VERSION "0.1"

NS_ :

BS_:

BU_: HVSC Delphi_U2C NLG5 BCM VCL

BO_ 1556 NLG5_ERR: 5 NLG5
 SG_ NLG5_W_PL_MV : 39|1@0+ (1,0) [0|1] ""  HVSC
 SG_ NLG5_W_PL_IT : 37|1@0+ (1,0) [0|1] ""  HVSC
 SG_ NLG5_W_PL_BV : 38|1@0+ (1,0) [0|1] ""  HVSC
 SG_ NLG5_W_C_VOR : 36|1@0+ (1,0) [0|1] ""  HVSC
 SG_ NLG5_E_WDT : 19|1@0+ (1,0) [0|1] ""  HVSC
 SG_ NLG5_E_T_TR : 11|1@0+ (1,0) [0|1] ""  HVSC
 SG_ NLG5_E_T_POW : 13|1@0+ (1,0) [0|1] ""  HVSC
 SG_ NLG5_E_T_EXT3 : 8|1@0+ (1,0) [0|1] ""  HVSC
 SG_ NLG5_E_T_EXT2 : 9|1@0+ (1,0) [0|1] ""  HVSC
 SG_ NLG5_E_T_EXT1 : 10|1@0+ (1,0) [0|1] ""  HVSC
 SG_ NLG5_E_T_DIO : 12|1@0+ (1,0) [0|1] ""  HVSC
 SG_ NLG5_E_T_C : 14|1@0+ (1,0) [0|1] ""  HVSC
 SG_ NLG5_E_SDT_CT : 26|1@0+ (1,0) [0|1] ""  HVSC
 SG_ NLG5_E_SDT_BV : 28|1@0+ (1,0) [0|1] ""  HVSC
 SG_ NLG5_E_SDT_BT : 29|1@0+ (1,0) [0|1] ""  HVSC
 SG_ NLG5_E_SDT_AH : 27|1@0+ (1,0) [0|1] ""  HVSC
 SG_ NLG5_E_SC : 4|1@0+ (1,0) [0|1] ""  HVSC
 SG_ NLG5_E_P_OM : 3|1@0+ (1,0) [0|1] ""  HVSC
 SG_ NLG5_E_P_MV : 2|1@0+ (1,0) [0|1] ""  HVSC
 SG_ NLG5_E_OOV : 7|1@0+ (1,0) [0|1] ""  HVSC
 SG_ NLG5_E_OF : 1|1@0+ (1,0) [0|1] ""  HVSC
 SG_ NLG5_E_NV_CRC : 22|1@0+ (1,0) [0|1] ""  HVSC
 SG_ NLG5_E_MOV_II : 5|1@0+ (1,0) [0|1] ""  HVSC
 SG_ NLG5_E_MOV_I : 6|1@0+ (1,0) [0|1] ""  HVSC
 SG_ NLG5_E_MF : 0|1@0+ (1,0) [0|1] ""  HVSC
 SG_ NLG5_E_INIT : 18|1@0+ (1,0) [0|1] ""  HVSC
 SG_ NLG5_E_F_CRC : 23|1@0+ (1,0) [0|1] ""  HVSC
 SG_ NLG5_E_ES_CRC : 21|1@0+ (1,0) [0|1] ""  HVSC
 SG_ NLG5_E_EP_CRC : 20|1@0+ (1,0) [0|1] ""  HVSC
 SG_ NLG5_E_C_TX : 31|1@0+ (1,0) [0|1] ""  HVSC
 SG_ NLG5_E_C_TO : 17|1@0+ (1,0) [0|1] ""  HVSC
 SG_ NLG5_E_C_RX : 30|1@0+ (1,0) [0|1] ""  HVSC
 SG_ NLG5_E_C_OFF : 16|1@0+ (1,0) [0|1] ""  HVSC
 SG_ NLG5_E_B_P : 15|1@0+ (1,0) [0|1] ""  HVSC

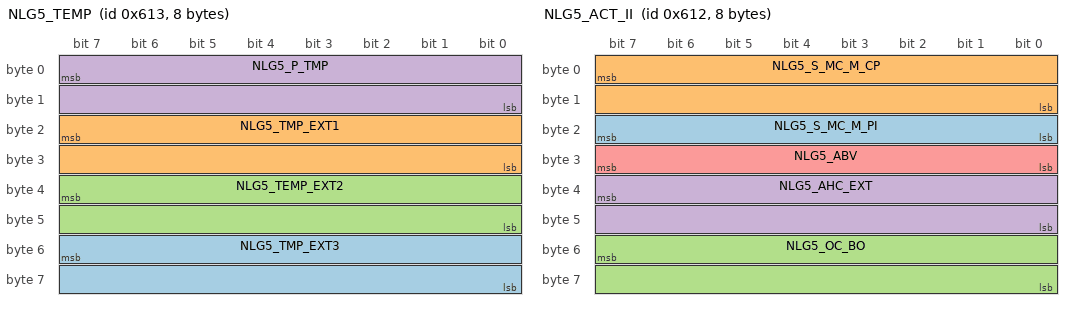
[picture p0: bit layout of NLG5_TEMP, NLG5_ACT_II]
BO_ 1555 NLG5_TEMP: 8 NLG5
 SG_ NLG5_TMP_EXT3 : 55|16@0- (0.1,0) [-40|300] "°C"  HVSC
 SG_ NLG5_TMP_EXT1 : 23|16@0- (0.1,0) [-40|300] "°C"  HVSC
 SG_ NLG5_TEMP_EXT2 : 39|16@0- (0.1,0) [-40|300] "°C"  HVSC
 SG_ NLG5_P_TMP : 7|16@0- (0.1,0) [-40|300] "°C"  HVSC

BO_ 1554 NLG5_ACT_II: 8 NLG5
 SG_ NLG5_S_MC_M_PI : 23|8@0+ (0.1,0) [0|20] "A"  HVSC
 SG_ NLG5_S_MC_M_CP : 7|16@0+ (0.1,0) [0|100] "A"  HVSC
 SG_ NLG5_OC_BO : 55|16@0+ (0.01,0) [0|50] "A"  HVSC
 SG_ NLG5_AHC_EXT : 39|16@0- (0.01,0) [-327.68|327.67] "Ah"  HVSC
 SG_ NLG5_ABV : 31|8@0+ (0.1,0) [0|25] "V"  HVSC

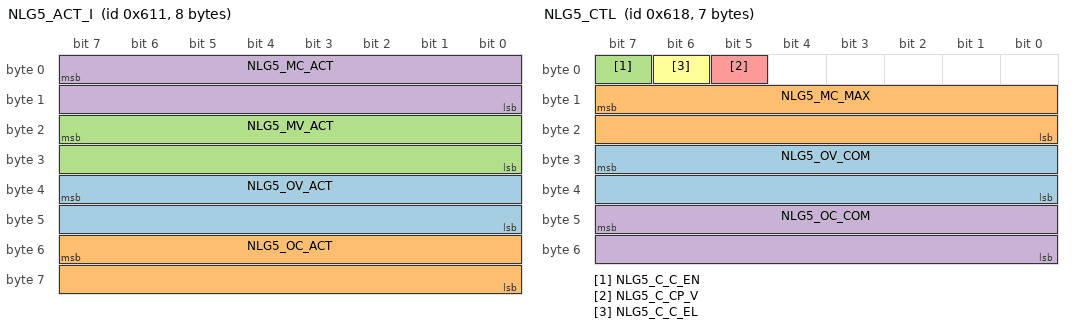
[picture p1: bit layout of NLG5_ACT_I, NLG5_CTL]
BO_ 1553 NLG5_ACT_I: 8 NLG5
 SG_ NLG5_OV_ACT : 39|16@0+ (0.1,0) [0|1000] "V"  HVSC
 SG_ NLG5_OC_ACT : 55|16@0- (0.01,0) [0|150] "A"  HVSC
 SG_ NLG5_MV_ACT : 23|16@0+ (0.1,0) [0|500] "V"  HVSC
 SG_ NLG5_MC_ACT : 7|16@0+ (0.01,0) [0|50] "A"  HVSC

BO_ 1552 NLG5_ST: 4 NLG5
 SG_ NLG5_S_WAR : 5|1@0+ (1,0) [0|1] ""  HVSC
 SG_ NLG5_S_UM_II : 1|1@0+ (1,0) [0|1] ""  HVSC
 SG_ NLG5_S_UM_I : 2|1@0+ (1,0) [0|1] ""  HVSC
 SG_ NLG5_S_HE : 7|1@0+ (1,0) [0|1] ""  HVSC
 SG_ NLG5_S_L_T_TR : 17|1@0+ (1,0) [0|1] ""  HVSC
 SG_ NLG5_S_L_T_POW : 19|1@0+ (1,0) [0|1] ""  HVSC
 SG_ NLG5_S_L_T_DIO : 18|1@0+ (1,0) [0|1] ""  HVSC
 SG_ NLG5_S_L_T_CPRIM : 20|1@0+ (1,0) [0|1] ""  HVSC
 SG_ NLG5_S_L_T_BATT : 16|1@0+ (1,0) [0|1] ""  HVSC
 SG_ NLG5_S_L_PMAX : 8|1@0+ (1,0) [0|1] ""  HVSC
 SG_ NLG5_S_L_PI : 10|1@0+ (1,0) [0|1] ""  HVSC
 SG_ NLG5_S_L_OV : 13|1@0+ (1,0) [0|1] ""  HVSC
 SG_ NLG5_S_L_OC_MAX : 22|1@0+ (1,0) [0|1] ""  HVSC
 SG_ NLG5_S_L_OC : 12|1@0+ (1,0) [0|1] ""  HVSC
 SG_ NLG5_S_L_MO_MAX : 21|1@0+ (1,0) [0|1] ""  HVSC
 SG_ NLG5_S_L_MC_MAX : 23|1@0+ (1,0) [0|1] ""  HVSC
 SG_ NLG5_S_L_MC : 11|1@0+ (1,0) [0|1] ""  HVSC
 SG_ NLG5_S_L_CP : 9|1@0+ (1,0) [0|1] ""  HVSC
 SG_ NLG5_S_FAN : 4|1@0+ (1,0) [0|1] ""  HVSC
 SG_ NLG5_S_EUM : 3|1@0+ (1,0) [0|1] ""  HVSC
 SG_ NLG5_S_ERR : 6|1@0+ (1,0) [0|1] ""  HVSC
 SG_ NLG5_S_CP_DT : 0|1@0+ (1,0) [0|1] ""  HVSC
 SG_ NLG5_S_BPD_II : 14|1@0+ (1,0) [0|1] ""  HVSC
 SG_ NLG5_S_BPD_I : 15|1@0+ (1,0) [0|1] ""  HVSC

BO_ 1560 NLG5_CTL: 7 HVSC
 SG_ NLG5_OV_COM : 31|16@0+ (0.1,0) [0|1000] "V"  NLG5
 SG_ NLG5_MC_MAX : 15|16@0+ (0.1,0) [0|50] "A"  NLG5
 SG_ NLG5_C_C_EN : 7|1@0+ (1,0) [0|1] ""  NLG5
 SG_ NLG5_OC_COM : 47|16@0+ (0.1,0) [0|150] "A"  NLG5
 SG_ NLG5_C_CP_V : 5|1@0+ (1,0) [0|1] ""  NLG5
 SG_ NLG5_C_C_EL : 6|1@0+ (1,0) [0|1] ""  NLG5

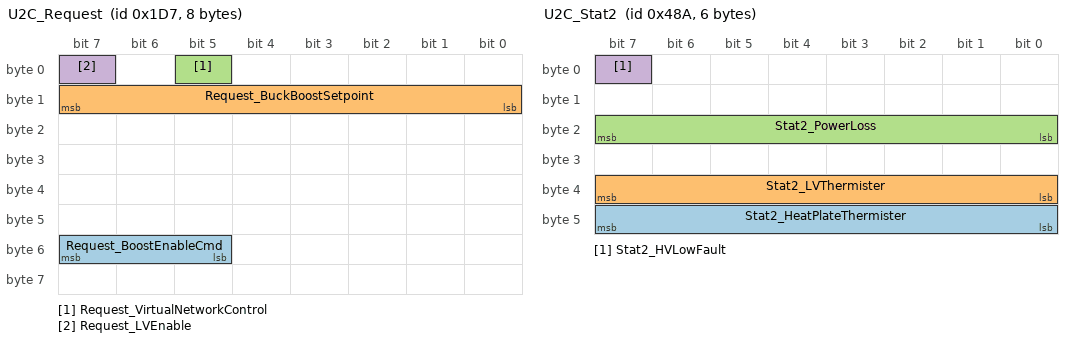
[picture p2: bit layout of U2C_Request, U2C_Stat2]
BO_ 471 U2C_Request: 8 HVSC
 SG_ Request_BoostEnableCmd : 53|3@1- (1,0) [0|0] ""  Delphi_U2C
 SG_ Request_BuckBoostSetpoint : 8|8@1+ (1,0) [0|255] ""  Delphi_U2C
 SG_ Request_VirtualNetworkControl : 5|1@1- (1,0) [0|0] ""  Delphi_U2C
 SG_ Request_LVEnable : 7|1@1- (1,0) [0|0] ""  Delphi_U2C

BO_ 1162 U2C_Stat2: 6 Delphi_U2C
 SG_ Stat2_HeatPlateThermister : 40|8@1- (1,-40) [0|0] ""  HVSC
 SG_ Stat2_LVThermister : 32|8@1- (1,-40) [0|0] ""  HVSC
 SG_ Stat2_PowerLoss : 16|8@1- (2,0) [0|0] "Watts"  HVSC
 SG_ Stat2_HVLowFault : 7|1@1- (1,0) [0|0] ""  HVSC

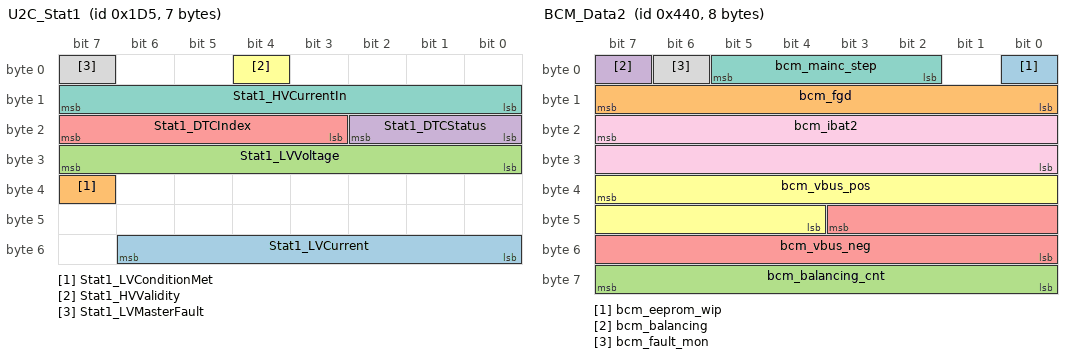
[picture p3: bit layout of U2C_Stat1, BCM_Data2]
BO_ 469 U2C_Stat1: 7 Delphi_U2C
 SG_ Stat1_LVCurrent : 48|7@1+ (2,0) [0|254] "Amps"  HVSC
 SG_ Stat1_LVConditionMet : 39|1@1+ (1,0) [0|1] ""  HVSC
 SG_ Stat1_LVVoltage : 24|8@1+ (0.078431,0) [0|0] "Volts"  HVSC
 SG_ Stat1_DTCStatus : 16|3@1+ (1,0) [0|7] ""  HVSC
 SG_ Stat1_DTCIndex : 19|5@1+ (1,0) [0|31] ""  HVSC
 SG_ Stat1_HVValidity : 4|1@1+ (1,0) [0|1] ""  HVSC
 SG_ Stat1_HVCurrentIn : 8|8@1+ (0.1,0) [0|0] "Amps"  HVSC
 SG_ Stat1_LVMasterFault : 7|1@1+ (1,0) [0|1] ""  HVSC

BO_ 1088 BCM_Data2: 8 BCM
 SG_ bcm_eeprom_wip : 0|1@0+ (1,0) [0|1] "flag"  VCL
 SG_ bcm_fgd : 15|8@0+ (0.5,0) [0|100] "% Duty Cycle"  VCL
 SG_ bcm_balancing_cnt : 63|8@0+ (1,0) [0|250] "cells"  VCL
 SG_ bcm_balancing : 7|1@0+ (1,0) [0|1] "flag"  VCL
 SG_ bcm_vbus_neg : 43|12@0+ (0.25,-500) [-500|500] "volts"  VCL
 SG_ bcm_vbus_pos : 39|12@0+ (0.25,0) [0|1000] "volts"  VCL
 SG_ bcm_mainc_step : 5|4@0+ (1,0) [0|15] "enum"  VCL
 SG_ bcm_fault_mon : 6|1@0+ (1,0) [0|1] "flag"  VCL
 SG_ bcm_ibat2 : 23|16@0+ (0.025,-1000) [-1000|500] "amps"  VCL

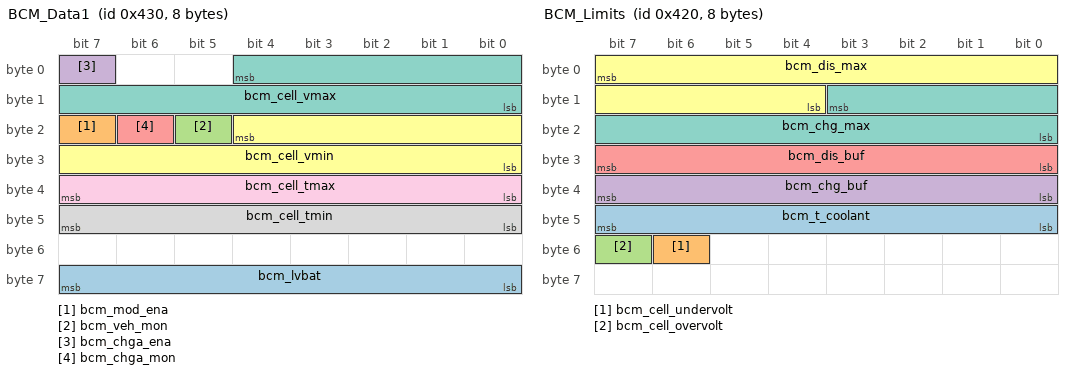
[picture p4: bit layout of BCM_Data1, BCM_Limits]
BO_ 1072 BCM_Data1: 8 BCM
 SG_ bcm_lvbat : 63|8@0+ (0.1,0) [0|25] "Volts" Vector__XXX
 SG_ bcm_mod_ena : 23|1@0+ (1,0) [0|1] "flag" Vector__XXX
 SG_ bcm_veh_mon : 21|1@0+ (1,0) [0|1] "flag" Vector__XXX
 SG_ bcm_chga_ena : 7|1@0+ (1,0) [0|1] "flag" Vector__XXX
 SG_ bcm_chga_mon : 22|1@0+ (1,0) [0|1] "flag" Vector__XXX
 SG_ bcm_cell_vmin : 20|13@0+ (0.001,0) [0|5] "volts"  VCL
 SG_ bcm_cell_vmax : 4|13@0+ (0.001,0) [0|5] "volts"  VCL
 SG_ bcm_cell_tmin : 47|8@0+ (0.5,-40) [-40|85] "DegC"  VCL
 SG_ bcm_cell_tmax : 39|8@0+ (0.5,-40) [-40|85] "DegC"  VCL

BO_ 1056 BCM_Limits: 8 BCM
 SG_ bcm_t_coolant : 47|8@0+ (0.5,-40) [-40|85] "DegC"  VCL
 SG_ bcm_cell_undervolt : 54|1@0+ (1,0) [0|1] "flag" Vector__XXX
 SG_ bcm_cell_overvolt : 55|1@0+ (1,0) [0|1] "flag" Vector__XXX
 SG_ bcm_chg_buf : 39|8@0+ (0.5,0) [0|100] "%" Vector__XXX
 SG_ bcm_dis_buf : 31|8@0+ (0.5,0) [0|100] "%" Vector__XXX
 SG_ bcm_dis_max : 7|12@0+ (0.25,0) [0|1000] "amps"  VCL,HVSC
 SG_ bcm_chg_max : 11|12@0+ (0.25,0) [0|1000] "amps"  VCL,HVSC

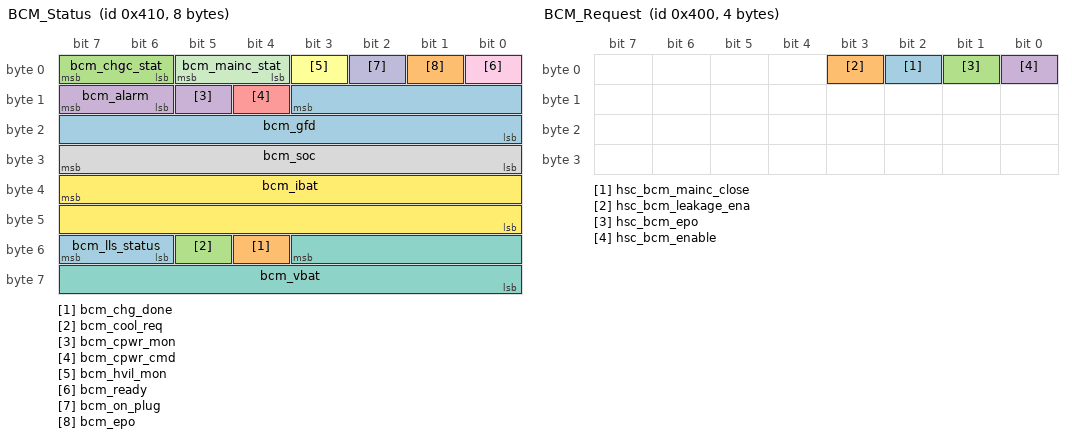
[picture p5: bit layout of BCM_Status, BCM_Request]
BO_ 1040 BCM_Status: 8 BCM
 SG_ bcm_lls_status : 55|2@0+ (1,0) [0|3] "state" Vector__XXX
 SG_ bcm_chg_done : 52|1@0+ (1,0) [0|1] "flag" Vector__XXX
 SG_ bcm_cool_req : 53|1@0+ (1,0) [0|1] "flag" Vector__XXX
 SG_ bcm_cpwr_mon : 13|1@0+ (1,0) [0|1] "flag" Vector__XXX
 SG_ bcm_cpwr_cmd : 12|1@0+ (1,0) [0|1] "flag" Vector__XXX
 SG_ bcm_hvil_mon : 3|1@0+ (1,0) [0|1] "flag" Vector__XXX
 SG_ bcm_vbat : 51|12@0+ (0.25,0) [0|1000] "volts"  VCL,HVSC
 SG_ bcm_soc : 31|8@0+ (0.5,0) [0|100] "%"  VCL,HVSC
 SG_ bcm_ready : 0|1@0+ (1,0) [0|1] "flag"  VCL,HVSC
 SG_ bcm_on_plug : 2|1@0+ (1,0) [0|1] "flag"  VCL,HVSC
 SG_ bcm_mainc_stat : 5|2@0+ (1,0) [0|2] "enum"  VCL,HVSC
 SG_ bcm_ibat : 39|16@0+ (0.025,-1000) [-1000|500] "amps"  VCL,HVSC
 SG_ bcm_gfd : 11|12@0+ (0.25,0) [0|1000] "kOhm"  VCL,HVSC
 SG_ bcm_epo : 1|1@0+ (1,0) [0|1] "flag"  VCL,HVSC
 SG_ bcm_chgc_stat : 7|2@0+ (1,0) [0|2] "enum"  VCL,HVSC
 SG_ bcm_alarm : 15|2@0+ (1,0) [0|3] "enum"  VCL,HVSC

BO_ 1024 BCM_Request: 4 HVSC
 SG_ hsc_bcm_mainc_close : 2|1@0+ (1,0) [0|1] "flag"  VCL,BCM
 SG_ hsc_bcm_leakage_ena : 3|1@0+ (1,0) [0|1] "flag"  VCL,BCM
 SG_ hsc_bcm_epo : 1|1@0+ (1,0) [0|1] "flag"  VCL,BCM
 SG_ hsc_bcm_enable : 0|1@0+ (1,0) [0|1] "flag"  VCL,BCM

BO_ 1120 BCM_Faults: 8 BCM
 SG_ bcm_dtc_type3 m0 : 47|8@0+ (1,0) [0|255] "DTCs"  HVSC
 SG_ bcm_dtc_type2 m0 : 39|8@0+ (1,0) [0|255] "DTCs"  HVSC
 SG_ bcm_dtc_type1 m0 : 31|8@0+ (1,0) [0|255] "DTCs"  HVSC
 SG_ bcm_dtc_testFailedThisOpCycle m0 : 55|8@0+ (1,0) [0|255] "DTCs"  HVSC
 SG_ bcm_dtc_pages m0 : 23|8@0+ (1,0) [0|255] "page count"  HVSC
 SG_ bcm_dtc_fault_detected m0 : 63|8@0+ (1,0) [0|255] "DTCs"  HVSC
 SG_ bcm_dtc_001 m1 : 23|24@0+ (1,0) [0|16777215] "DTC ID"  HVSC
 SG_ bcm_dtc_002 m1 : 47|24@0+ (1,0) [0|16777215] "DTC ID"  HVSC
 SG_ bcm_dtc_003 m2 : 23|24@0+ (1,0) [0|16777215] "DTC ID"  HVSC
 SG_ bcm_dtc_004 m2 : 47|24@0+ (1,0) [0|16777215] "DTC ID"  HVSC
 SG_ bcm_dtc_005 m3 : 23|24@0+ (1,0) [0|16777215] "DTC ID"  HVSC
 SG_ bcm_dtc_006 m3 : 47|24@0+ (1,0) [0|16777215] "DTC ID"  HVSC
 SG_ bcm_dtc_007 m4 : 23|24@0+ (1,0) [0|16777215] "DTC ID"  HVSC
 SG_ bcm_dtc_008 m4 : 47|24@0+ (1,0) [0|16777215] "DTC ID"  HVSC
 SG_ bcm_dtc_009 m5 : 23|24@0+ (1,0) [0|16777215] "DTC ID"  HVSC
 SG_ bcm_dtc_010 m5 : 47|24@0+ (1,0) [0|16777215] "DTC ID"  HVSC
 SG_ bcm_dtc_011 m6 : 23|24@0+ (1,0) [0|16777215] "DTC ID"  HVSC
 SG_ bcm_dtc_012 m6 : 47|24@0+ (1,0) [0|16777215] "DTC ID"  HVSC
 SG_ bcm_dtc_013 m7 : 23|24@0+ (1,0) [0|16777215] "DTC ID"  HVSC
 SG_ bcm_dtc_014 m7 : 47|24@0+ (1,0) [0|16777215] "DTC ID"  HVSC
 SG_ bcm_dtc_015 m8 : 23|24@0+ (1,0) [0|16777215] "DTC ID"  HVSC
 SG_ bcm_dtc_016 m8 : 47|24@0+ (1,0) [0|16777215] "DTC ID"  HVSC
 SG_ bcm_dtc_017 m9 : 23|24@0+ (1,0) [0|16777215] "DTC ID"  HVSC
 SG_ bcm_dtc_018 m9 : 47|24@0+ (1,0) [0|16777215] "DTC ID"  HVSC
 SG_ bcm_dtc_page M : 7|8@0+ (1,0) [0|255] "page number"  HVSC

CM_ SG_ 1556 NLG5_W_PL_MV "Output power limited by low mains voltage";
CM_ SG_ 1556 NLG5_W_PL_IT "Output power limited by charger internal overtemperature";
CM_ SG_ 1556 NLG5_W_PL_BV "Output power limited by low battery voltage";
CM_ SG_ 1556 NLG5_W_C_VOR "Commanded value is out of specified range; max or min applicable value is assumed instead";
CM_ SG_ 1556 NLG5_E_WDT "Internal Watchdog Timeout";
CM_ SG_ 1556 NLG5_E_T_TR "Temperature sensor for transformer defective";
CM_ SG_ 1556 NLG5_E_T_POW "Temperature sensor for prim power stage defective";
CM_ SG_ 1556 NLG5_E_T_EXT3 "Ext. temperature sensor 3 defective (if enabled)";
CM_ SG_ 1556 NLG5_E_T_EXT2 "Ext. temperature sensor 2 defective (if enabled)";
CM_ SG_ 1556 NLG5_E_T_EXT1 "Ext. temperature sensor 1 defective (if enabled)";
CM_ SG_ 1556 NLG5_E_T_DIO "Temperature sensor for diodes defective";
CM_ SG_ 1556 NLG5_E_T_C "Temperature sensor for prim capacitor defective";
CM_ SG_ 1556 NLG5_E_SDT_CT "Emergency Shutdown Threshold 'Charging Time' is exceeded; see ChargeStar help section 'protective features';  error can only be cleared by cycling power ON-OFF-ON";
CM_ SG_ 1556 NLG5_E_SDT_BV "Emergency Shutdown Threshold 'Battery Voltage' is exceeded; see ChargeStar help section 'protective features';  error can only be cleared by cycling power ON-OFF-ON";
CM_ SG_ 1556 NLG5_E_SDT_BT "Emergency Shutdown Threshold 'Battery Temperature' is exceeded; see ChargeStar help section 'protective features';  error can only be cleared by cycling power ON-OFF-ON";
CM_ SG_ 1556 NLG5_E_SDT_AH "Emergency Shutdown Threshold 'Amp Hours' is exceeded; see ChargeStar help section 'protective features';  error can only be cleared by cycling power ON-OFF-ON";
CM_ SG_ 1556 NLG5_E_SC "power stage short circuit condition detected; error can only be cleared by cycling power ON-OFF-ON";
CM_ SG_ 1556 NLG5_E_P_OM "plausibility battery output voltage measurement wrong";
CM_ SG_ 1556 NLG5_E_P_MV "plausibility mains voltage measurement wrong";
CM_ SG_ 1556 NLG5_E_OOV "battery output overvoltage; error can only be cleared by cycling power ON-OFF-ON ";
CM_ SG_ 1556 NLG5_E_OF "output fuse defective";
CM_ SG_ 1556 NLG5_E_NV_CRC "NVSRAM check sum failure; contains most of the scaling & calibration values, CAN ID's and  charging profile etc.";
CM_ SG_ 1556 NLG5_E_MOV_II "Mains overvoltage 2 detected";
CM_ SG_ 1556 NLG5_E_MOV_I "Mains overvoltage 1 detected";
CM_ SG_ 1556 NLG5_E_MF "Mains fuse defective";
CM_ SG_ 1556 NLG5_E_INIT "Initialization error";
CM_ SG_ 1556 NLG5_E_F_CRC "Flash memory checksum failure";
CM_ SG_ 1556 NLG5_E_ES_CRC "Sys EEPROM checksum failure";
CM_ SG_ 1556 NLG5_E_EP_CRC "Pow EEPROM checksum failure";
CM_ SG_ 1556 NLG5_E_C_TX "CAN transmit buffer >127";
CM_ SG_ 1556 NLG5_E_C_TO "CAN timeout, no control message received for >300ms";
CM_ SG_ 1556 NLG5_E_C_RX "CAN receiver buffer >127";
CM_ SG_ 1556 NLG5_E_C_OFF "CAN off, transmit buffer >255";
CM_ SG_ 1556 NLG5_E_B_P "wrong battery polarity;  error can only be cleared by cycling power ON-OFF-ON";
CM_ SG_ 1555 NLG5_TMP_EXT3 "Value of external battery temperature sensor #3 (if connected and enabled)";
CM_ SG_ 1555 NLG5_TMP_EXT1 "Value of external battery temperature sensor #1 (if connected and enabled)";
CM_ SG_ 1555 NLG5_TEMP_EXT2 "Value of external battery temperature sensor #2 (if connected and enabled)";
CM_ SG_ 1555 NLG5_P_TMP "Power stage temperature";
CM_ SG_ 1554 NLG5_S_MC_M_PI "Value of mains current limit, commanded by the 'power indicator' (PI) analog input signal";
CM_ SG_ 1554 NLG5_S_MC_M_CP "Value of mains current limit, commanded by the control pilot (SAE J1772) signal";
CM_ SG_ 1554 NLG5_OC_BO "output current of the booster (if one is present and active)";
CM_ SG_ 1554 NLG5_AHC_EXT "Charge balance obtained via  Ext. Ah counter connected to DI1 / DI2";
CM_ SG_ 1554 NLG5_ABV "Aux battery voltage";
CM_ SG_ 1553 NLG5_OV_ACT "Actual battery output voltage";
CM_ SG_ 1553 NLG5_OC_ACT "output current to the battery";
CM_ SG_ 1553 NLG5_MV_ACT "Actual mains voltage";
CM_ SG_ 1553 NLG5_MC_ACT "Actual mains current";
CM_ SG_ 1552 NLG5_S_WAR "Warning condition on, i.e. charging power limited due to any limiting condition; red LED is blinking";
CM_ SG_ 1552 NLG5_S_UM_II "US mains level 2 (240VAC / 60Hz) detected";
CM_ SG_ 1552 NLG5_S_UM_I "US mains level 1 (120VAC / 60Hz) detected";
CM_ SG_ 1552 NLG5_S_HE "Indicates if hardware enabled, i.e. a hi or lo signal is fed to the 'Power On' pin (pin3 of control connector)";
CM_ SG_ 1552 NLG5_S_L_T_TR "Output power limited by temperature of transformer";
CM_ SG_ 1552 NLG5_S_L_T_POW "Output power limited by temperature of power stage";
CM_ SG_ 1552 NLG5_S_L_T_DIO "Output power limited by temperature of diodes";
CM_ SG_ 1552 NLG5_S_L_T_CPRIM "Output power limited by temperature of primary capacitors";
CM_ SG_ 1552 NLG5_S_L_T_BATT "Output power limited by battery temperature";
CM_ SG_ 1552 NLG5_S_L_PMAX "Output power limited by maximum power capability of NLG5";
CM_ SG_ 1552 NLG5_S_L_PI "Output power limited by analog input 'power indicator' (PI) limit";
CM_ SG_ 1552 NLG5_S_L_OV "Output power limited by battery output voltage limit";
CM_ SG_ 1552 NLG5_S_L_OC_MAX "Output power limited by maximum output current capability of NLG5";
CM_ SG_ 1552 NLG5_S_L_OC "Output power limited by battery output current limit";
CM_ SG_ 1552 NLG5_S_L_MO_MAX "Output power limited by maximum output voltage capability of NLG5";
CM_ SG_ 1552 NLG5_S_L_MC_MAX "Output power limited by maximum mains current capability of NLG5";
CM_ SG_ 1552 NLG5_S_L_MC "Output power limited by mains current limit";
CM_ SG_ 1552 NLG5_S_L_CP "Output power limited by control pilot signal (SAE J1772)";
CM_ SG_ 1552 NLG5_S_FAN "Charger cooling fan is active";
CM_ SG_ 1552 NLG5_S_EUM "European mains input detected (230V, 50Hz)";
CM_ SG_ 1552 NLG5_S_ERR "An error has been detected, red LED is ON, no power is output";
CM_ SG_ 1552 NLG5_S_CP_DT "Control pilot signal (SAE J1772) detected ";
CM_ SG_ 1552 NLG5_S_BPD_II "Bypass detection bit 2; 00: no bypass, 01: DC bypass detected, 10:AC bypass in phase, 11: AC bypass not in phase";
CM_ SG_ 1552 NLG5_S_BPD_I "Bypass detection bit 1; 00: no bypass, 01: DC bypass detected, 10:AC bypass in phase, 11: AC bypass not in phase";
CM_ SG_ 1560 NLG5_OV_COM "Desired voltage to be output to the battery. Must always contain a valid value in order to keep on charging.";
CM_ SG_ 1560 NLG5_MC_MAX "Maximum current to be drawn from the mains outlet, usually 16A. Must always contain a valid value in order to keep on charging.";
CM_ SG_ 1560 NLG5_C_C_EN "Must be ON to enable power stage of the charger";
CM_ SG_ 1560 NLG5_OC_COM "Desired battery current. Must always contain a valid value in order to keep on charging.";
CM_ SG_ 1560 NLG5_C_CP_V "special signal to tell a charging station equipped with the Control Pilot interface (SAE J1772) to switch on the facility's ventilation (in order to get rid of battery gases like hydrogen, e.g.)";
CM_ SG_ 1560 NLG5_C_C_EL "cycle this value 0-1-0 to clear all latched charger errors ";
CM_ SG_ 471 Request_BoostEnableCmd "Selects Boost conversion on/off";
CM_ SG_ 471 Request_BuckBoostSetpoint "CAN byte (dec) = (Buck Target Voltage * 45.3329) - 473.161";
CM_ SG_ 1088 bcm_eeprom_wip "BCM fault status: EEPROM write in progress.";
CM_ SG_ 1088 bcm_fgd "Flammable gas detector duty cycle (most severe).";
CM_ SG_ 1088 bcm_balancing_cnt "Number of cells currently balancing.";
CM_ SG_ 1088 bcm_balancing "Charge balance circuits are active.";
CM_ SG_ 1088 bcm_vbus_neg "HV bus negative voltage measurement.";
CM_ SG_ 1088 bcm_vbus_pos "HV bus positive voltage measurement.";
CM_ SG_ 1088 bcm_mainc_step "Main contactor control state enumeration.";
CM_ SG_ 1088 bcm_fault_mon "Module Fault monitor, indicates if of the modules triggered a hardware based fault (0=low, 1=high).";
CM_ SG_ 1088 bcm_ibat2 "[Development Sensor] HV Battery Current where negative is battery discharge and positive is battery charge.";
CM_ SG_ 1072 bcm_lvbat "SLI Battery Voltage.";
CM_ SG_ 1072 bcm_mod_ena "Module 12V enable command (0=off, 1=on).";
CM_ SG_ 1072 bcm_veh_mon "Vehicle wakeup monitor (0=low, 1=high).";
CM_ SG_ 1072 bcm_chga_ena "Charger enable command (0=off, 1=on).";
CM_ SG_ 1072 bcm_chga_mon "Charger AC wakeup monitor (0=low, 1=high).";
CM_ SG_ 1072 bcm_cell_vmin "Min cell voltage.";
CM_ SG_ 1072 bcm_cell_vmax "Max cell voltage.";
CM_ SG_ 1072 bcm_cell_tmin "Min cell case temperature.";
CM_ SG_ 1072 bcm_cell_tmax "Max cell case temperature.";
CM_ SG_ 1056 bcm_t_coolant "Battery coolant temperature sensor value.";
CM_ SG_ 1056 bcm_cell_undervolt "One or more cells are below normal voltage range.";
CM_ SG_ 1056 bcm_cell_overvolt "One or more cells are above normal voltage range.";
CM_ SG_ 1056 bcm_chg_buf "Transient acceptance indicator, how soon before the BCM will start to limit it's max charge current.
100% - large buffer to accept charge up to bcm_chg_max.
0% - bcm_chg_max is being reduced to steady-state level.";
CM_ SG_ 1056 bcm_dis_buf "Transient acceptance indicator, how soon before the BCM will start to limit it's max discharge current.
100% - large buffer to accept discharge up to bcm_dis_max.
0% - bcm_dis_max is being reduced to steady-state level.";
CM_ SG_ 1056 bcm_dis_max "Max allowed discharge current.";
CM_ SG_ 1056 bcm_chg_max "Max allowed charge current.";
CM_ SG_ 1040 bcm_lls_status "Liquid level sensor located mid-pack.  FAULT indicates that Liquid was detected within the pack.";
CM_ SG_ 1040 bcm_chg_done "Charging is complete.";
CM_ SG_ 1040 bcm_cool_req "Battey cell temperaure indicates cooling required, the vehicle should activate the cooling pump and target bcm_t_coolant <= 20C.";
CM_ SG_ 1040 bcm_cpwr_mon "Contactor Power Relay monitor (0=low, 1=high).";
CM_ SG_ 1040 bcm_cpwr_cmd "Contactor Power Relay command state (0=off, 1=on).";
CM_ SG_ 1040 bcm_hvil_mon "HVIL monitor (0=low, 1=high).";
CM_ SG_ 1040 bcm_vbat "HV Battery voltage measurement.";
CM_ SG_ 1040 bcm_soc "Battery State of Charge.";
CM_ SG_ 1040 bcm_ready "BCM completed Power On Self Test and is ready.";
CM_ SG_ 1040 bcm_on_plug "Charger is plugged into AC socket, use an an input to start/drive-away logic.";
CM_ SG_ 1040 bcm_mainc_stat "Main contactor status.";
CM_ SG_ 1040 bcm_ibat "HV Battery Current where negative is battery discharge and positive is battery charge.";
CM_ SG_ 1040 bcm_gfd "Ground fault detection result.";
CM_ SG_ 1040 bcm_epo "BCM Emergency Power Off status.";
CM_ SG_ 1040 bcm_chgc_stat "Charge contactor status.";
CM_ SG_ 1040 bcm_alarm "Alarm condition from the BCM indicating overall condition.";
CM_ SG_ 1024 hsc_bcm_mainc_close "Vehicle main contactor command.";
CM_ SG_ 1024 hsc_bcm_leakage_ena "Vehicle leakage detection enabled (bcm_gfd calculation).";
CM_ SG_ 1024 hsc_bcm_epo "Vehicle Emergency Power Off command, fast shutdown.";
CM_ SG_ 1024 hsc_bcm_enable "Flag from vehicle controller allowing BCM to accept commands.";
BA_DEF_  "Bus Speed" STRING ;
BA_DEF_ SG_  "GenSigStartValue" INT 0 0;
BA_DEF_ SG_  "GenSigSendType" ENUM  "Cyclic","OnWrite","OnWriteWithRepetition","OnChange","OnChangeWithRepetition","IfActive","IfActiveWithRepetition","NoSigSendType";
BA_DEF_ BO_  "GenMsgCycleTime" INT 0 0;
BA_DEF_ BO_  "GenMsgSendType" ENUM  "Cyclic","not_used","not_used","not_used","not_used","Cyclic","not_used","IfActive","NoMsgSendType";
BA_DEF_  "DBName" STRING ;
BA_DEF_  "BusType" STRING ;
BA_DEF_DEF_  "Bus Speed" "500k";
BA_DEF_DEF_  "GenSigStartValue" 0;
BA_DEF_DEF_  "GenSigSendType" "Cyclic";
BA_DEF_DEF_  "GenMsgCycleTime" 10;
BA_DEF_DEF_  "GenMsgSendType" "NoMsgSendType";
BA_DEF_DEF_  "DBName" "HybridExpansion";
BA_DEF_DEF_  "BusType" "CAN";
BA_ "GenSigStartValue" SG_ 1072 bcm_cell_tmin 130;
BA_ "GenSigStartValue" SG_ 1072 bcm_cell_tmax 130;
VAL_ 471 Request_BoostEnableCmd 5 "Aborted" 4 "Complete" 3 "Active" 2 "Ready" 1 "Required" 0 "Inactive" ;
VAL_ 469 Stat1_DTCStatus 4 "Diagnostic Failed" 3 "Diagnostic Passed" 2 "No Status to Report" 1 "Critically Disabled" 0 "Not Supported" ;
VAL_ 469 Stat1_DTCIndex 31 "Reserved" 30 "Reserved" 29 "Reserved" 28 "Reserved" 27 "Reserved" 26 "Reserved" 25 "Reserved" 24 "Reserved" 23 "Reserved" 22 "Reserved" 21 "Reserved" 20 "Reserved" 19 "Reserved" 18 "ILIM Occured Indication" 17 "14V ILIM Diagnostic" 16 "Current Balance Diagnostic" 15 "14V Current Diagnostic" 14 "Heat Plate Temperature Fault" 13 "Loss of COM (3 Second Timeout)" 12 "Boost On Hi Voltage Fault - Low" 11 "Unused" 10 "Unused" 9 "Unused" 8 "Buck On Voltage Fault - Low" 7 "Low Voltage Fault - Low" 6 "Low Voltage Fault - High" 5 "Unused" 4 "Unused" 3 "High Voltage Fault - Low" 2 "High Voltage Fault - High" 1 "Unused" 0 "Low Voltage System Fault" ;
VAL_ 1088 bcm_fgd 255 "ERROR" 254 "NO_VALUE" ;
VAL_ 1088 bcm_balancing_cnt 255 "ERROR" 254 "NO_VALUE" ;
VAL_ 1088 bcm_vbus_neg 4095 "ERROR" 4094 "NO_VALUE" ;
VAL_ 1088 bcm_vbus_pos 4095 "ERROR" 4094 "NO_VALUE" ;
VAL_ 1088 bcm_mainc_step 14 "ALL_OPEN_SHUTDOWN" 13 "SHUTDOWN_REQUEST" 12 "MAIN_P_CLOSED_CHARGE" 11 "MAIN_PN_CLOSED_DRIVE" 10 "FAILED_MAINP_OPEN" 9 "OPEN_MAINR" 8 "CLOSE_MAINP" 7 "WAIT_PRECHARGE" 6 "FAILED_MAINN_OPEN" 5 "CLOSE_MAINN" 4 "FAILED_MAINN_WELD" 3 "FAILED_MAINR_OPEN" 2 "CLOSE_MAINR" 1 "FAILED_MAINP_OR_R_WELD" 0 "ALL_OPEN" ;
VAL_ 1088 bcm_ibat2 65534 "NO_VALUE" 65535 "ERROR" ;
VAL_ 1072 bcm_lvbat 255 "ERROR" 254 "NO_VALUE" ;
VAL_ 1072 bcm_cell_vmin 8191 "ERROR" 8190 "NO_VALUE" ;
VAL_ 1072 bcm_cell_vmax 8191 "ERROR" 8190 "NO_VALUE" ;
VAL_ 1072 bcm_cell_tmin 255 "ERROR" 254 "NO_VALUE" ;
VAL_ 1072 bcm_cell_tmax 255 "ERROR" 254 "NO_VALUE" ;
VAL_ 1056 bcm_t_coolant 255 "ERROR" 254 "NO_VALUE" ;
VAL_ 1056 bcm_chg_buf 255 "ERROR" 254 "NO_VALUE" ;
VAL_ 1056 bcm_dis_buf 255 "ERROR" 254 "NO_VALUE" ;
VAL_ 1056 bcm_dis_max 4095 "ERROR" 4094 "NO_VALUE" ;
VAL_ 1056 bcm_chg_max 4095 "ERROR" 4094 "NO_VALUE" ;
VAL_ 1040 bcm_lls_status 3 "OOR_HIGH" 2 "OOR_LOW" 1 "FAULT" 0 "OK" ;
VAL_ 1040 bcm_vbat 4095 "ERROR" 4094 "NO_VALUE" ;
VAL_ 1040 bcm_soc 255 "ERROR" 254 "NO_VALUE" ;
VAL_ 1040 bcm_mainc_stat 2 "FAILURE" 1 "CLOSED" 0 "OPEN" ;
VAL_ 1040 bcm_ibat 65534 "NO_VALUE" 65535 "ERROR" ;
VAL_ 1040 bcm_gfd 4095 "ERROR" 4094 "NO_VALUE" ;
VAL_ 1040 bcm_chgc_stat 2 "FAILURE" 1 "CLOSED" 0 "OPEN" ;
VAL_ 1040 bcm_alarm 3 "TYPE3" 2 "TYPE2" 1 "TYPE1" 0 "NONE" ;
VAL_ 1120 bcm_dtc_001 0 " - " 11276288 "DTC_VEPO" 11276289 "DTC_HSC_MISSING" 11460608 "DTC_NVM_SOC" 11460609 "DTC_NVM_KOT" 11460610 "DTC_NVM_DTC" 11460611 "DTC_NVM_SOC_CORRECTION" 11460612 "DTC_NVM_APP_SCRATCHPAD" 11517962 "DTC_LOOPTIME_TASK_A" 11517963 "DTC_LOOPTIME_TASK_B" 11517964 "DTC_LOOPTIME_TASK_C" 11517965 "DTC_LOOPTIME_TASK_D" 11517966 "DTC_LOOPTIME_TASK_E" 11517967 "DTC_LOOPTIME_TASK_F" 11323904 "DTC_INTERLOCK_A_FAILED_LOW" 11323905 "DTC_INTERLOCK_A_FAILED_HIGH" 11324160 "DTC_INTERLOCK_B_FAILED_LOW" 11324161 "DTC_INTERLOCK_B_FAILED_HIGH" 15728640 "DTC_EPO" 16498688 "DTC_BRUSA_MISSING" 16498689 "DTC_BRUSA_IDC" 16498690 "DTC_BRUSA_REQ_VS_CMD" 16433152 "DTC_AKERWADE_MISSING" 16433153 "DTC_AKERWADE_IDC" 16433154 "DTC_AKERWADE_REQ_VS_CMD" 16564224 "DTC_CHGLEAR_MISSING" 16564225 "DTC_CHGLEAR_IDC" 16564226 "DTC_CHGLEAR_REQ_VS_CMD" 16522240 "DTC_CSM_MISSING" 16522752 "DTC_CSM_VBAT" 16522753 "DTC_CSM_VPOS" 16522754 "DTC_CSM_VNEG" 16522755 "DTC_CSM_CPOS" 16522756 "DTC_CSM_CNEG" 16522757 "DTC_CSM_APOS" 16522758 "DTC_CSM_ANEG" 16522759 "DTC_CSM_FUSE_HI" 16522760 "DTC_CSM_FUSE_LO" 16521728 "DTC_CSM_ASIC" 16521729 "DTC_CSM_AILO" 16521730 "DTC_CSM_AIHI" 16520957 "DTC_LEAKAGE_DETECT_FAULT" 16522444 "DTC_REALTIMECLOCK_FAULT" 16520945 "DTC_CSM_LEAK_FAIL_CALC" 16520946 "DTC_CSM_LEAK_FAIL_HW" 16520947 "DTC_CSM_LEAK_EXT_SHORT" 16520948 "DTC_CSM_LEAK_MID_PACK_SHORT" 16520949 "DTC_CSM_LEAK_ERROR" 16520950 "DTC_CSM_LEAK_UNKNOWN" 16523008 "DTC_CSM_VER_MISMATCH" 16523009 "DTC_CSM_DTC_SET" 16523010 "DTC_CSM_CAL_FAULT" 16560128 "DTC_IBAT_MISMATCH" 16576512 "DTC_DIS_MAX_I2T" 16576513 "DTC_CHG_MAX_I2T" 16576768 "DTC_DIS_WARNING_I2T" 16576769 "DTC_CHG_WARNING_I2T" 11296784 "DTC_SAEJ1772_PROX_DECT_OOR_HI" 11296785 "DTC_SAEJ1772_PROX_DECT_OOR_LO" 11296800 "DTC_SAEJ1772_PILOT_PWM_OOR_HI" 11296801 "DTC_SAEJ1772_PILOT_PWM_OOR_LO" 11296802 "DTC_SAEJ1772_PILOT_PWM_DIG_COMM" 11296803 "DTC_SAEJ1772_PILOT_PWM_IR_ERR" 16175360 "DTC_FGD1_NO_SENSOR" 16175361 "DTC_FGD1_OOR_HI" 16175362 "DTC_FGD1_OOR_LO" 16175363 "DTC_FGD1_FAULT" 16175616 "DTC_FGD2_NO_SENSOR" 16175617 "DTC_FGD2_OOR_HI" 16175618 "DTC_FGD2_OOR_LO" 16175619 "DTC_FGD2_FAULT" 16171008 "DTC_CONT_OPEN" 16171009 "DTC_CONT_CLOSE" 16171010 "DTC_CONT_OPEN_CURRENT" 16171264 "DTC_CONT_CLOSE_ON_RESET" 16171265 "DTC_CONT_CLOSE_SIG_FAILED" 16171520 "DTC_PRECHARGE_TIMEOUT" 16171777 "DTC_CONT_MPOS_WELD_AT_SU" 16171778 "DTC_CONT_MNEG_WELD_AT_SU" 16171780 "DTC_CONT_CPOS_WELD_AT_SU" 16171781 "DTC_CONT_CNEG_WELD_AT_SU" 16171782 "DTC_CONT_ANEG_WELD_AT_SU" 16171783 "DTC_CONT_APOS_WELD_AT_SU" 16172033 "DTC_CONT_MPOS_WELD_AT_SD" 16172034 "DTC_CONT_MNEG_WELD_AT_SD" 16172036 "DTC_CONT_CPOS_WELD_AT_SD" 16172037 "DTC_CONT_CNEG_WELD_AT_SD" 16172038 "DTC_CONT_ANEG_WELD_AT_SD" 16172039 "DTC_CONT_APOS_WELD_AT_SD" 16172289 "DTC_CONT_MPOS_OPEN" 16172290 "DTC_CONT_MNEG_OPEN" 16172291 "DTC_CONT_MPRE_OPEN" 16172292 "DTC_CONT_CPOS_OPEN" 16172293 "DTC_CONT_CNEG_OPEN" 16172294 "DTC_CONT_APOS_OPEN" 16172295 "DTC_CONT_ANEG_OPEN" 16172545 "DTC_CONT_MPOS_VDIF" 16172546 "DTC_CONT_MNEG_VDIF" 16172548 "DTC_CONT_CPOS_VDIF" 16172549 "DTC_CONT_CNEG_VDIF" 16172550 "DTC_CONT_APOS_VDIF" 16172551 "DTC_CONT_ANEG_VDIF" 16174848 "DTC_HVIL" 16174849 "DTC_LVBAT_LO" 16174850 "DTC_LVBAT_HI" 16174851 "DTC_LVBAT_ERR" 16523520 "DTC_LEMLO_OOR_HI" 16523521 "DTC_LEMLO_OOR_LO" 16523522 "DTC_LEMLO_FAULT" 16523776 "DTC_LEMHI_OOR_HI" 16523777 "DTC_LEMHI_OOR_LO" 16523778 "DTC_LEMHI_FAULT" 16496320 "DTC_MBB_TOO_FEW" 16496321 "DTC_MBB_TOO_MANY" 16496352 "DTC_CELL_VMAX_ERR" 16496353 "DTC_CELL_VMIN_ERR" 16496354 "DTC_CELL_VMAX" 16496362 "DTC_CELL_VMAX_SEVERE" 16496355 "DTC_CELL_VMIN" 16496363 "DTC_CELL_VMIN_SEVERE" 16496356 "DTC_MOD_VOLTAGE_COMPARE" 16496336 "DTC_CELL_T_ERR" 16496337 "DTC_CELL_TMAX1" 16496338 "DTC_CELL_TMAX2" 16496339 "DTC_CELL_TMIN" 16497665 "DTC_MBB_01_MISSING" 16497666 "DTC_MBB_02_MISSING" 16497667 "DTC_MBB_03_MISSING" 16497668 "DTC_MBB_04_MISSING" 16497669 "DTC_MBB_05_MISSING" 16497670 "DTC_MBB_06_MISSING" 16497671 "DTC_MBB_07_MISSING" 16497672 "DTC_MBB_08_MISSING" 16497673 "DTC_MBB_09_MISSING" 16497680 "DTC_MBB_10_MISSING" 16497681 "DTC_MBB_11_MISSING" 16497682 "DTC_MBB_12_MISSING" 16497683 "DTC_MBB_13_MISSING" 16497684 "DTC_MBB_14_MISSING" 16497685 "DTC_MBB_15_MISSING" 16497686 "DTC_MBB_16_MISSING" 16497687 "DTC_MBB_17_MISSING" 16497688 "DTC_MBB_18_MISSING" 16497689 "DTC_MBB_19_MISSING" 16497696 "DTC_MBB_20_MISSING" 16497697 "DTC_MBB_21_MISSING" 16497698 "DTC_MBB_22_MISSING" 16497699 "DTC_MBB_23_MISSING" 16497700 "DTC_MBB_24_MISSING" 16498177 "DTC_MBB_01_VFAULT" 16498178 "DTC_MBB_02_VFAULT" 16498179 "DTC_MBB_03_VFAULT" 16498180 "DTC_MBB_04_VFAULT" 16498181 "DTC_MBB_05_VFAULT" 16498182 "DTC_MBB_06_VFAULT" 16498183 "DTC_MBB_07_VFAULT" 16498184 "DTC_MBB_08_VFAULT" 16498185 "DTC_MBB_09_VFAULT" 16498192 "DTC_MBB_10_VFAULT" 16498193 "DTC_MBB_11_VFAULT" 16498194 "DTC_MBB_12_VFAULT" 16498195 "DTC_MBB_13_VFAULT" 16498196 "DTC_MBB_14_VFAULT" 16498197 "DTC_MBB_15_VFAULT" 16498198 "DTC_MBB_16_VFAULT" 16498199 "DTC_MBB_17_VFAULT" 16498200 "DTC_MBB_18_VFAULT" 16498201 "DTC_MBB_19_VFAULT" 16498208 "DTC_MBB_20_VFAULT" 16498209 "DTC_MBB_21_VFAULT" 16498210 "DTC_MBB_22_VFAULT" 16498211 "DTC_MBB_23_VFAULT" 16498212 "DTC_MBB_24_VFAULT" 16497921 "DTC_MBB_01_TFAULT" 16497922 "DTC_MBB_02_TFAULT" 16497923 "DTC_MBB_03_TFAULT" 16497924 "DTC_MBB_04_TFAULT" 16497925 "DTC_MBB_05_TFAULT" 16497926 "DTC_MBB_06_TFAULT" 16497927 "DTC_MBB_07_TFAULT" 16497928 "DTC_MBB_08_TFAULT" 16497929 "DTC_MBB_09_TFAULT" 16497936 "DTC_MBB_10_TFAULT" 16497937 "DTC_MBB_11_TFAULT" 16497938 "DTC_MBB_12_TFAULT" 16497939 "DTC_MBB_13_TFAULT" 16497940 "DTC_MBB_14_TFAULT" 16497941 "DTC_MBB_15_TFAULT" 16497942 "DTC_MBB_16_TFAULT" 16497943 "DTC_MBB_17_TFAULT" 16497944 "DTC_MBB_18_TFAULT" 16497945 "DTC_MBB_19_TFAULT" 16497952 "DTC_MBB_20_TFAULT" 16497953 "DTC_MBB_21_TFAULT" 16497954 "DTC_MBB_22_TFAULT" 16497955 "DTC_MBB_23_TFAULT" 16497956 "DTC_MBB_24_TFAULT" 15785984 "DTC_PRECHARGE_ENERGY" 15785985 "DTC_PRT_FAILED" 15785986 "DTC_PRT_OVERTEMP" 15785987 "DTC_PRT_PROHIBIT" 16556032 "DTC_COOLANT_TEMP_OOR_HI" 16556033 "DTC_COOLANT_TEMP_OOR_LO" 16252928 "DTC_KEY_OFF_TIME_ERROR" 16506880 "DTC_VBAT_MISMATCH" 16506881 "DTC_VBAT_VMAX" 16506882 "DTC_VBAT_VMIN" 16506883 "DTC_PACK_FUSE" 15798544 "DTC_LLS1_OOR_HI" 15798545 "DTC_LLS1_OOR_LO" 15798546 "DTC_LLS1_FAULT" 15798816 "DTC_LLS2_OOR_HI" 15798817 "DTC_LLS2_OOR_LO" 15798818 "DTC_LLS2_FAULT" 14479360 "DTC_CFL_HEARTBEAT" 14479361 "DTC_CFL_FAULT" 14479362 "DTC_CFL_FAULT_LATCH" 13635584 "DTC_CONT_A_FAILED_HI" 13635585 "DTC_CONT_A_FAILED_LO" 13635586 "DTC_CONT_B_FAILED_HI" 13635587 "DTC_CONT_B_FAILED_LO" 13635588 "DTC_CONT_C_FAILED_HI" 13635589 "DTC_CONT_C_FAILED_LO" 13635590 "DTC_CONT_D_FAILED_HI" 13635591 "DTC_CONT_D_FAILED_LO" 13635592 "DTC_CONT_E_FAILED_HI" 13635593 "DTC_CONT_E_FAILED_LO" 13635594 "DTC_CONT_F_FAILED_HI" 13635595 "DTC_CONT_F_FAILED_LO" 13635596 "DTC_CONT_G_FAILED_HI" 13635597 "DTC_CONT_G_FAILED_LO" 13635598 "DTC_LSD_A_FAILED_HI" 13635599 "DTC_LSD_A_FAILED_LO" 13635600 "DTC_LSD_B_FAILED_HI" 13635601 "DTC_LSD_B_FAILED_LO" 13635602 "DTC_LSD_C_FAILED_HI" 13635603 "DTC_LSD_C_FAILED_LO" 13635606 "DTC_CONT_PWR_FAILED_HI" 13635607 "DTC_CONT_PWR_FAILED_LO" 13635608 "DTC_LSD_PUMP_FAILED_HI" 13635609 "DTC_LSD_PUMP_FAILED_LO" 13635610 "DTC_CHG_A_ENABLE_FAILED_HI" 13635611 "DTC_CHG_A_ENABLE_FAILED_LO" 13635612 "DTC_CHG_B_ENABLE_FAILED_HI" 13635613 "DTC_CHG_B_ENABLE_FAILED_LO" 13635614 "DTC_SW14V_PWR_FAILED_HI" 13635615 "DTC_SW14V_PWR_FAILED_LO" 13635620 "DTC_HSD_A_FAILED_HI" 13635621 "DTC_HSD_A_FAILED_LO" 13635622 "DTC_HSD_B_FAILED_HI" 13635623 "DTC_HSD_B_FAILED_LO" 13692968 "DTC_CONT_HPWR_FAILED_HI" 13692969 "DTC_CONT_HPWR_FAILED_LO" 13692970 "DTC_CONT_HPWR_OOR_HI" 13692971 "DTC_CONT_HPWR_OOR_LO" 13635616 "DTC_5V_PWR_OOR_HI" 13635617 "DTC_5V_PWR_OOR_LO" 14606336 "DTC_NVM_WRITE_TO" 14606337 "DTC_NVM_READ_TO" 14614528 "DTC_SPI_DIG_POT_FAULT" ;
VAL_ 1120 bcm_dtc_002 0 " - " 11276288 "DTC_VEPO" 11276289 "DTC_HSC_MISSING" 11460608 "DTC_NVM_SOC" 11460609 "DTC_NVM_KOT" 11460610 "DTC_NVM_DTC" 11460611 "DTC_NVM_SOC_CORRECTION" 11460612 "DTC_NVM_APP_SCRATCHPAD" 11517962 "DTC_LOOPTIME_TASK_A" 11517963 "DTC_LOOPTIME_TASK_B" 11517964 "DTC_LOOPTIME_TASK_C" 11517965 "DTC_LOOPTIME_TASK_D" 11517966 "DTC_LOOPTIME_TASK_E" 11517967 "DTC_LOOPTIME_TASK_F" 11323904 "DTC_INTERLOCK_A_FAILED_LOW" 11323905 "DTC_INTERLOCK_A_FAILED_HIGH" 11324160 "DTC_INTERLOCK_B_FAILED_LOW" 11324161 "DTC_INTERLOCK_B_FAILED_HIGH" 15728640 "DTC_EPO" 16498688 "DTC_BRUSA_MISSING" 16498689 "DTC_BRUSA_IDC" 16498690 "DTC_BRUSA_REQ_VS_CMD" 16433152 "DTC_AKERWADE_MISSING" 16433153 "DTC_AKERWADE_IDC" 16433154 "DTC_AKERWADE_REQ_VS_CMD" 16564224 "DTC_CHGLEAR_MISSING" 16564225 "DTC_CHGLEAR_IDC" 16564226 "DTC_CHGLEAR_REQ_VS_CMD" 16522240 "DTC_CSM_MISSING" 16522752 "DTC_CSM_VBAT" 16522753 "DTC_CSM_VPOS" 16522754 "DTC_CSM_VNEG" 16522755 "DTC_CSM_CPOS" 16522756 "DTC_CSM_CNEG" 16522757 "DTC_CSM_APOS" 16522758 "DTC_CSM_ANEG" 16522759 "DTC_CSM_FUSE_HI" 16522760 "DTC_CSM_FUSE_LO" 16521728 "DTC_CSM_ASIC" 16521729 "DTC_CSM_AILO" 16521730 "DTC_CSM_AIHI" 16520957 "DTC_LEAKAGE_DETECT_FAULT" 16522444 "DTC_REALTIMECLOCK_FAULT" 16520945 "DTC_CSM_LEAK_FAIL_CALC" 16520946 "DTC_CSM_LEAK_FAIL_HW" 16520947 "DTC_CSM_LEAK_EXT_SHORT" 16520948 "DTC_CSM_LEAK_MID_PACK_SHORT" 16520949 "DTC_CSM_LEAK_ERROR" 16520950 "DTC_CSM_LEAK_UNKNOWN" 16523008 "DTC_CSM_VER_MISMATCH" 16523009 "DTC_CSM_DTC_SET" 16523010 "DTC_CSM_CAL_FAULT" 16560128 "DTC_IBAT_MISMATCH" 16576512 "DTC_DIS_MAX_I2T" 16576513 "DTC_CHG_MAX_I2T" 16576768 "DTC_DIS_WARNING_I2T" 16576769 "DTC_CHG_WARNING_I2T" 11296784 "DTC_SAEJ1772_PROX_DECT_OOR_HI" 11296785 "DTC_SAEJ1772_PROX_DECT_OOR_LO" 11296800 "DTC_SAEJ1772_PILOT_PWM_OOR_HI" 11296801 "DTC_SAEJ1772_PILOT_PWM_OOR_LO" 11296802 "DTC_SAEJ1772_PILOT_PWM_DIG_COMM" 11296803 "DTC_SAEJ1772_PILOT_PWM_IR_ERR" 16175360 "DTC_FGD1_NO_SENSOR" 16175361 "DTC_FGD1_OOR_HI" 16175362 "DTC_FGD1_OOR_LO" 16175363 "DTC_FGD1_FAULT" 16175616 "DTC_FGD2_NO_SENSOR" 16175617 "DTC_FGD2_OOR_HI" 16175618 "DTC_FGD2_OOR_LO" 16175619 "DTC_FGD2_FAULT" 16171008 "DTC_CONT_OPEN" 16171009 "DTC_CONT_CLOSE" 16171010 "DTC_CONT_OPEN_CURRENT" 16171264 "DTC_CONT_CLOSE_ON_RESET" 16171265 "DTC_CONT_CLOSE_SIG_FAILED" 16171520 "DTC_PRECHARGE_TIMEOUT" 16171777 "DTC_CONT_MPOS_WELD_AT_SU" 16171778 "DTC_CONT_MNEG_WELD_AT_SU" 16171780 "DTC_CONT_CPOS_WELD_AT_SU" 16171781 "DTC_CONT_CNEG_WELD_AT_SU" 16171782 "DTC_CONT_ANEG_WELD_AT_SU" 16171783 "DTC_CONT_APOS_WELD_AT_SU" 16172033 "DTC_CONT_MPOS_WELD_AT_SD" 16172034 "DTC_CONT_MNEG_WELD_AT_SD" 16172036 "DTC_CONT_CPOS_WELD_AT_SD" 16172037 "DTC_CONT_CNEG_WELD_AT_SD" 16172038 "DTC_CONT_ANEG_WELD_AT_SD" 16172039 "DTC_CONT_APOS_WELD_AT_SD" 16172289 "DTC_CONT_MPOS_OPEN" 16172290 "DTC_CONT_MNEG_OPEN" 16172291 "DTC_CONT_MPRE_OPEN" 16172292 "DTC_CONT_CPOS_OPEN" 16172293 "DTC_CONT_CNEG_OPEN" 16172294 "DTC_CONT_APOS_OPEN" 16172295 "DTC_CONT_ANEG_OPEN" 16172545 "DTC_CONT_MPOS_VDIF" 16172546 "DTC_CONT_MNEG_VDIF" 16172548 "DTC_CONT_CPOS_VDIF" 16172549 "DTC_CONT_CNEG_VDIF" 16172550 "DTC_CONT_APOS_VDIF" 16172551 "DTC_CONT_ANEG_VDIF" 16174848 "DTC_HVIL" 16174849 "DTC_LVBAT_LO" 16174850 "DTC_LVBAT_HI" 16174851 "DTC_LVBAT_ERR" 16523520 "DTC_LEMLO_OOR_HI" 16523521 "DTC_LEMLO_OOR_LO" 16523522 "DTC_LEMLO_FAULT" 16523776 "DTC_LEMHI_OOR_HI" 16523777 "DTC_LEMHI_OOR_LO" 16523778 "DTC_LEMHI_FAULT" 16496320 "DTC_MBB_TOO_FEW" 16496321 "DTC_MBB_TOO_MANY" 16496352 "DTC_CELL_VMAX_ERR" 16496353 "DTC_CELL_VMIN_ERR" 16496354 "DTC_CELL_VMAX" 16496362 "DTC_CELL_VMAX_SEVERE" 16496355 "DTC_CELL_VMIN" 16496363 "DTC_CELL_VMIN_SEVERE" 16496356 "DTC_MOD_VOLTAGE_COMPARE" 16496336 "DTC_CELL_T_ERR" 16496337 "DTC_CELL_TMAX1" 16496338 "DTC_CELL_TMAX2" 16496339 "DTC_CELL_TMIN" 16497665 "DTC_MBB_01_MISSING" 16497666 "DTC_MBB_02_MISSING" 16497667 "DTC_MBB_03_MISSING" 16497668 "DTC_MBB_04_MISSING" 16497669 "DTC_MBB_05_MISSING" 16497670 "DTC_MBB_06_MISSING" 16497671 "DTC_MBB_07_MISSING" 16497672 "DTC_MBB_08_MISSING" 16497673 "DTC_MBB_09_MISSING" 16497680 "DTC_MBB_10_MISSING" 16497681 "DTC_MBB_11_MISSING" 16497682 "DTC_MBB_12_MISSING" 16497683 "DTC_MBB_13_MISSING" 16497684 "DTC_MBB_14_MISSING" 16497685 "DTC_MBB_15_MISSING" 16497686 "DTC_MBB_16_MISSING" 16497687 "DTC_MBB_17_MISSING" 16497688 "DTC_MBB_18_MISSING" 16497689 "DTC_MBB_19_MISSING" 16497696 "DTC_MBB_20_MISSING" 16497697 "DTC_MBB_21_MISSING" 16497698 "DTC_MBB_22_MISSING" 16497699 "DTC_MBB_23_MISSING" 16497700 "DTC_MBB_24_MISSING" 16498177 "DTC_MBB_01_VFAULT" 16498178 "DTC_MBB_02_VFAULT" 16498179 "DTC_MBB_03_VFAULT" 16498180 "DTC_MBB_04_VFAULT" 16498181 "DTC_MBB_05_VFAULT" 16498182 "DTC_MBB_06_VFAULT" 16498183 "DTC_MBB_07_VFAULT" 16498184 "DTC_MBB_08_VFAULT" 16498185 "DTC_MBB_09_VFAULT" 16498192 "DTC_MBB_10_VFAULT" 16498193 "DTC_MBB_11_VFAULT" 16498194 "DTC_MBB_12_VFAULT" 16498195 "DTC_MBB_13_VFAULT" 16498196 "DTC_MBB_14_VFAULT" 16498197 "DTC_MBB_15_VFAULT" 16498198 "DTC_MBB_16_VFAULT" 16498199 "DTC_MBB_17_VFAULT" 16498200 "DTC_MBB_18_VFAULT" 16498201 "DTC_MBB_19_VFAULT" 16498208 "DTC_MBB_20_VFAULT" 16498209 "DTC_MBB_21_VFAULT" 16498210 "DTC_MBB_22_VFAULT" 16498211 "DTC_MBB_23_VFAULT" 16498212 "DTC_MBB_24_VFAULT" 16497921 "DTC_MBB_01_TFAULT" 16497922 "DTC_MBB_02_TFAULT" 16497923 "DTC_MBB_03_TFAULT" 16497924 "DTC_MBB_04_TFAULT" 16497925 "DTC_MBB_05_TFAULT" 16497926 "DTC_MBB_06_TFAULT" 16497927 "DTC_MBB_07_TFAULT" 16497928 "DTC_MBB_08_TFAULT" 16497929 "DTC_MBB_09_TFAULT" 16497936 "DTC_MBB_10_TFAULT" 16497937 "DTC_MBB_11_TFAULT" 16497938 "DTC_MBB_12_TFAULT" 16497939 "DTC_MBB_13_TFAULT" 16497940 "DTC_MBB_14_TFAULT" 16497941 "DTC_MBB_15_TFAULT" 16497942 "DTC_MBB_16_TFAULT" 16497943 "DTC_MBB_17_TFAULT" 16497944 "DTC_MBB_18_TFAULT" 16497945 "DTC_MBB_19_TFAULT" 16497952 "DTC_MBB_20_TFAULT" 16497953 "DTC_MBB_21_TFAULT" 16497954 "DTC_MBB_22_TFAULT" 16497955 "DTC_MBB_23_TFAULT" 16497956 "DTC_MBB_24_TFAULT" 15785984 "DTC_PRECHARGE_ENERGY" 15785985 "DTC_PRT_FAILED" 15785986 "DTC_PRT_OVERTEMP" 15785987 "DTC_PRT_PROHIBIT" 16556032 "DTC_COOLANT_TEMP_OOR_HI" 16556033 "DTC_COOLANT_TEMP_OOR_LO" 16252928 "DTC_KEY_OFF_TIME_ERROR" 16506880 "DTC_VBAT_MISMATCH" 16506881 "DTC_VBAT_VMAX" 16506882 "DTC_VBAT_VMIN" 16506883 "DTC_PACK_FUSE" 15798544 "DTC_LLS1_OOR_HI" 15798545 "DTC_LLS1_OOR_LO" 15798546 "DTC_LLS1_FAULT" 15798816 "DTC_LLS2_OOR_HI" 15798817 "DTC_LLS2_OOR_LO" 15798818 "DTC_LLS2_FAULT" 14479360 "DTC_CFL_HEARTBEAT" 14479361 "DTC_CFL_FAULT" 14479362 "DTC_CFL_FAULT_LATCH" 13635584 "DTC_CONT_A_FAILED_HI" 13635585 "DTC_CONT_A_FAILED_LO" 13635586 "DTC_CONT_B_FAILED_HI" 13635587 "DTC_CONT_B_FAILED_LO" 13635588 "DTC_CONT_C_FAILED_HI" 13635589 "DTC_CONT_C_FAILED_LO" 13635590 "DTC_CONT_D_FAILED_HI" 13635591 "DTC_CONT_D_FAILED_LO" 13635592 "DTC_CONT_E_FAILED_HI" 13635593 "DTC_CONT_E_FAILED_LO" 13635594 "DTC_CONT_F_FAILED_HI" 13635595 "DTC_CONT_F_FAILED_LO" 13635596 "DTC_CONT_G_FAILED_HI" 13635597 "DTC_CONT_G_FAILED_LO" 13635598 "DTC_LSD_A_FAILED_HI" 13635599 "DTC_LSD_A_FAILED_LO" 13635600 "DTC_LSD_B_FAILED_HI" 13635601 "DTC_LSD_B_FAILED_LO" 13635602 "DTC_LSD_C_FAILED_HI" 13635603 "DTC_LSD_C_FAILED_LO" 13635606 "DTC_CONT_PWR_FAILED_HI" 13635607 "DTC_CONT_PWR_FAILED_LO" 13635608 "DTC_LSD_PUMP_FAILED_HI" 13635609 "DTC_LSD_PUMP_FAILED_LO" 13635610 "DTC_CHG_A_ENABLE_FAILED_HI" 13635611 "DTC_CHG_A_ENABLE_FAILED_LO" 13635612 "DTC_CHG_B_ENABLE_FAILED_HI" 13635613 "DTC_CHG_B_ENABLE_FAILED_LO" 13635614 "DTC_SW14V_PWR_FAILED_HI" 13635615 "DTC_SW14V_PWR_FAILED_LO" 13635620 "DTC_HSD_A_FAILED_HI" 13635621 "DTC_HSD_A_FAILED_LO" 13635622 "DTC_HSD_B_FAILED_HI" 13635623 "DTC_HSD_B_FAILED_LO" 13692968 "DTC_CONT_HPWR_FAILED_HI" 13692969 "DTC_CONT_HPWR_FAILED_LO" 13692970 "DTC_CONT_HPWR_OOR_HI" 13692971 "DTC_CONT_HPWR_OOR_LO" 13635616 "DTC_5V_PWR_OOR_HI" 13635617 "DTC_5V_PWR_OOR_LO" 14606336 "DTC_NVM_WRITE_TO" 14606337 "DTC_NVM_READ_TO" 14614528 "DTC_SPI_DIG_POT_FAULT" ;
VAL_ 1120 bcm_dtc_003 0 " - " 11276288 "DTC_VEPO" 11276289 "DTC_HSC_MISSING" 11460608 "DTC_NVM_SOC" 11460609 "DTC_NVM_KOT" 11460610 "DTC_NVM_DTC" 11460611 "DTC_NVM_SOC_CORRECTION" 11460612 "DTC_NVM_APP_SCRATCHPAD" 11517962 "DTC_LOOPTIME_TASK_A" 11517963 "DTC_LOOPTIME_TASK_B" 11517964 "DTC_LOOPTIME_TASK_C" 11517965 "DTC_LOOPTIME_TASK_D" 11517966 "DTC_LOOPTIME_TASK_E" 11517967 "DTC_LOOPTIME_TASK_F" 11323904 "DTC_INTERLOCK_A_FAILED_LOW" 11323905 "DTC_INTERLOCK_A_FAILED_HIGH" 11324160 "DTC_INTERLOCK_B_FAILED_LOW" 11324161 "DTC_INTERLOCK_B_FAILED_HIGH" 15728640 "DTC_EPO" 16498688 "DTC_BRUSA_MISSING" 16498689 "DTC_BRUSA_IDC" 16498690 "DTC_BRUSA_REQ_VS_CMD" 16433152 "DTC_AKERWADE_MISSING" 16433153 "DTC_AKERWADE_IDC" 16433154 "DTC_AKERWADE_REQ_VS_CMD" 16564224 "DTC_CHGLEAR_MISSING" 16564225 "DTC_CHGLEAR_IDC" 16564226 "DTC_CHGLEAR_REQ_VS_CMD" 16522240 "DTC_CSM_MISSING" 16522752 "DTC_CSM_VBAT" 16522753 "DTC_CSM_VPOS" 16522754 "DTC_CSM_VNEG" 16522755 "DTC_CSM_CPOS" 16522756 "DTC_CSM_CNEG" 16522757 "DTC_CSM_APOS" 16522758 "DTC_CSM_ANEG" 16522759 "DTC_CSM_FUSE_HI" 16522760 "DTC_CSM_FUSE_LO" 16521728 "DTC_CSM_ASIC" 16521729 "DTC_CSM_AILO" 16521730 "DTC_CSM_AIHI" 16520957 "DTC_LEAKAGE_DETECT_FAULT" 16522444 "DTC_REALTIMECLOCK_FAULT" 16520945 "DTC_CSM_LEAK_FAIL_CALC" 16520946 "DTC_CSM_LEAK_FAIL_HW" 16520947 "DTC_CSM_LEAK_EXT_SHORT" 16520948 "DTC_CSM_LEAK_MID_PACK_SHORT" 16520949 "DTC_CSM_LEAK_ERROR" 16520950 "DTC_CSM_LEAK_UNKNOWN" 16523008 "DTC_CSM_VER_MISMATCH" 16523009 "DTC_CSM_DTC_SET" 16523010 "DTC_CSM_CAL_FAULT" 16560128 "DTC_IBAT_MISMATCH" 16576512 "DTC_DIS_MAX_I2T" 16576513 "DTC_CHG_MAX_I2T" 16576768 "DTC_DIS_WARNING_I2T" 16576769 "DTC_CHG_WARNING_I2T" 11296784 "DTC_SAEJ1772_PROX_DECT_OOR_HI" 11296785 "DTC_SAEJ1772_PROX_DECT_OOR_LO" 11296800 "DTC_SAEJ1772_PILOT_PWM_OOR_HI" 11296801 "DTC_SAEJ1772_PILOT_PWM_OOR_LO" 11296802 "DTC_SAEJ1772_PILOT_PWM_DIG_COMM" 11296803 "DTC_SAEJ1772_PILOT_PWM_IR_ERR" 16175360 "DTC_FGD1_NO_SENSOR" 16175361 "DTC_FGD1_OOR_HI" 16175362 "DTC_FGD1_OOR_LO" 16175363 "DTC_FGD1_FAULT" 16175616 "DTC_FGD2_NO_SENSOR" 16175617 "DTC_FGD2_OOR_HI" 16175618 "DTC_FGD2_OOR_LO" 16175619 "DTC_FGD2_FAULT" 16171008 "DTC_CONT_OPEN" 16171009 "DTC_CONT_CLOSE" 16171010 "DTC_CONT_OPEN_CURRENT" 16171264 "DTC_CONT_CLOSE_ON_RESET" 16171265 "DTC_CONT_CLOSE_SIG_FAILED" 16171520 "DTC_PRECHARGE_TIMEOUT" 16171777 "DTC_CONT_MPOS_WELD_AT_SU" 16171778 "DTC_CONT_MNEG_WELD_AT_SU" 16171780 "DTC_CONT_CPOS_WELD_AT_SU" 16171781 "DTC_CONT_CNEG_WELD_AT_SU" 16171782 "DTC_CONT_ANEG_WELD_AT_SU" 16171783 "DTC_CONT_APOS_WELD_AT_SU" 16172033 "DTC_CONT_MPOS_WELD_AT_SD" 16172034 "DTC_CONT_MNEG_WELD_AT_SD" 16172036 "DTC_CONT_CPOS_WELD_AT_SD" 16172037 "DTC_CONT_CNEG_WELD_AT_SD" 16172038 "DTC_CONT_ANEG_WELD_AT_SD" 16172039 "DTC_CONT_APOS_WELD_AT_SD" 16172289 "DTC_CONT_MPOS_OPEN" 16172290 "DTC_CONT_MNEG_OPEN" 16172291 "DTC_CONT_MPRE_OPEN" 16172292 "DTC_CONT_CPOS_OPEN" 16172293 "DTC_CONT_CNEG_OPEN" 16172294 "DTC_CONT_APOS_OPEN" 16172295 "DTC_CONT_ANEG_OPEN" 16172545 "DTC_CONT_MPOS_VDIF" 16172546 "DTC_CONT_MNEG_VDIF" 16172548 "DTC_CONT_CPOS_VDIF" 16172549 "DTC_CONT_CNEG_VDIF" 16172550 "DTC_CONT_APOS_VDIF" 16172551 "DTC_CONT_ANEG_VDIF" 16174848 "DTC_HVIL" 16174849 "DTC_LVBAT_LO" 16174850 "DTC_LVBAT_HI" 16174851 "DTC_LVBAT_ERR" 16523520 "DTC_LEMLO_OOR_HI" 16523521 "DTC_LEMLO_OOR_LO" 16523522 "DTC_LEMLO_FAULT" 16523776 "DTC_LEMHI_OOR_HI" 16523777 "DTC_LEMHI_OOR_LO" 16523778 "DTC_LEMHI_FAULT" 16496320 "DTC_MBB_TOO_FEW" 16496321 "DTC_MBB_TOO_MANY" 16496352 "DTC_CELL_VMAX_ERR" 16496353 "DTC_CELL_VMIN_ERR" 16496354 "DTC_CELL_VMAX" 16496362 "DTC_CELL_VMAX_SEVERE" 16496355 "DTC_CELL_VMIN" 16496363 "DTC_CELL_VMIN_SEVERE" 16496356 "DTC_MOD_VOLTAGE_COMPARE" 16496336 "DTC_CELL_T_ERR" 16496337 "DTC_CELL_TMAX1" 16496338 "DTC_CELL_TMAX2" 16496339 "DTC_CELL_TMIN" 16497665 "DTC_MBB_01_MISSING" 16497666 "DTC_MBB_02_MISSING" 16497667 "DTC_MBB_03_MISSING" 16497668 "DTC_MBB_04_MISSING" 16497669 "DTC_MBB_05_MISSING" 16497670 "DTC_MBB_06_MISSING" 16497671 "DTC_MBB_07_MISSING" 16497672 "DTC_MBB_08_MISSING" 16497673 "DTC_MBB_09_MISSING" 16497680 "DTC_MBB_10_MISSING" 16497681 "DTC_MBB_11_MISSING" 16497682 "DTC_MBB_12_MISSING" 16497683 "DTC_MBB_13_MISSING" 16497684 "DTC_MBB_14_MISSING" 16497685 "DTC_MBB_15_MISSING" 16497686 "DTC_MBB_16_MISSING" 16497687 "DTC_MBB_17_MISSING" 16497688 "DTC_MBB_18_MISSING" 16497689 "DTC_MBB_19_MISSING" 16497696 "DTC_MBB_20_MISSING" 16497697 "DTC_MBB_21_MISSING" 16497698 "DTC_MBB_22_MISSING" 16497699 "DTC_MBB_23_MISSING" 16497700 "DTC_MBB_24_MISSING" 16498177 "DTC_MBB_01_VFAULT" 16498178 "DTC_MBB_02_VFAULT" 16498179 "DTC_MBB_03_VFAULT" 16498180 "DTC_MBB_04_VFAULT" 16498181 "DTC_MBB_05_VFAULT" 16498182 "DTC_MBB_06_VFAULT" 16498183 "DTC_MBB_07_VFAULT" 16498184 "DTC_MBB_08_VFAULT" 16498185 "DTC_MBB_09_VFAULT" 16498192 "DTC_MBB_10_VFAULT" 16498193 "DTC_MBB_11_VFAULT" 16498194 "DTC_MBB_12_VFAULT" 16498195 "DTC_MBB_13_VFAULT" 16498196 "DTC_MBB_14_VFAULT" 16498197 "DTC_MBB_15_VFAULT" 16498198 "DTC_MBB_16_VFAULT" 16498199 "DTC_MBB_17_VFAULT" 16498200 "DTC_MBB_18_VFAULT" 16498201 "DTC_MBB_19_VFAULT" 16498208 "DTC_MBB_20_VFAULT" 16498209 "DTC_MBB_21_VFAULT" 16498210 "DTC_MBB_22_VFAULT" 16498211 "DTC_MBB_23_VFAULT" 16498212 "DTC_MBB_24_VFAULT" 16497921 "DTC_MBB_01_TFAULT" 16497922 "DTC_MBB_02_TFAULT" 16497923 "DTC_MBB_03_TFAULT" 16497924 "DTC_MBB_04_TFAULT" 16497925 "DTC_MBB_05_TFAULT" 16497926 "DTC_MBB_06_TFAULT" 16497927 "DTC_MBB_07_TFAULT" 16497928 "DTC_MBB_08_TFAULT" 16497929 "DTC_MBB_09_TFAULT" 16497936 "DTC_MBB_10_TFAULT" 16497937 "DTC_MBB_11_TFAULT" 16497938 "DTC_MBB_12_TFAULT" 16497939 "DTC_MBB_13_TFAULT" 16497940 "DTC_MBB_14_TFAULT" 16497941 "DTC_MBB_15_TFAULT" 16497942 "DTC_MBB_16_TFAULT" 16497943 "DTC_MBB_17_TFAULT" 16497944 "DTC_MBB_18_TFAULT" 16497945 "DTC_MBB_19_TFAULT" 16497952 "DTC_MBB_20_TFAULT" 16497953 "DTC_MBB_21_TFAULT" 16497954 "DTC_MBB_22_TFAULT" 16497955 "DTC_MBB_23_TFAULT" 16497956 "DTC_MBB_24_TFAULT" 15785984 "DTC_PRECHARGE_ENERGY" 15785985 "DTC_PRT_FAILED" 15785986 "DTC_PRT_OVERTEMP" 15785987 "DTC_PRT_PROHIBIT" 16556032 "DTC_COOLANT_TEMP_OOR_HI" 16556033 "DTC_COOLANT_TEMP_OOR_LO" 16252928 "DTC_KEY_OFF_TIME_ERROR" 16506880 "DTC_VBAT_MISMATCH" 16506881 "DTC_VBAT_VMAX" 16506882 "DTC_VBAT_VMIN" 16506883 "DTC_PACK_FUSE" 15798544 "DTC_LLS1_OOR_HI" 15798545 "DTC_LLS1_OOR_LO" 15798546 "DTC_LLS1_FAULT" 15798816 "DTC_LLS2_OOR_HI" 15798817 "DTC_LLS2_OOR_LO" 15798818 "DTC_LLS2_FAULT" 14479360 "DTC_CFL_HEARTBEAT" 14479361 "DTC_CFL_FAULT" 14479362 "DTC_CFL_FAULT_LATCH" 13635584 "DTC_CONT_A_FAILED_HI" 13635585 "DTC_CONT_A_FAILED_LO" 13635586 "DTC_CONT_B_FAILED_HI" 13635587 "DTC_CONT_B_FAILED_LO" 13635588 "DTC_CONT_C_FAILED_HI" 13635589 "DTC_CONT_C_FAILED_LO" 13635590 "DTC_CONT_D_FAILED_HI" 13635591 "DTC_CONT_D_FAILED_LO" 13635592 "DTC_CONT_E_FAILED_HI" 13635593 "DTC_CONT_E_FAILED_LO" 13635594 "DTC_CONT_F_FAILED_HI" 13635595 "DTC_CONT_F_FAILED_LO" 13635596 "DTC_CONT_G_FAILED_HI" 13635597 "DTC_CONT_G_FAILED_LO" 13635598 "DTC_LSD_A_FAILED_HI" 13635599 "DTC_LSD_A_FAILED_LO" 13635600 "DTC_LSD_B_FAILED_HI" 13635601 "DTC_LSD_B_FAILED_LO" 13635602 "DTC_LSD_C_FAILED_HI" 13635603 "DTC_LSD_C_FAILED_LO" 13635606 "DTC_CONT_PWR_FAILED_HI" 13635607 "DTC_CONT_PWR_FAILED_LO" 13635608 "DTC_LSD_PUMP_FAILED_HI" 13635609 "DTC_LSD_PUMP_FAILED_LO" 13635610 "DTC_CHG_A_ENABLE_FAILED_HI" 13635611 "DTC_CHG_A_ENABLE_FAILED_LO" 13635612 "DTC_CHG_B_ENABLE_FAILED_HI" 13635613 "DTC_CHG_B_ENABLE_FAILED_LO" 13635614 "DTC_SW14V_PWR_FAILED_HI" 13635615 "DTC_SW14V_PWR_FAILED_LO" 13635620 "DTC_HSD_A_FAILED_HI" 13635621 "DTC_HSD_A_FAILED_LO" 13635622 "DTC_HSD_B_FAILED_HI" 13635623 "DTC_HSD_B_FAILED_LO" 13692968 "DTC_CONT_HPWR_FAILED_HI" 13692969 "DTC_CONT_HPWR_FAILED_LO" 13692970 "DTC_CONT_HPWR_OOR_HI" 13692971 "DTC_CONT_HPWR_OOR_LO" 13635616 "DTC_5V_PWR_OOR_HI" 13635617 "DTC_5V_PWR_OOR_LO" 14606336 "DTC_NVM_WRITE_TO" 14606337 "DTC_NVM_READ_TO" 14614528 "DTC_SPI_DIG_POT_FAULT" ;
VAL_ 1120 bcm_dtc_004 0 " - " 11276288 "DTC_VEPO" 11276289 "DTC_HSC_MISSING" 11460608 "DTC_NVM_SOC" 11460609 "DTC_NVM_KOT" 11460610 "DTC_NVM_DTC" 11460611 "DTC_NVM_SOC_CORRECTION" 11460612 "DTC_NVM_APP_SCRATCHPAD" 11517962 "DTC_LOOPTIME_TASK_A" 11517963 "DTC_LOOPTIME_TASK_B" 11517964 "DTC_LOOPTIME_TASK_C" 11517965 "DTC_LOOPTIME_TASK_D" 11517966 "DTC_LOOPTIME_TASK_E" 11517967 "DTC_LOOPTIME_TASK_F" 11323904 "DTC_INTERLOCK_A_FAILED_LOW" 11323905 "DTC_INTERLOCK_A_FAILED_HIGH" 11324160 "DTC_INTERLOCK_B_FAILED_LOW" 11324161 "DTC_INTERLOCK_B_FAILED_HIGH" 15728640 "DTC_EPO" 16498688 "DTC_BRUSA_MISSING" 16498689 "DTC_BRUSA_IDC" 16498690 "DTC_BRUSA_REQ_VS_CMD" 16433152 "DTC_AKERWADE_MISSING" 16433153 "DTC_AKERWADE_IDC" 16433154 "DTC_AKERWADE_REQ_VS_CMD" 16564224 "DTC_CHGLEAR_MISSING" 16564225 "DTC_CHGLEAR_IDC" 16564226 "DTC_CHGLEAR_REQ_VS_CMD" 16522240 "DTC_CSM_MISSING" 16522752 "DTC_CSM_VBAT" 16522753 "DTC_CSM_VPOS" 16522754 "DTC_CSM_VNEG" 16522755 "DTC_CSM_CPOS" 16522756 "DTC_CSM_CNEG" 16522757 "DTC_CSM_APOS" 16522758 "DTC_CSM_ANEG" 16522759 "DTC_CSM_FUSE_HI" 16522760 "DTC_CSM_FUSE_LO" 16521728 "DTC_CSM_ASIC" 16521729 "DTC_CSM_AILO" 16521730 "DTC_CSM_AIHI" 16520957 "DTC_LEAKAGE_DETECT_FAULT" 16522444 "DTC_REALTIMECLOCK_FAULT" 16520945 "DTC_CSM_LEAK_FAIL_CALC" 16520946 "DTC_CSM_LEAK_FAIL_HW" 16520947 "DTC_CSM_LEAK_EXT_SHORT" 16520948 "DTC_CSM_LEAK_MID_PACK_SHORT" 16520949 "DTC_CSM_LEAK_ERROR" 16520950 "DTC_CSM_LEAK_UNKNOWN" 16523008 "DTC_CSM_VER_MISMATCH" 16523009 "DTC_CSM_DTC_SET" 16523010 "DTC_CSM_CAL_FAULT" 16560128 "DTC_IBAT_MISMATCH" 16576512 "DTC_DIS_MAX_I2T" 16576513 "DTC_CHG_MAX_I2T" 16576768 "DTC_DIS_WARNING_I2T" 16576769 "DTC_CHG_WARNING_I2T" 11296784 "DTC_SAEJ1772_PROX_DECT_OOR_HI" 11296785 "DTC_SAEJ1772_PROX_DECT_OOR_LO" 11296800 "DTC_SAEJ1772_PILOT_PWM_OOR_HI" 11296801 "DTC_SAEJ1772_PILOT_PWM_OOR_LO" 11296802 "DTC_SAEJ1772_PILOT_PWM_DIG_COMM" 11296803 "DTC_SAEJ1772_PILOT_PWM_IR_ERR" 16175360 "DTC_FGD1_NO_SENSOR" 16175361 "DTC_FGD1_OOR_HI" 16175362 "DTC_FGD1_OOR_LO" 16175363 "DTC_FGD1_FAULT" 16175616 "DTC_FGD2_NO_SENSOR" 16175617 "DTC_FGD2_OOR_HI" 16175618 "DTC_FGD2_OOR_LO" 16175619 "DTC_FGD2_FAULT" 16171008 "DTC_CONT_OPEN" 16171009 "DTC_CONT_CLOSE" 16171010 "DTC_CONT_OPEN_CURRENT" 16171264 "DTC_CONT_CLOSE_ON_RESET" 16171265 "DTC_CONT_CLOSE_SIG_FAILED" 16171520 "DTC_PRECHARGE_TIMEOUT" 16171777 "DTC_CONT_MPOS_WELD_AT_SU" 16171778 "DTC_CONT_MNEG_WELD_AT_SU" 16171780 "DTC_CONT_CPOS_WELD_AT_SU" 16171781 "DTC_CONT_CNEG_WELD_AT_SU" 16171782 "DTC_CONT_ANEG_WELD_AT_SU" 16171783 "DTC_CONT_APOS_WELD_AT_SU" 16172033 "DTC_CONT_MPOS_WELD_AT_SD" 16172034 "DTC_CONT_MNEG_WELD_AT_SD" 16172036 "DTC_CONT_CPOS_WELD_AT_SD" 16172037 "DTC_CONT_CNEG_WELD_AT_SD" 16172038 "DTC_CONT_ANEG_WELD_AT_SD" 16172039 "DTC_CONT_APOS_WELD_AT_SD" 16172289 "DTC_CONT_MPOS_OPEN" 16172290 "DTC_CONT_MNEG_OPEN" 16172291 "DTC_CONT_MPRE_OPEN" 16172292 "DTC_CONT_CPOS_OPEN" 16172293 "DTC_CONT_CNEG_OPEN" 16172294 "DTC_CONT_APOS_OPEN" 16172295 "DTC_CONT_ANEG_OPEN" 16172545 "DTC_CONT_MPOS_VDIF" 16172546 "DTC_CONT_MNEG_VDIF" 16172548 "DTC_CONT_CPOS_VDIF" 16172549 "DTC_CONT_CNEG_VDIF" 16172550 "DTC_CONT_APOS_VDIF" 16172551 "DTC_CONT_ANEG_VDIF" 16174848 "DTC_HVIL" 16174849 "DTC_LVBAT_LO" 16174850 "DTC_LVBAT_HI" 16174851 "DTC_LVBAT_ERR" 16523520 "DTC_LEMLO_OOR_HI" 16523521 "DTC_LEMLO_OOR_LO" 16523522 "DTC_LEMLO_FAULT" 16523776 "DTC_LEMHI_OOR_HI" 16523777 "DTC_LEMHI_OOR_LO" 16523778 "DTC_LEMHI_FAULT" 16496320 "DTC_MBB_TOO_FEW" 16496321 "DTC_MBB_TOO_MANY" 16496352 "DTC_CELL_VMAX_ERR" 16496353 "DTC_CELL_VMIN_ERR" 16496354 "DTC_CELL_VMAX" 16496362 "DTC_CELL_VMAX_SEVERE" 16496355 "DTC_CELL_VMIN" 16496363 "DTC_CELL_VMIN_SEVERE" 16496356 "DTC_MOD_VOLTAGE_COMPARE" 16496336 "DTC_CELL_T_ERR" 16496337 "DTC_CELL_TMAX1" 16496338 "DTC_CELL_TMAX2" 16496339 "DTC_CELL_TMIN" 16497665 "DTC_MBB_01_MISSING" 16497666 "DTC_MBB_02_MISSING" 16497667 "DTC_MBB_03_MISSING" 16497668 "DTC_MBB_04_MISSING" 16497669 "DTC_MBB_05_MISSING" 16497670 "DTC_MBB_06_MISSING" 16497671 "DTC_MBB_07_MISSING" 16497672 "DTC_MBB_08_MISSING" 16497673 "DTC_MBB_09_MISSING" 16497680 "DTC_MBB_10_MISSING" 16497681 "DTC_MBB_11_MISSING" 16497682 "DTC_MBB_12_MISSING" 16497683 "DTC_MBB_13_MISSING" 16497684 "DTC_MBB_14_MISSING" 16497685 "DTC_MBB_15_MISSING" 16497686 "DTC_MBB_16_MISSING" 16497687 "DTC_MBB_17_MISSING" 16497688 "DTC_MBB_18_MISSING" 16497689 "DTC_MBB_19_MISSING" 16497696 "DTC_MBB_20_MISSING" 16497697 "DTC_MBB_21_MISSING" 16497698 "DTC_MBB_22_MISSING" 16497699 "DTC_MBB_23_MISSING" 16497700 "DTC_MBB_24_MISSING" 16498177 "DTC_MBB_01_VFAULT" 16498178 "DTC_MBB_02_VFAULT" 16498179 "DTC_MBB_03_VFAULT" 16498180 "DTC_MBB_04_VFAULT" 16498181 "DTC_MBB_05_VFAULT" 16498182 "DTC_MBB_06_VFAULT" 16498183 "DTC_MBB_07_VFAULT" 16498184 "DTC_MBB_08_VFAULT" 16498185 "DTC_MBB_09_VFAULT" 16498192 "DTC_MBB_10_VFAULT" 16498193 "DTC_MBB_11_VFAULT" 16498194 "DTC_MBB_12_VFAULT" 16498195 "DTC_MBB_13_VFAULT" 16498196 "DTC_MBB_14_VFAULT" 16498197 "DTC_MBB_15_VFAULT" 16498198 "DTC_MBB_16_VFAULT" 16498199 "DTC_MBB_17_VFAULT" 16498200 "DTC_MBB_18_VFAULT" 16498201 "DTC_MBB_19_VFAULT" 16498208 "DTC_MBB_20_VFAULT" 16498209 "DTC_MBB_21_VFAULT" 16498210 "DTC_MBB_22_VFAULT" 16498211 "DTC_MBB_23_VFAULT" 16498212 "DTC_MBB_24_VFAULT" 16497921 "DTC_MBB_01_TFAULT" 16497922 "DTC_MBB_02_TFAULT" 16497923 "DTC_MBB_03_TFAULT" 16497924 "DTC_MBB_04_TFAULT" 16497925 "DTC_MBB_05_TFAULT" 16497926 "DTC_MBB_06_TFAULT" 16497927 "DTC_MBB_07_TFAULT" 16497928 "DTC_MBB_08_TFAULT" 16497929 "DTC_MBB_09_TFAULT" 16497936 "DTC_MBB_10_TFAULT" 16497937 "DTC_MBB_11_TFAULT" 16497938 "DTC_MBB_12_TFAULT" 16497939 "DTC_MBB_13_TFAULT" 16497940 "DTC_MBB_14_TFAULT" 16497941 "DTC_MBB_15_TFAULT" 16497942 "DTC_MBB_16_TFAULT" 16497943 "DTC_MBB_17_TFAULT" 16497944 "DTC_MBB_18_TFAULT" 16497945 "DTC_MBB_19_TFAULT" 16497952 "DTC_MBB_20_TFAULT" 16497953 "DTC_MBB_21_TFAULT" 16497954 "DTC_MBB_22_TFAULT" 16497955 "DTC_MBB_23_TFAULT" 16497956 "DTC_MBB_24_TFAULT" 15785984 "DTC_PRECHARGE_ENERGY" 15785985 "DTC_PRT_FAILED" 15785986 "DTC_PRT_OVERTEMP" 15785987 "DTC_PRT_PROHIBIT" 16556032 "DTC_COOLANT_TEMP_OOR_HI" 16556033 "DTC_COOLANT_TEMP_OOR_LO" 16252928 "DTC_KEY_OFF_TIME_ERROR" 16506880 "DTC_VBAT_MISMATCH" 16506881 "DTC_VBAT_VMAX" 16506882 "DTC_VBAT_VMIN" 16506883 "DTC_PACK_FUSE" 15798544 "DTC_LLS1_OOR_HI" 15798545 "DTC_LLS1_OOR_LO" 15798546 "DTC_LLS1_FAULT" 15798816 "DTC_LLS2_OOR_HI" 15798817 "DTC_LLS2_OOR_LO" 15798818 "DTC_LLS2_FAULT" 14479360 "DTC_CFL_HEARTBEAT" 14479361 "DTC_CFL_FAULT" 14479362 "DTC_CFL_FAULT_LATCH" 13635584 "DTC_CONT_A_FAILED_HI" 13635585 "DTC_CONT_A_FAILED_LO" 13635586 "DTC_CONT_B_FAILED_HI" 13635587 "DTC_CONT_B_FAILED_LO" 13635588 "DTC_CONT_C_FAILED_HI" 13635589 "DTC_CONT_C_FAILED_LO" 13635590 "DTC_CONT_D_FAILED_HI" 13635591 "DTC_CONT_D_FAILED_LO" 13635592 "DTC_CONT_E_FAILED_HI" 13635593 "DTC_CONT_E_FAILED_LO" 13635594 "DTC_CONT_F_FAILED_HI" 13635595 "DTC_CONT_F_FAILED_LO" 13635596 "DTC_CONT_G_FAILED_HI" 13635597 "DTC_CONT_G_FAILED_LO" 13635598 "DTC_LSD_A_FAILED_HI" 13635599 "DTC_LSD_A_FAILED_LO" 13635600 "DTC_LSD_B_FAILED_HI" 13635601 "DTC_LSD_B_FAILED_LO" 13635602 "DTC_LSD_C_FAILED_HI" 13635603 "DTC_LSD_C_FAILED_LO" 13635606 "DTC_CONT_PWR_FAILED_HI" 13635607 "DTC_CONT_PWR_FAILED_LO" 13635608 "DTC_LSD_PUMP_FAILED_HI" 13635609 "DTC_LSD_PUMP_FAILED_LO" 13635610 "DTC_CHG_A_ENABLE_FAILED_HI" 13635611 "DTC_CHG_A_ENABLE_FAILED_LO" 13635612 "DTC_CHG_B_ENABLE_FAILED_HI" 13635613 "DTC_CHG_B_ENABLE_FAILED_LO" 13635614 "DTC_SW14V_PWR_FAILED_HI" 13635615 "DTC_SW14V_PWR_FAILED_LO" 13635620 "DTC_HSD_A_FAILED_HI" 13635621 "DTC_HSD_A_FAILED_LO" 13635622 "DTC_HSD_B_FAILED_HI" 13635623 "DTC_HSD_B_FAILED_LO" 13692968 "DTC_CONT_HPWR_FAILED_HI" 13692969 "DTC_CONT_HPWR_FAILED_LO" 13692970 "DTC_CONT_HPWR_OOR_HI" 13692971 "DTC_CONT_HPWR_OOR_LO" 13635616 "DTC_5V_PWR_OOR_HI" 13635617 "DTC_5V_PWR_OOR_LO" 14606336 "DTC_NVM_WRITE_TO" 14606337 "DTC_NVM_READ_TO" 14614528 "DTC_SPI_DIG_POT_FAULT" ;
VAL_ 1120 bcm_dtc_005 0 " - " 11276288 "DTC_VEPO" 11276289 "DTC_HSC_MISSING" 11460608 "DTC_NVM_SOC" 11460609 "DTC_NVM_KOT" 11460610 "DTC_NVM_DTC" 11460611 "DTC_NVM_SOC_CORRECTION" 11460612 "DTC_NVM_APP_SCRATCHPAD" 11517962 "DTC_LOOPTIME_TASK_A" 11517963 "DTC_LOOPTIME_TASK_B" 11517964 "DTC_LOOPTIME_TASK_C" 11517965 "DTC_LOOPTIME_TASK_D" 11517966 "DTC_LOOPTIME_TASK_E" 11517967 "DTC_LOOPTIME_TASK_F" 11323904 "DTC_INTERLOCK_A_FAILED_LOW" 11323905 "DTC_INTERLOCK_A_FAILED_HIGH" 11324160 "DTC_INTERLOCK_B_FAILED_LOW" 11324161 "DTC_INTERLOCK_B_FAILED_HIGH" 15728640 "DTC_EPO" 16498688 "DTC_BRUSA_MISSING" 16498689 "DTC_BRUSA_IDC" 16498690 "DTC_BRUSA_REQ_VS_CMD" 16433152 "DTC_AKERWADE_MISSING" 16433153 "DTC_AKERWADE_IDC" 16433154 "DTC_AKERWADE_REQ_VS_CMD" 16564224 "DTC_CHGLEAR_MISSING" 16564225 "DTC_CHGLEAR_IDC" 16564226 "DTC_CHGLEAR_REQ_VS_CMD" 16522240 "DTC_CSM_MISSING" 16522752 "DTC_CSM_VBAT" 16522753 "DTC_CSM_VPOS" 16522754 "DTC_CSM_VNEG" 16522755 "DTC_CSM_CPOS" 16522756 "DTC_CSM_CNEG" 16522757 "DTC_CSM_APOS" 16522758 "DTC_CSM_ANEG" 16522759 "DTC_CSM_FUSE_HI" 16522760 "DTC_CSM_FUSE_LO" 16521728 "DTC_CSM_ASIC" 16521729 "DTC_CSM_AILO" 16521730 "DTC_CSM_AIHI" 16520957 "DTC_LEAKAGE_DETECT_FAULT" 16522444 "DTC_REALTIMECLOCK_FAULT" 16520945 "DTC_CSM_LEAK_FAIL_CALC" 16520946 "DTC_CSM_LEAK_FAIL_HW" 16520947 "DTC_CSM_LEAK_EXT_SHORT" 16520948 "DTC_CSM_LEAK_MID_PACK_SHORT" 16520949 "DTC_CSM_LEAK_ERROR" 16520950 "DTC_CSM_LEAK_UNKNOWN" 16523008 "DTC_CSM_VER_MISMATCH" 16523009 "DTC_CSM_DTC_SET" 16523010 "DTC_CSM_CAL_FAULT" 16560128 "DTC_IBAT_MISMATCH" 16576512 "DTC_DIS_MAX_I2T" 16576513 "DTC_CHG_MAX_I2T" 16576768 "DTC_DIS_WARNING_I2T" 16576769 "DTC_CHG_WARNING_I2T" 11296784 "DTC_SAEJ1772_PROX_DECT_OOR_HI" 11296785 "DTC_SAEJ1772_PROX_DECT_OOR_LO" 11296800 "DTC_SAEJ1772_PILOT_PWM_OOR_HI" 11296801 "DTC_SAEJ1772_PILOT_PWM_OOR_LO" 11296802 "DTC_SAEJ1772_PILOT_PWM_DIG_COMM" 11296803 "DTC_SAEJ1772_PILOT_PWM_IR_ERR" 16175360 "DTC_FGD1_NO_SENSOR" 16175361 "DTC_FGD1_OOR_HI" 16175362 "DTC_FGD1_OOR_LO" 16175363 "DTC_FGD1_FAULT" 16175616 "DTC_FGD2_NO_SENSOR" 16175617 "DTC_FGD2_OOR_HI" 16175618 "DTC_FGD2_OOR_LO" 16175619 "DTC_FGD2_FAULT" 16171008 "DTC_CONT_OPEN" 16171009 "DTC_CONT_CLOSE" 16171010 "DTC_CONT_OPEN_CURRENT" 16171264 "DTC_CONT_CLOSE_ON_RESET" 16171265 "DTC_CONT_CLOSE_SIG_FAILED" 16171520 "DTC_PRECHARGE_TIMEOUT" 16171777 "DTC_CONT_MPOS_WELD_AT_SU" 16171778 "DTC_CONT_MNEG_WELD_AT_SU" 16171780 "DTC_CONT_CPOS_WELD_AT_SU" 16171781 "DTC_CONT_CNEG_WELD_AT_SU" 16171782 "DTC_CONT_ANEG_WELD_AT_SU" 16171783 "DTC_CONT_APOS_WELD_AT_SU" 16172033 "DTC_CONT_MPOS_WELD_AT_SD" 16172034 "DTC_CONT_MNEG_WELD_AT_SD" 16172036 "DTC_CONT_CPOS_WELD_AT_SD" 16172037 "DTC_CONT_CNEG_WELD_AT_SD" 16172038 "DTC_CONT_ANEG_WELD_AT_SD" 16172039 "DTC_CONT_APOS_WELD_AT_SD" 16172289 "DTC_CONT_MPOS_OPEN" 16172290 "DTC_CONT_MNEG_OPEN" 16172291 "DTC_CONT_MPRE_OPEN" 16172292 "DTC_CONT_CPOS_OPEN" 16172293 "DTC_CONT_CNEG_OPEN" 16172294 "DTC_CONT_APOS_OPEN" 16172295 "DTC_CONT_ANEG_OPEN" 16172545 "DTC_CONT_MPOS_VDIF" 16172546 "DTC_CONT_MNEG_VDIF" 16172548 "DTC_CONT_CPOS_VDIF" 16172549 "DTC_CONT_CNEG_VDIF" 16172550 "DTC_CONT_APOS_VDIF" 16172551 "DTC_CONT_ANEG_VDIF" 16174848 "DTC_HVIL" 16174849 "DTC_LVBAT_LO" 16174850 "DTC_LVBAT_HI" 16174851 "DTC_LVBAT_ERR" 16523520 "DTC_LEMLO_OOR_HI" 16523521 "DTC_LEMLO_OOR_LO" 16523522 "DTC_LEMLO_FAULT" 16523776 "DTC_LEMHI_OOR_HI" 16523777 "DTC_LEMHI_OOR_LO" 16523778 "DTC_LEMHI_FAULT" 16496320 "DTC_MBB_TOO_FEW" 16496321 "DTC_MBB_TOO_MANY" 16496352 "DTC_CELL_VMAX_ERR" 16496353 "DTC_CELL_VMIN_ERR" 16496354 "DTC_CELL_VMAX" 16496362 "DTC_CELL_VMAX_SEVERE" 16496355 "DTC_CELL_VMIN" 16496363 "DTC_CELL_VMIN_SEVERE" 16496356 "DTC_MOD_VOLTAGE_COMPARE" 16496336 "DTC_CELL_T_ERR" 16496337 "DTC_CELL_TMAX1" 16496338 "DTC_CELL_TMAX2" 16496339 "DTC_CELL_TMIN" 16497665 "DTC_MBB_01_MISSING" 16497666 "DTC_MBB_02_MISSING" 16497667 "DTC_MBB_03_MISSING" 16497668 "DTC_MBB_04_MISSING" 16497669 "DTC_MBB_05_MISSING" 16497670 "DTC_MBB_06_MISSING" 16497671 "DTC_MBB_07_MISSING" 16497672 "DTC_MBB_08_MISSING" 16497673 "DTC_MBB_09_MISSING" 16497680 "DTC_MBB_10_MISSING" 16497681 "DTC_MBB_11_MISSING" 16497682 "DTC_MBB_12_MISSING" 16497683 "DTC_MBB_13_MISSING" 16497684 "DTC_MBB_14_MISSING" 16497685 "DTC_MBB_15_MISSING" 16497686 "DTC_MBB_16_MISSING" 16497687 "DTC_MBB_17_MISSING" 16497688 "DTC_MBB_18_MISSING" 16497689 "DTC_MBB_19_MISSING" 16497696 "DTC_MBB_20_MISSING" 16497697 "DTC_MBB_21_MISSING" 16497698 "DTC_MBB_22_MISSING" 16497699 "DTC_MBB_23_MISSING" 16497700 "DTC_MBB_24_MISSING" 16498177 "DTC_MBB_01_VFAULT" 16498178 "DTC_MBB_02_VFAULT" 16498179 "DTC_MBB_03_VFAULT" 16498180 "DTC_MBB_04_VFAULT" 16498181 "DTC_MBB_05_VFAULT" 16498182 "DTC_MBB_06_VFAULT" 16498183 "DTC_MBB_07_VFAULT" 16498184 "DTC_MBB_08_VFAULT" 16498185 "DTC_MBB_09_VFAULT" 16498192 "DTC_MBB_10_VFAULT" 16498193 "DTC_MBB_11_VFAULT" 16498194 "DTC_MBB_12_VFAULT" 16498195 "DTC_MBB_13_VFAULT" 16498196 "DTC_MBB_14_VFAULT" 16498197 "DTC_MBB_15_VFAULT" 16498198 "DTC_MBB_16_VFAULT" 16498199 "DTC_MBB_17_VFAULT" 16498200 "DTC_MBB_18_VFAULT" 16498201 "DTC_MBB_19_VFAULT" 16498208 "DTC_MBB_20_VFAULT" 16498209 "DTC_MBB_21_VFAULT" 16498210 "DTC_MBB_22_VFAULT" 16498211 "DTC_MBB_23_VFAULT" 16498212 "DTC_MBB_24_VFAULT" 16497921 "DTC_MBB_01_TFAULT" 16497922 "DTC_MBB_02_TFAULT" 16497923 "DTC_MBB_03_TFAULT" 16497924 "DTC_MBB_04_TFAULT" 16497925 "DTC_MBB_05_TFAULT" 16497926 "DTC_MBB_06_TFAULT" 16497927 "DTC_MBB_07_TFAULT" 16497928 "DTC_MBB_08_TFAULT" 16497929 "DTC_MBB_09_TFAULT" 16497936 "DTC_MBB_10_TFAULT" 16497937 "DTC_MBB_11_TFAULT" 16497938 "DTC_MBB_12_TFAULT" 16497939 "DTC_MBB_13_TFAULT" 16497940 "DTC_MBB_14_TFAULT" 16497941 "DTC_MBB_15_TFAULT" 16497942 "DTC_MBB_16_TFAULT" 16497943 "DTC_MBB_17_TFAULT" 16497944 "DTC_MBB_18_TFAULT" 16497945 "DTC_MBB_19_TFAULT" 16497952 "DTC_MBB_20_TFAULT" 16497953 "DTC_MBB_21_TFAULT" 16497954 "DTC_MBB_22_TFAULT" 16497955 "DTC_MBB_23_TFAULT" 16497956 "DTC_MBB_24_TFAULT" 15785984 "DTC_PRECHARGE_ENERGY" 15785985 "DTC_PRT_FAILED" 15785986 "DTC_PRT_OVERTEMP" 15785987 "DTC_PRT_PROHIBIT" 16556032 "DTC_COOLANT_TEMP_OOR_HI" 16556033 "DTC_COOLANT_TEMP_OOR_LO" 16252928 "DTC_KEY_OFF_TIME_ERROR" 16506880 "DTC_VBAT_MISMATCH" 16506881 "DTC_VBAT_VMAX" 16506882 "DTC_VBAT_VMIN" 16506883 "DTC_PACK_FUSE" 15798544 "DTC_LLS1_OOR_HI" 15798545 "DTC_LLS1_OOR_LO" 15798546 "DTC_LLS1_FAULT" 15798816 "DTC_LLS2_OOR_HI" 15798817 "DTC_LLS2_OOR_LO" 15798818 "DTC_LLS2_FAULT" 14479360 "DTC_CFL_HEARTBEAT" 14479361 "DTC_CFL_FAULT" 14479362 "DTC_CFL_FAULT_LATCH" 13635584 "DTC_CONT_A_FAILED_HI" 13635585 "DTC_CONT_A_FAILED_LO" 13635586 "DTC_CONT_B_FAILED_HI" 13635587 "DTC_CONT_B_FAILED_LO" 13635588 "DTC_CONT_C_FAILED_HI" 13635589 "DTC_CONT_C_FAILED_LO" 13635590 "DTC_CONT_D_FAILED_HI" 13635591 "DTC_CONT_D_FAILED_LO" 13635592 "DTC_CONT_E_FAILED_HI" 13635593 "DTC_CONT_E_FAILED_LO" 13635594 "DTC_CONT_F_FAILED_HI" 13635595 "DTC_CONT_F_FAILED_LO" 13635596 "DTC_CONT_G_FAILED_HI" 13635597 "DTC_CONT_G_FAILED_LO" 13635598 "DTC_LSD_A_FAILED_HI" 13635599 "DTC_LSD_A_FAILED_LO" 13635600 "DTC_LSD_B_FAILED_HI" 13635601 "DTC_LSD_B_FAILED_LO" 13635602 "DTC_LSD_C_FAILED_HI" 13635603 "DTC_LSD_C_FAILED_LO" 13635606 "DTC_CONT_PWR_FAILED_HI" 13635607 "DTC_CONT_PWR_FAILED_LO" 13635608 "DTC_LSD_PUMP_FAILED_HI" 13635609 "DTC_LSD_PUMP_FAILED_LO" 13635610 "DTC_CHG_A_ENABLE_FAILED_HI" 13635611 "DTC_CHG_A_ENABLE_FAILED_LO" 13635612 "DTC_CHG_B_ENABLE_FAILED_HI" 13635613 "DTC_CHG_B_ENABLE_FAILED_LO" 13635614 "DTC_SW14V_PWR_FAILED_HI" 13635615 "DTC_SW14V_PWR_FAILED_LO" 13635620 "DTC_HSD_A_FAILED_HI" 13635621 "DTC_HSD_A_FAILED_LO" 13635622 "DTC_HSD_B_FAILED_HI" 13635623 "DTC_HSD_B_FAILED_LO" 13692968 "DTC_CONT_HPWR_FAILED_HI" 13692969 "DTC_CONT_HPWR_FAILED_LO" 13692970 "DTC_CONT_HPWR_OOR_HI" 13692971 "DTC_CONT_HPWR_OOR_LO" 13635616 "DTC_5V_PWR_OOR_HI" 13635617 "DTC_5V_PWR_OOR_LO" 14606336 "DTC_NVM_WRITE_TO" 14606337 "DTC_NVM_READ_TO" 14614528 "DTC_SPI_DIG_POT_FAULT" ;
VAL_ 1120 bcm_dtc_006 0 " - " 11276288 "DTC_VEPO" 11276289 "DTC_HSC_MISSING" 11460608 "DTC_NVM_SOC" 11460609 "DTC_NVM_KOT" 11460610 "DTC_NVM_DTC" 11460611 "DTC_NVM_SOC_CORRECTION" 11460612 "DTC_NVM_APP_SCRATCHPAD" 11517962 "DTC_LOOPTIME_TASK_A" 11517963 "DTC_LOOPTIME_TASK_B" 11517964 "DTC_LOOPTIME_TASK_C" 11517965 "DTC_LOOPTIME_TASK_D" 11517966 "DTC_LOOPTIME_TASK_E" 11517967 "DTC_LOOPTIME_TASK_F" 11323904 "DTC_INTERLOCK_A_FAILED_LOW" 11323905 "DTC_INTERLOCK_A_FAILED_HIGH" 11324160 "DTC_INTERLOCK_B_FAILED_LOW" 11324161 "DTC_INTERLOCK_B_FAILED_HIGH" 15728640 "DTC_EPO" 16498688 "DTC_BRUSA_MISSING" 16498689 "DTC_BRUSA_IDC" 16498690 "DTC_BRUSA_REQ_VS_CMD" 16433152 "DTC_AKERWADE_MISSING" 16433153 "DTC_AKERWADE_IDC" 16433154 "DTC_AKERWADE_REQ_VS_CMD" 16564224 "DTC_CHGLEAR_MISSING" 16564225 "DTC_CHGLEAR_IDC" 16564226 "DTC_CHGLEAR_REQ_VS_CMD" 16522240 "DTC_CSM_MISSING" 16522752 "DTC_CSM_VBAT" 16522753 "DTC_CSM_VPOS" 16522754 "DTC_CSM_VNEG" 16522755 "DTC_CSM_CPOS" 16522756 "DTC_CSM_CNEG" 16522757 "DTC_CSM_APOS" 16522758 "DTC_CSM_ANEG" 16522759 "DTC_CSM_FUSE_HI" 16522760 "DTC_CSM_FUSE_LO" 16521728 "DTC_CSM_ASIC" 16521729 "DTC_CSM_AILO" 16521730 "DTC_CSM_AIHI" 16520957 "DTC_LEAKAGE_DETECT_FAULT" 16522444 "DTC_REALTIMECLOCK_FAULT" 16520945 "DTC_CSM_LEAK_FAIL_CALC" 16520946 "DTC_CSM_LEAK_FAIL_HW" 16520947 "DTC_CSM_LEAK_EXT_SHORT" 16520948 "DTC_CSM_LEAK_MID_PACK_SHORT" 16520949 "DTC_CSM_LEAK_ERROR" 16520950 "DTC_CSM_LEAK_UNKNOWN" 16523008 "DTC_CSM_VER_MISMATCH" 16523009 "DTC_CSM_DTC_SET" 16523010 "DTC_CSM_CAL_FAULT" 16560128 "DTC_IBAT_MISMATCH" 16576512 "DTC_DIS_MAX_I2T" 16576513 "DTC_CHG_MAX_I2T" 16576768 "DTC_DIS_WARNING_I2T" 16576769 "DTC_CHG_WARNING_I2T" 11296784 "DTC_SAEJ1772_PROX_DECT_OOR_HI" 11296785 "DTC_SAEJ1772_PROX_DECT_OOR_LO" 11296800 "DTC_SAEJ1772_PILOT_PWM_OOR_HI" 11296801 "DTC_SAEJ1772_PILOT_PWM_OOR_LO" 11296802 "DTC_SAEJ1772_PILOT_PWM_DIG_COMM" 11296803 "DTC_SAEJ1772_PILOT_PWM_IR_ERR" 16175360 "DTC_FGD1_NO_SENSOR" 16175361 "DTC_FGD1_OOR_HI" 16175362 "DTC_FGD1_OOR_LO" 16175363 "DTC_FGD1_FAULT" 16175616 "DTC_FGD2_NO_SENSOR" 16175617 "DTC_FGD2_OOR_HI" 16175618 "DTC_FGD2_OOR_LO" 16175619 "DTC_FGD2_FAULT" 16171008 "DTC_CONT_OPEN" 16171009 "DTC_CONT_CLOSE" 16171010 "DTC_CONT_OPEN_CURRENT" 16171264 "DTC_CONT_CLOSE_ON_RESET" 16171265 "DTC_CONT_CLOSE_SIG_FAILED" 16171520 "DTC_PRECHARGE_TIMEOUT" 16171777 "DTC_CONT_MPOS_WELD_AT_SU" 16171778 "DTC_CONT_MNEG_WELD_AT_SU" 16171780 "DTC_CONT_CPOS_WELD_AT_SU" 16171781 "DTC_CONT_CNEG_WELD_AT_SU" 16171782 "DTC_CONT_ANEG_WELD_AT_SU" 16171783 "DTC_CONT_APOS_WELD_AT_SU" 16172033 "DTC_CONT_MPOS_WELD_AT_SD" 16172034 "DTC_CONT_MNEG_WELD_AT_SD" 16172036 "DTC_CONT_CPOS_WELD_AT_SD" 16172037 "DTC_CONT_CNEG_WELD_AT_SD" 16172038 "DTC_CONT_ANEG_WELD_AT_SD" 16172039 "DTC_CONT_APOS_WELD_AT_SD" 16172289 "DTC_CONT_MPOS_OPEN" 16172290 "DTC_CONT_MNEG_OPEN" 16172291 "DTC_CONT_MPRE_OPEN" 16172292 "DTC_CONT_CPOS_OPEN" 16172293 "DTC_CONT_CNEG_OPEN" 16172294 "DTC_CONT_APOS_OPEN" 16172295 "DTC_CONT_ANEG_OPEN" 16172545 "DTC_CONT_MPOS_VDIF" 16172546 "DTC_CONT_MNEG_VDIF" 16172548 "DTC_CONT_CPOS_VDIF" 16172549 "DTC_CONT_CNEG_VDIF" 16172550 "DTC_CONT_APOS_VDIF" 16172551 "DTC_CONT_ANEG_VDIF" 16174848 "DTC_HVIL" 16174849 "DTC_LVBAT_LO" 16174850 "DTC_LVBAT_HI" 16174851 "DTC_LVBAT_ERR" 16523520 "DTC_LEMLO_OOR_HI" 16523521 "DTC_LEMLO_OOR_LO" 16523522 "DTC_LEMLO_FAULT" 16523776 "DTC_LEMHI_OOR_HI" 16523777 "DTC_LEMHI_OOR_LO" 16523778 "DTC_LEMHI_FAULT" 16496320 "DTC_MBB_TOO_FEW" 16496321 "DTC_MBB_TOO_MANY" 16496352 "DTC_CELL_VMAX_ERR" 16496353 "DTC_CELL_VMIN_ERR" 16496354 "DTC_CELL_VMAX" 16496362 "DTC_CELL_VMAX_SEVERE" 16496355 "DTC_CELL_VMIN" 16496363 "DTC_CELL_VMIN_SEVERE" 16496356 "DTC_MOD_VOLTAGE_COMPARE" 16496336 "DTC_CELL_T_ERR" 16496337 "DTC_CELL_TMAX1" 16496338 "DTC_CELL_TMAX2" 16496339 "DTC_CELL_TMIN" 16497665 "DTC_MBB_01_MISSING" 16497666 "DTC_MBB_02_MISSING" 16497667 "DTC_MBB_03_MISSING" 16497668 "DTC_MBB_04_MISSING" 16497669 "DTC_MBB_05_MISSING" 16497670 "DTC_MBB_06_MISSING" 16497671 "DTC_MBB_07_MISSING" 16497672 "DTC_MBB_08_MISSING" 16497673 "DTC_MBB_09_MISSING" 16497680 "DTC_MBB_10_MISSING" 16497681 "DTC_MBB_11_MISSING" 16497682 "DTC_MBB_12_MISSING" 16497683 "DTC_MBB_13_MISSING" 16497684 "DTC_MBB_14_MISSING" 16497685 "DTC_MBB_15_MISSING" 16497686 "DTC_MBB_16_MISSING" 16497687 "DTC_MBB_17_MISSING" 16497688 "DTC_MBB_18_MISSING" 16497689 "DTC_MBB_19_MISSING" 16497696 "DTC_MBB_20_MISSING" 16497697 "DTC_MBB_21_MISSING" 16497698 "DTC_MBB_22_MISSING" 16497699 "DTC_MBB_23_MISSING" 16497700 "DTC_MBB_24_MISSING" 16498177 "DTC_MBB_01_VFAULT" 16498178 "DTC_MBB_02_VFAULT" 16498179 "DTC_MBB_03_VFAULT" 16498180 "DTC_MBB_04_VFAULT" 16498181 "DTC_MBB_05_VFAULT" 16498182 "DTC_MBB_06_VFAULT" 16498183 "DTC_MBB_07_VFAULT" 16498184 "DTC_MBB_08_VFAULT" 16498185 "DTC_MBB_09_VFAULT" 16498192 "DTC_MBB_10_VFAULT" 16498193 "DTC_MBB_11_VFAULT" 16498194 "DTC_MBB_12_VFAULT" 16498195 "DTC_MBB_13_VFAULT" 16498196 "DTC_MBB_14_VFAULT" 16498197 "DTC_MBB_15_VFAULT" 16498198 "DTC_MBB_16_VFAULT" 16498199 "DTC_MBB_17_VFAULT" 16498200 "DTC_MBB_18_VFAULT" 16498201 "DTC_MBB_19_VFAULT" 16498208 "DTC_MBB_20_VFAULT" 16498209 "DTC_MBB_21_VFAULT" 16498210 "DTC_MBB_22_VFAULT" 16498211 "DTC_MBB_23_VFAULT" 16498212 "DTC_MBB_24_VFAULT" 16497921 "DTC_MBB_01_TFAULT" 16497922 "DTC_MBB_02_TFAULT" 16497923 "DTC_MBB_03_TFAULT" 16497924 "DTC_MBB_04_TFAULT" 16497925 "DTC_MBB_05_TFAULT" 16497926 "DTC_MBB_06_TFAULT" 16497927 "DTC_MBB_07_TFAULT" 16497928 "DTC_MBB_08_TFAULT" 16497929 "DTC_MBB_09_TFAULT" 16497936 "DTC_MBB_10_TFAULT" 16497937 "DTC_MBB_11_TFAULT" 16497938 "DTC_MBB_12_TFAULT" 16497939 "DTC_MBB_13_TFAULT" 16497940 "DTC_MBB_14_TFAULT" 16497941 "DTC_MBB_15_TFAULT" 16497942 "DTC_MBB_16_TFAULT" 16497943 "DTC_MBB_17_TFAULT" 16497944 "DTC_MBB_18_TFAULT" 16497945 "DTC_MBB_19_TFAULT" 16497952 "DTC_MBB_20_TFAULT" 16497953 "DTC_MBB_21_TFAULT" 16497954 "DTC_MBB_22_TFAULT" 16497955 "DTC_MBB_23_TFAULT" 16497956 "DTC_MBB_24_TFAULT" 15785984 "DTC_PRECHARGE_ENERGY" 15785985 "DTC_PRT_FAILED" 15785986 "DTC_PRT_OVERTEMP" 15785987 "DTC_PRT_PROHIBIT" 16556032 "DTC_COOLANT_TEMP_OOR_HI" 16556033 "DTC_COOLANT_TEMP_OOR_LO" 16252928 "DTC_KEY_OFF_TIME_ERROR" 16506880 "DTC_VBAT_MISMATCH" 16506881 "DTC_VBAT_VMAX" 16506882 "DTC_VBAT_VMIN" 16506883 "DTC_PACK_FUSE" 15798544 "DTC_LLS1_OOR_HI" 15798545 "DTC_LLS1_OOR_LO" 15798546 "DTC_LLS1_FAULT" 15798816 "DTC_LLS2_OOR_HI" 15798817 "DTC_LLS2_OOR_LO" 15798818 "DTC_LLS2_FAULT" 14479360 "DTC_CFL_HEARTBEAT" 14479361 "DTC_CFL_FAULT" 14479362 "DTC_CFL_FAULT_LATCH" 13635584 "DTC_CONT_A_FAILED_HI" 13635585 "DTC_CONT_A_FAILED_LO" 13635586 "DTC_CONT_B_FAILED_HI" 13635587 "DTC_CONT_B_FAILED_LO" 13635588 "DTC_CONT_C_FAILED_HI" 13635589 "DTC_CONT_C_FAILED_LO" 13635590 "DTC_CONT_D_FAILED_HI" 13635591 "DTC_CONT_D_FAILED_LO" 13635592 "DTC_CONT_E_FAILED_HI" 13635593 "DTC_CONT_E_FAILED_LO" 13635594 "DTC_CONT_F_FAILED_HI" 13635595 "DTC_CONT_F_FAILED_LO" 13635596 "DTC_CONT_G_FAILED_HI" 13635597 "DTC_CONT_G_FAILED_LO" 13635598 "DTC_LSD_A_FAILED_HI" 13635599 "DTC_LSD_A_FAILED_LO" 13635600 "DTC_LSD_B_FAILED_HI" 13635601 "DTC_LSD_B_FAILED_LO" 13635602 "DTC_LSD_C_FAILED_HI" 13635603 "DTC_LSD_C_FAILED_LO" 13635606 "DTC_CONT_PWR_FAILED_HI" 13635607 "DTC_CONT_PWR_FAILED_LO" 13635608 "DTC_LSD_PUMP_FAILED_HI" 13635609 "DTC_LSD_PUMP_FAILED_LO" 13635610 "DTC_CHG_A_ENABLE_FAILED_HI" 13635611 "DTC_CHG_A_ENABLE_FAILED_LO" 13635612 "DTC_CHG_B_ENABLE_FAILED_HI" 13635613 "DTC_CHG_B_ENABLE_FAILED_LO" 13635614 "DTC_SW14V_PWR_FAILED_HI" 13635615 "DTC_SW14V_PWR_FAILED_LO" 13635620 "DTC_HSD_A_FAILED_HI" 13635621 "DTC_HSD_A_FAILED_LO" 13635622 "DTC_HSD_B_FAILED_HI" 13635623 "DTC_HSD_B_FAILED_LO" 13692968 "DTC_CONT_HPWR_FAILED_HI" 13692969 "DTC_CONT_HPWR_FAILED_LO" 13692970 "DTC_CONT_HPWR_OOR_HI" 13692971 "DTC_CONT_HPWR_OOR_LO" 13635616 "DTC_5V_PWR_OOR_HI" 13635617 "DTC_5V_PWR_OOR_LO" 14606336 "DTC_NVM_WRITE_TO" 14606337 "DTC_NVM_READ_TO" 14614528 "DTC_SPI_DIG_POT_FAULT" ;
VAL_ 1120 bcm_dtc_007 0 " - " 11276288 "DTC_VEPO" 11276289 "DTC_HSC_MISSING" 11460608 "DTC_NVM_SOC" 11460609 "DTC_NVM_KOT" 11460610 "DTC_NVM_DTC" 11460611 "DTC_NVM_SOC_CORRECTION" 11460612 "DTC_NVM_APP_SCRATCHPAD" 11517962 "DTC_LOOPTIME_TASK_A" 11517963 "DTC_LOOPTIME_TASK_B" 11517964 "DTC_LOOPTIME_TASK_C" 11517965 "DTC_LOOPTIME_TASK_D" 11517966 "DTC_LOOPTIME_TASK_E" 11517967 "DTC_LOOPTIME_TASK_F" 11323904 "DTC_INTERLOCK_A_FAILED_LOW" 11323905 "DTC_INTERLOCK_A_FAILED_HIGH" 11324160 "DTC_INTERLOCK_B_FAILED_LOW" 11324161 "DTC_INTERLOCK_B_FAILED_HIGH" 15728640 "DTC_EPO" 16498688 "DTC_BRUSA_MISSING" 16498689 "DTC_BRUSA_IDC" 16498690 "DTC_BRUSA_REQ_VS_CMD" 16433152 "DTC_AKERWADE_MISSING" 16433153 "DTC_AKERWADE_IDC" 16433154 "DTC_AKERWADE_REQ_VS_CMD" 16564224 "DTC_CHGLEAR_MISSING" 16564225 "DTC_CHGLEAR_IDC" 16564226 "DTC_CHGLEAR_REQ_VS_CMD" 16522240 "DTC_CSM_MISSING" 16522752 "DTC_CSM_VBAT" 16522753 "DTC_CSM_VPOS" 16522754 "DTC_CSM_VNEG" 16522755 "DTC_CSM_CPOS" 16522756 "DTC_CSM_CNEG" 16522757 "DTC_CSM_APOS" 16522758 "DTC_CSM_ANEG" 16522759 "DTC_CSM_FUSE_HI" 16522760 "DTC_CSM_FUSE_LO" 16521728 "DTC_CSM_ASIC" 16521729 "DTC_CSM_AILO" 16521730 "DTC_CSM_AIHI" 16520957 "DTC_LEAKAGE_DETECT_FAULT" 16522444 "DTC_REALTIMECLOCK_FAULT" 16520945 "DTC_CSM_LEAK_FAIL_CALC" 16520946 "DTC_CSM_LEAK_FAIL_HW" 16520947 "DTC_CSM_LEAK_EXT_SHORT" 16520948 "DTC_CSM_LEAK_MID_PACK_SHORT" 16520949 "DTC_CSM_LEAK_ERROR" 16520950 "DTC_CSM_LEAK_UNKNOWN" 16523008 "DTC_CSM_VER_MISMATCH" 16523009 "DTC_CSM_DTC_SET" 16523010 "DTC_CSM_CAL_FAULT" 16560128 "DTC_IBAT_MISMATCH" 16576512 "DTC_DIS_MAX_I2T" 16576513 "DTC_CHG_MAX_I2T" 16576768 "DTC_DIS_WARNING_I2T" 16576769 "DTC_CHG_WARNING_I2T" 11296784 "DTC_SAEJ1772_PROX_DECT_OOR_HI" 11296785 "DTC_SAEJ1772_PROX_DECT_OOR_LO" 11296800 "DTC_SAEJ1772_PILOT_PWM_OOR_HI" 11296801 "DTC_SAEJ1772_PILOT_PWM_OOR_LO" 11296802 "DTC_SAEJ1772_PILOT_PWM_DIG_COMM" 11296803 "DTC_SAEJ1772_PILOT_PWM_IR_ERR" 16175360 "DTC_FGD1_NO_SENSOR" 16175361 "DTC_FGD1_OOR_HI" 16175362 "DTC_FGD1_OOR_LO" 16175363 "DTC_FGD1_FAULT" 16175616 "DTC_FGD2_NO_SENSOR" 16175617 "DTC_FGD2_OOR_HI" 16175618 "DTC_FGD2_OOR_LO" 16175619 "DTC_FGD2_FAULT" 16171008 "DTC_CONT_OPEN" 16171009 "DTC_CONT_CLOSE" 16171010 "DTC_CONT_OPEN_CURRENT" 16171264 "DTC_CONT_CLOSE_ON_RESET" 16171265 "DTC_CONT_CLOSE_SIG_FAILED" 16171520 "DTC_PRECHARGE_TIMEOUT" 16171777 "DTC_CONT_MPOS_WELD_AT_SU" 16171778 "DTC_CONT_MNEG_WELD_AT_SU" 16171780 "DTC_CONT_CPOS_WELD_AT_SU" 16171781 "DTC_CONT_CNEG_WELD_AT_SU" 16171782 "DTC_CONT_ANEG_WELD_AT_SU" 16171783 "DTC_CONT_APOS_WELD_AT_SU" 16172033 "DTC_CONT_MPOS_WELD_AT_SD" 16172034 "DTC_CONT_MNEG_WELD_AT_SD" 16172036 "DTC_CONT_CPOS_WELD_AT_SD" 16172037 "DTC_CONT_CNEG_WELD_AT_SD" 16172038 "DTC_CONT_ANEG_WELD_AT_SD" 16172039 "DTC_CONT_APOS_WELD_AT_SD" 16172289 "DTC_CONT_MPOS_OPEN" 16172290 "DTC_CONT_MNEG_OPEN" 16172291 "DTC_CONT_MPRE_OPEN" 16172292 "DTC_CONT_CPOS_OPEN" 16172293 "DTC_CONT_CNEG_OPEN" 16172294 "DTC_CONT_APOS_OPEN" 16172295 "DTC_CONT_ANEG_OPEN" 16172545 "DTC_CONT_MPOS_VDIF" 16172546 "DTC_CONT_MNEG_VDIF" 16172548 "DTC_CONT_CPOS_VDIF" 16172549 "DTC_CONT_CNEG_VDIF" 16172550 "DTC_CONT_APOS_VDIF" 16172551 "DTC_CONT_ANEG_VDIF" 16174848 "DTC_HVIL" 16174849 "DTC_LVBAT_LO" 16174850 "DTC_LVBAT_HI" 16174851 "DTC_LVBAT_ERR" 16523520 "DTC_LEMLO_OOR_HI" 16523521 "DTC_LEMLO_OOR_LO" 16523522 "DTC_LEMLO_FAULT" 16523776 "DTC_LEMHI_OOR_HI" 16523777 "DTC_LEMHI_OOR_LO" 16523778 "DTC_LEMHI_FAULT" 16496320 "DTC_MBB_TOO_FEW" 16496321 "DTC_MBB_TOO_MANY" 16496352 "DTC_CELL_VMAX_ERR" 16496353 "DTC_CELL_VMIN_ERR" 16496354 "DTC_CELL_VMAX" 16496362 "DTC_CELL_VMAX_SEVERE" 16496355 "DTC_CELL_VMIN" 16496363 "DTC_CELL_VMIN_SEVERE" 16496356 "DTC_MOD_VOLTAGE_COMPARE" 16496336 "DTC_CELL_T_ERR" 16496337 "DTC_CELL_TMAX1" 16496338 "DTC_CELL_TMAX2" 16496339 "DTC_CELL_TMIN" 16497665 "DTC_MBB_01_MISSING" 16497666 "DTC_MBB_02_MISSING" 16497667 "DTC_MBB_03_MISSING" 16497668 "DTC_MBB_04_MISSING" 16497669 "DTC_MBB_05_MISSING" 16497670 "DTC_MBB_06_MISSING" 16497671 "DTC_MBB_07_MISSING" 16497672 "DTC_MBB_08_MISSING" 16497673 "DTC_MBB_09_MISSING" 16497680 "DTC_MBB_10_MISSING" 16497681 "DTC_MBB_11_MISSING" 16497682 "DTC_MBB_12_MISSING" 16497683 "DTC_MBB_13_MISSING" 16497684 "DTC_MBB_14_MISSING" 16497685 "DTC_MBB_15_MISSING" 16497686 "DTC_MBB_16_MISSING" 16497687 "DTC_MBB_17_MISSING" 16497688 "DTC_MBB_18_MISSING" 16497689 "DTC_MBB_19_MISSING" 16497696 "DTC_MBB_20_MISSING" 16497697 "DTC_MBB_21_MISSING" 16497698 "DTC_MBB_22_MISSING" 16497699 "DTC_MBB_23_MISSING" 16497700 "DTC_MBB_24_MISSING" 16498177 "DTC_MBB_01_VFAULT" 16498178 "DTC_MBB_02_VFAULT" 16498179 "DTC_MBB_03_VFAULT" 16498180 "DTC_MBB_04_VFAULT" 16498181 "DTC_MBB_05_VFAULT" 16498182 "DTC_MBB_06_VFAULT" 16498183 "DTC_MBB_07_VFAULT" 16498184 "DTC_MBB_08_VFAULT" 16498185 "DTC_MBB_09_VFAULT" 16498192 "DTC_MBB_10_VFAULT" 16498193 "DTC_MBB_11_VFAULT" 16498194 "DTC_MBB_12_VFAULT" 16498195 "DTC_MBB_13_VFAULT" 16498196 "DTC_MBB_14_VFAULT" 16498197 "DTC_MBB_15_VFAULT" 16498198 "DTC_MBB_16_VFAULT" 16498199 "DTC_MBB_17_VFAULT" 16498200 "DTC_MBB_18_VFAULT" 16498201 "DTC_MBB_19_VFAULT" 16498208 "DTC_MBB_20_VFAULT" 16498209 "DTC_MBB_21_VFAULT" 16498210 "DTC_MBB_22_VFAULT" 16498211 "DTC_MBB_23_VFAULT" 16498212 "DTC_MBB_24_VFAULT" 16497921 "DTC_MBB_01_TFAULT" 16497922 "DTC_MBB_02_TFAULT" 16497923 "DTC_MBB_03_TFAULT" 16497924 "DTC_MBB_04_TFAULT" 16497925 "DTC_MBB_05_TFAULT" 16497926 "DTC_MBB_06_TFAULT" 16497927 "DTC_MBB_07_TFAULT" 16497928 "DTC_MBB_08_TFAULT" 16497929 "DTC_MBB_09_TFAULT" 16497936 "DTC_MBB_10_TFAULT" 16497937 "DTC_MBB_11_TFAULT" 16497938 "DTC_MBB_12_TFAULT" 16497939 "DTC_MBB_13_TFAULT" 16497940 "DTC_MBB_14_TFAULT" 16497941 "DTC_MBB_15_TFAULT" 16497942 "DTC_MBB_16_TFAULT" 16497943 "DTC_MBB_17_TFAULT" 16497944 "DTC_MBB_18_TFAULT" 16497945 "DTC_MBB_19_TFAULT" 16497952 "DTC_MBB_20_TFAULT" 16497953 "DTC_MBB_21_TFAULT" 16497954 "DTC_MBB_22_TFAULT" 16497955 "DTC_MBB_23_TFAULT" 16497956 "DTC_MBB_24_TFAULT" 15785984 "DTC_PRECHARGE_ENERGY" 15785985 "DTC_PRT_FAILED" 15785986 "DTC_PRT_OVERTEMP" 15785987 "DTC_PRT_PROHIBIT" 16556032 "DTC_COOLANT_TEMP_OOR_HI" 16556033 "DTC_COOLANT_TEMP_OOR_LO" 16252928 "DTC_KEY_OFF_TIME_ERROR" 16506880 "DTC_VBAT_MISMATCH" 16506881 "DTC_VBAT_VMAX" 16506882 "DTC_VBAT_VMIN" 16506883 "DTC_PACK_FUSE" 15798544 "DTC_LLS1_OOR_HI" 15798545 "DTC_LLS1_OOR_LO" 15798546 "DTC_LLS1_FAULT" 15798816 "DTC_LLS2_OOR_HI" 15798817 "DTC_LLS2_OOR_LO" 15798818 "DTC_LLS2_FAULT" 14479360 "DTC_CFL_HEARTBEAT" 14479361 "DTC_CFL_FAULT" 14479362 "DTC_CFL_FAULT_LATCH" 13635584 "DTC_CONT_A_FAILED_HI" 13635585 "DTC_CONT_A_FAILED_LO" 13635586 "DTC_CONT_B_FAILED_HI" 13635587 "DTC_CONT_B_FAILED_LO" 13635588 "DTC_CONT_C_FAILED_HI" 13635589 "DTC_CONT_C_FAILED_LO" 13635590 "DTC_CONT_D_FAILED_HI" 13635591 "DTC_CONT_D_FAILED_LO" 13635592 "DTC_CONT_E_FAILED_HI" 13635593 "DTC_CONT_E_FAILED_LO" 13635594 "DTC_CONT_F_FAILED_HI" 13635595 "DTC_CONT_F_FAILED_LO" 13635596 "DTC_CONT_G_FAILED_HI" 13635597 "DTC_CONT_G_FAILED_LO" 13635598 "DTC_LSD_A_FAILED_HI" 13635599 "DTC_LSD_A_FAILED_LO" 13635600 "DTC_LSD_B_FAILED_HI" 13635601 "DTC_LSD_B_FAILED_LO" 13635602 "DTC_LSD_C_FAILED_HI" 13635603 "DTC_LSD_C_FAILED_LO" 13635606 "DTC_CONT_PWR_FAILED_HI" 13635607 "DTC_CONT_PWR_FAILED_LO" 13635608 "DTC_LSD_PUMP_FAILED_HI" 13635609 "DTC_LSD_PUMP_FAILED_LO" 13635610 "DTC_CHG_A_ENABLE_FAILED_HI" 13635611 "DTC_CHG_A_ENABLE_FAILED_LO" 13635612 "DTC_CHG_B_ENABLE_FAILED_HI" 13635613 "DTC_CHG_B_ENABLE_FAILED_LO" 13635614 "DTC_SW14V_PWR_FAILED_HI" 13635615 "DTC_SW14V_PWR_FAILED_LO" 13635620 "DTC_HSD_A_FAILED_HI" 13635621 "DTC_HSD_A_FAILED_LO" 13635622 "DTC_HSD_B_FAILED_HI" 13635623 "DTC_HSD_B_FAILED_LO" 13692968 "DTC_CONT_HPWR_FAILED_HI" 13692969 "DTC_CONT_HPWR_FAILED_LO" 13692970 "DTC_CONT_HPWR_OOR_HI" 13692971 "DTC_CONT_HPWR_OOR_LO" 13635616 "DTC_5V_PWR_OOR_HI" 13635617 "DTC_5V_PWR_OOR_LO" 14606336 "DTC_NVM_WRITE_TO" 14606337 "DTC_NVM_READ_TO" 14614528 "DTC_SPI_DIG_POT_FAULT" ;
VAL_ 1120 bcm_dtc_008 0 " - " 11276288 "DTC_VEPO" 11276289 "DTC_HSC_MISSING" 11460608 "DTC_NVM_SOC" 11460609 "DTC_NVM_KOT" 11460610 "DTC_NVM_DTC" 11460611 "DTC_NVM_SOC_CORRECTION" 11460612 "DTC_NVM_APP_SCRATCHPAD" 11517962 "DTC_LOOPTIME_TASK_A" 11517963 "DTC_LOOPTIME_TASK_B" 11517964 "DTC_LOOPTIME_TASK_C" 11517965 "DTC_LOOPTIME_TASK_D" 11517966 "DTC_LOOPTIME_TASK_E" 11517967 "DTC_LOOPTIME_TASK_F" 11323904 "DTC_INTERLOCK_A_FAILED_LOW" 11323905 "DTC_INTERLOCK_A_FAILED_HIGH" 11324160 "DTC_INTERLOCK_B_FAILED_LOW" 11324161 "DTC_INTERLOCK_B_FAILED_HIGH" 15728640 "DTC_EPO" 16498688 "DTC_BRUSA_MISSING" 16498689 "DTC_BRUSA_IDC" 16498690 "DTC_BRUSA_REQ_VS_CMD" 16433152 "DTC_AKERWADE_MISSING" 16433153 "DTC_AKERWADE_IDC" 16433154 "DTC_AKERWADE_REQ_VS_CMD" 16564224 "DTC_CHGLEAR_MISSING" 16564225 "DTC_CHGLEAR_IDC" 16564226 "DTC_CHGLEAR_REQ_VS_CMD" 16522240 "DTC_CSM_MISSING" 16522752 "DTC_CSM_VBAT" 16522753 "DTC_CSM_VPOS" 16522754 "DTC_CSM_VNEG" 16522755 "DTC_CSM_CPOS" 16522756 "DTC_CSM_CNEG" 16522757 "DTC_CSM_APOS" 16522758 "DTC_CSM_ANEG" 16522759 "DTC_CSM_FUSE_HI" 16522760 "DTC_CSM_FUSE_LO" 16521728 "DTC_CSM_ASIC" 16521729 "DTC_CSM_AILO" 16521730 "DTC_CSM_AIHI" 16520957 "DTC_LEAKAGE_DETECT_FAULT" 16522444 "DTC_REALTIMECLOCK_FAULT" 16520945 "DTC_CSM_LEAK_FAIL_CALC" 16520946 "DTC_CSM_LEAK_FAIL_HW" 16520947 "DTC_CSM_LEAK_EXT_SHORT" 16520948 "DTC_CSM_LEAK_MID_PACK_SHORT" 16520949 "DTC_CSM_LEAK_ERROR" 16520950 "DTC_CSM_LEAK_UNKNOWN" 16523008 "DTC_CSM_VER_MISMATCH" 16523009 "DTC_CSM_DTC_SET" 16523010 "DTC_CSM_CAL_FAULT" 16560128 "DTC_IBAT_MISMATCH" 16576512 "DTC_DIS_MAX_I2T" 16576513 "DTC_CHG_MAX_I2T" 16576768 "DTC_DIS_WARNING_I2T" 16576769 "DTC_CHG_WARNING_I2T" 11296784 "DTC_SAEJ1772_PROX_DECT_OOR_HI" 11296785 "DTC_SAEJ1772_PROX_DECT_OOR_LO" 11296800 "DTC_SAEJ1772_PILOT_PWM_OOR_HI" 11296801 "DTC_SAEJ1772_PILOT_PWM_OOR_LO" 11296802 "DTC_SAEJ1772_PILOT_PWM_DIG_COMM" 11296803 "DTC_SAEJ1772_PILOT_PWM_IR_ERR" 16175360 "DTC_FGD1_NO_SENSOR" 16175361 "DTC_FGD1_OOR_HI" 16175362 "DTC_FGD1_OOR_LO" 16175363 "DTC_FGD1_FAULT" 16175616 "DTC_FGD2_NO_SENSOR" 16175617 "DTC_FGD2_OOR_HI" 16175618 "DTC_FGD2_OOR_LO" 16175619 "DTC_FGD2_FAULT" 16171008 "DTC_CONT_OPEN" 16171009 "DTC_CONT_CLOSE" 16171010 "DTC_CONT_OPEN_CURRENT" 16171264 "DTC_CONT_CLOSE_ON_RESET" 16171265 "DTC_CONT_CLOSE_SIG_FAILED" 16171520 "DTC_PRECHARGE_TIMEOUT" 16171777 "DTC_CONT_MPOS_WELD_AT_SU" 16171778 "DTC_CONT_MNEG_WELD_AT_SU" 16171780 "DTC_CONT_CPOS_WELD_AT_SU" 16171781 "DTC_CONT_CNEG_WELD_AT_SU" 16171782 "DTC_CONT_ANEG_WELD_AT_SU" 16171783 "DTC_CONT_APOS_WELD_AT_SU" 16172033 "DTC_CONT_MPOS_WELD_AT_SD" 16172034 "DTC_CONT_MNEG_WELD_AT_SD" 16172036 "DTC_CONT_CPOS_WELD_AT_SD" 16172037 "DTC_CONT_CNEG_WELD_AT_SD" 16172038 "DTC_CONT_ANEG_WELD_AT_SD" 16172039 "DTC_CONT_APOS_WELD_AT_SD" 16172289 "DTC_CONT_MPOS_OPEN" 16172290 "DTC_CONT_MNEG_OPEN" 16172291 "DTC_CONT_MPRE_OPEN" 16172292 "DTC_CONT_CPOS_OPEN" 16172293 "DTC_CONT_CNEG_OPEN" 16172294 "DTC_CONT_APOS_OPEN" 16172295 "DTC_CONT_ANEG_OPEN" 16172545 "DTC_CONT_MPOS_VDIF" 16172546 "DTC_CONT_MNEG_VDIF" 16172548 "DTC_CONT_CPOS_VDIF" 16172549 "DTC_CONT_CNEG_VDIF" 16172550 "DTC_CONT_APOS_VDIF" 16172551 "DTC_CONT_ANEG_VDIF" 16174848 "DTC_HVIL" 16174849 "DTC_LVBAT_LO" 16174850 "DTC_LVBAT_HI" 16174851 "DTC_LVBAT_ERR" 16523520 "DTC_LEMLO_OOR_HI" 16523521 "DTC_LEMLO_OOR_LO" 16523522 "DTC_LEMLO_FAULT" 16523776 "DTC_LEMHI_OOR_HI" 16523777 "DTC_LEMHI_OOR_LO" 16523778 "DTC_LEMHI_FAULT" 16496320 "DTC_MBB_TOO_FEW" 16496321 "DTC_MBB_TOO_MANY" 16496352 "DTC_CELL_VMAX_ERR" 16496353 "DTC_CELL_VMIN_ERR" 16496354 "DTC_CELL_VMAX" 16496362 "DTC_CELL_VMAX_SEVERE" 16496355 "DTC_CELL_VMIN" 16496363 "DTC_CELL_VMIN_SEVERE" 16496356 "DTC_MOD_VOLTAGE_COMPARE" 16496336 "DTC_CELL_T_ERR" 16496337 "DTC_CELL_TMAX1" 16496338 "DTC_CELL_TMAX2" 16496339 "DTC_CELL_TMIN" 16497665 "DTC_MBB_01_MISSING" 16497666 "DTC_MBB_02_MISSING" 16497667 "DTC_MBB_03_MISSING" 16497668 "DTC_MBB_04_MISSING" 16497669 "DTC_MBB_05_MISSING" 16497670 "DTC_MBB_06_MISSING" 16497671 "DTC_MBB_07_MISSING" 16497672 "DTC_MBB_08_MISSING" 16497673 "DTC_MBB_09_MISSING" 16497680 "DTC_MBB_10_MISSING" 16497681 "DTC_MBB_11_MISSING" 16497682 "DTC_MBB_12_MISSING" 16497683 "DTC_MBB_13_MISSING" 16497684 "DTC_MBB_14_MISSING" 16497685 "DTC_MBB_15_MISSING" 16497686 "DTC_MBB_16_MISSING" 16497687 "DTC_MBB_17_MISSING" 16497688 "DTC_MBB_18_MISSING" 16497689 "DTC_MBB_19_MISSING" 16497696 "DTC_MBB_20_MISSING" 16497697 "DTC_MBB_21_MISSING" 16497698 "DTC_MBB_22_MISSING" 16497699 "DTC_MBB_23_MISSING" 16497700 "DTC_MBB_24_MISSING" 16498177 "DTC_MBB_01_VFAULT" 16498178 "DTC_MBB_02_VFAULT" 16498179 "DTC_MBB_03_VFAULT" 16498180 "DTC_MBB_04_VFAULT" 16498181 "DTC_MBB_05_VFAULT" 16498182 "DTC_MBB_06_VFAULT" 16498183 "DTC_MBB_07_VFAULT" 16498184 "DTC_MBB_08_VFAULT" 16498185 "DTC_MBB_09_VFAULT" 16498192 "DTC_MBB_10_VFAULT" 16498193 "DTC_MBB_11_VFAULT" 16498194 "DTC_MBB_12_VFAULT" 16498195 "DTC_MBB_13_VFAULT" 16498196 "DTC_MBB_14_VFAULT" 16498197 "DTC_MBB_15_VFAULT" 16498198 "DTC_MBB_16_VFAULT" 16498199 "DTC_MBB_17_VFAULT" 16498200 "DTC_MBB_18_VFAULT" 16498201 "DTC_MBB_19_VFAULT" 16498208 "DTC_MBB_20_VFAULT" 16498209 "DTC_MBB_21_VFAULT" 16498210 "DTC_MBB_22_VFAULT" 16498211 "DTC_MBB_23_VFAULT" 16498212 "DTC_MBB_24_VFAULT" 16497921 "DTC_MBB_01_TFAULT" 16497922 "DTC_MBB_02_TFAULT" 16497923 "DTC_MBB_03_TFAULT" 16497924 "DTC_MBB_04_TFAULT" 16497925 "DTC_MBB_05_TFAULT" 16497926 "DTC_MBB_06_TFAULT" 16497927 "DTC_MBB_07_TFAULT" 16497928 "DTC_MBB_08_TFAULT" 16497929 "DTC_MBB_09_TFAULT" 16497936 "DTC_MBB_10_TFAULT" 16497937 "DTC_MBB_11_TFAULT" 16497938 "DTC_MBB_12_TFAULT" 16497939 "DTC_MBB_13_TFAULT" 16497940 "DTC_MBB_14_TFAULT" 16497941 "DTC_MBB_15_TFAULT" 16497942 "DTC_MBB_16_TFAULT" 16497943 "DTC_MBB_17_TFAULT" 16497944 "DTC_MBB_18_TFAULT" 16497945 "DTC_MBB_19_TFAULT" 16497952 "DTC_MBB_20_TFAULT" 16497953 "DTC_MBB_21_TFAULT" 16497954 "DTC_MBB_22_TFAULT" 16497955 "DTC_MBB_23_TFAULT" 16497956 "DTC_MBB_24_TFAULT" 15785984 "DTC_PRECHARGE_ENERGY" 15785985 "DTC_PRT_FAILED" 15785986 "DTC_PRT_OVERTEMP" 15785987 "DTC_PRT_PROHIBIT" 16556032 "DTC_COOLANT_TEMP_OOR_HI" 16556033 "DTC_COOLANT_TEMP_OOR_LO" 16252928 "DTC_KEY_OFF_TIME_ERROR" 16506880 "DTC_VBAT_MISMATCH" 16506881 "DTC_VBAT_VMAX" 16506882 "DTC_VBAT_VMIN" 16506883 "DTC_PACK_FUSE" 15798544 "DTC_LLS1_OOR_HI" 15798545 "DTC_LLS1_OOR_LO" 15798546 "DTC_LLS1_FAULT" 15798816 "DTC_LLS2_OOR_HI" 15798817 "DTC_LLS2_OOR_LO" 15798818 "DTC_LLS2_FAULT" 14479360 "DTC_CFL_HEARTBEAT" 14479361 "DTC_CFL_FAULT" 14479362 "DTC_CFL_FAULT_LATCH" 13635584 "DTC_CONT_A_FAILED_HI" 13635585 "DTC_CONT_A_FAILED_LO" 13635586 "DTC_CONT_B_FAILED_HI" 13635587 "DTC_CONT_B_FAILED_LO" 13635588 "DTC_CONT_C_FAILED_HI" 13635589 "DTC_CONT_C_FAILED_LO" 13635590 "DTC_CONT_D_FAILED_HI" 13635591 "DTC_CONT_D_FAILED_LO" 13635592 "DTC_CONT_E_FAILED_HI" 13635593 "DTC_CONT_E_FAILED_LO" 13635594 "DTC_CONT_F_FAILED_HI" 13635595 "DTC_CONT_F_FAILED_LO" 13635596 "DTC_CONT_G_FAILED_HI" 13635597 "DTC_CONT_G_FAILED_LO" 13635598 "DTC_LSD_A_FAILED_HI" 13635599 "DTC_LSD_A_FAILED_LO" 13635600 "DTC_LSD_B_FAILED_HI" 13635601 "DTC_LSD_B_FAILED_LO" 13635602 "DTC_LSD_C_FAILED_HI" 13635603 "DTC_LSD_C_FAILED_LO" 13635606 "DTC_CONT_PWR_FAILED_HI" 13635607 "DTC_CONT_PWR_FAILED_LO" 13635608 "DTC_LSD_PUMP_FAILED_HI" 13635609 "DTC_LSD_PUMP_FAILED_LO" 13635610 "DTC_CHG_A_ENABLE_FAILED_HI" 13635611 "DTC_CHG_A_ENABLE_FAILED_LO" 13635612 "DTC_CHG_B_ENABLE_FAILED_HI" 13635613 "DTC_CHG_B_ENABLE_FAILED_LO" 13635614 "DTC_SW14V_PWR_FAILED_HI" 13635615 "DTC_SW14V_PWR_FAILED_LO" 13635620 "DTC_HSD_A_FAILED_HI" 13635621 "DTC_HSD_A_FAILED_LO" 13635622 "DTC_HSD_B_FAILED_HI" 13635623 "DTC_HSD_B_FAILED_LO" 13692968 "DTC_CONT_HPWR_FAILED_HI" 13692969 "DTC_CONT_HPWR_FAILED_LO" 13692970 "DTC_CONT_HPWR_OOR_HI" 13692971 "DTC_CONT_HPWR_OOR_LO" 13635616 "DTC_5V_PWR_OOR_HI" 13635617 "DTC_5V_PWR_OOR_LO" 14606336 "DTC_NVM_WRITE_TO" 14606337 "DTC_NVM_READ_TO" 14614528 "DTC_SPI_DIG_POT_FAULT" ;
VAL_ 1120 bcm_dtc_009 0 " - " 11276288 "DTC_VEPO" 11276289 "DTC_HSC_MISSING" 11460608 "DTC_NVM_SOC" 11460609 "DTC_NVM_KOT" 11460610 "DTC_NVM_DTC" 11460611 "DTC_NVM_SOC_CORRECTION" 11460612 "DTC_NVM_APP_SCRATCHPAD" 11517962 "DTC_LOOPTIME_TASK_A" 11517963 "DTC_LOOPTIME_TASK_B" 11517964 "DTC_LOOPTIME_TASK_C" 11517965 "DTC_LOOPTIME_TASK_D" 11517966 "DTC_LOOPTIME_TASK_E" 11517967 "DTC_LOOPTIME_TASK_F" 11323904 "DTC_INTERLOCK_A_FAILED_LOW" 11323905 "DTC_INTERLOCK_A_FAILED_HIGH" 11324160 "DTC_INTERLOCK_B_FAILED_LOW" 11324161 "DTC_INTERLOCK_B_FAILED_HIGH" 15728640 "DTC_EPO" 16498688 "DTC_BRUSA_MISSING" 16498689 "DTC_BRUSA_IDC" 16498690 "DTC_BRUSA_REQ_VS_CMD" 16433152 "DTC_AKERWADE_MISSING" 16433153 "DTC_AKERWADE_IDC" 16433154 "DTC_AKERWADE_REQ_VS_CMD" 16564224 "DTC_CHGLEAR_MISSING" 16564225 "DTC_CHGLEAR_IDC" 16564226 "DTC_CHGLEAR_REQ_VS_CMD" 16522240 "DTC_CSM_MISSING" 16522752 "DTC_CSM_VBAT" 16522753 "DTC_CSM_VPOS" 16522754 "DTC_CSM_VNEG" 16522755 "DTC_CSM_CPOS" 16522756 "DTC_CSM_CNEG" 16522757 "DTC_CSM_APOS" 16522758 "DTC_CSM_ANEG" 16522759 "DTC_CSM_FUSE_HI" 16522760 "DTC_CSM_FUSE_LO" 16521728 "DTC_CSM_ASIC" 16521729 "DTC_CSM_AILO" 16521730 "DTC_CSM_AIHI" 16520957 "DTC_LEAKAGE_DETECT_FAULT" 16522444 "DTC_REALTIMECLOCK_FAULT" 16520945 "DTC_CSM_LEAK_FAIL_CALC" 16520946 "DTC_CSM_LEAK_FAIL_HW" 16520947 "DTC_CSM_LEAK_EXT_SHORT" 16520948 "DTC_CSM_LEAK_MID_PACK_SHORT" 16520949 "DTC_CSM_LEAK_ERROR" 16520950 "DTC_CSM_LEAK_UNKNOWN" 16523008 "DTC_CSM_VER_MISMATCH" 16523009 "DTC_CSM_DTC_SET" 16523010 "DTC_CSM_CAL_FAULT" 16560128 "DTC_IBAT_MISMATCH" 16576512 "DTC_DIS_MAX_I2T" 16576513 "DTC_CHG_MAX_I2T" 16576768 "DTC_DIS_WARNING_I2T" 16576769 "DTC_CHG_WARNING_I2T" 11296784 "DTC_SAEJ1772_PROX_DECT_OOR_HI" 11296785 "DTC_SAEJ1772_PROX_DECT_OOR_LO" 11296800 "DTC_SAEJ1772_PILOT_PWM_OOR_HI" 11296801 "DTC_SAEJ1772_PILOT_PWM_OOR_LO" 11296802 "DTC_SAEJ1772_PILOT_PWM_DIG_COMM" 11296803 "DTC_SAEJ1772_PILOT_PWM_IR_ERR" 16175360 "DTC_FGD1_NO_SENSOR" 16175361 "DTC_FGD1_OOR_HI" 16175362 "DTC_FGD1_OOR_LO" 16175363 "DTC_FGD1_FAULT" 16175616 "DTC_FGD2_NO_SENSOR" 16175617 "DTC_FGD2_OOR_HI" 16175618 "DTC_FGD2_OOR_LO" 16175619 "DTC_FGD2_FAULT" 16171008 "DTC_CONT_OPEN" 16171009 "DTC_CONT_CLOSE" 16171010 "DTC_CONT_OPEN_CURRENT" 16171264 "DTC_CONT_CLOSE_ON_RESET" 16171265 "DTC_CONT_CLOSE_SIG_FAILED" 16171520 "DTC_PRECHARGE_TIMEOUT" 16171777 "DTC_CONT_MPOS_WELD_AT_SU" 16171778 "DTC_CONT_MNEG_WELD_AT_SU" 16171780 "DTC_CONT_CPOS_WELD_AT_SU" 16171781 "DTC_CONT_CNEG_WELD_AT_SU" 16171782 "DTC_CONT_ANEG_WELD_AT_SU" 16171783 "DTC_CONT_APOS_WELD_AT_SU" 16172033 "DTC_CONT_MPOS_WELD_AT_SD" 16172034 "DTC_CONT_MNEG_WELD_AT_SD" 16172036 "DTC_CONT_CPOS_WELD_AT_SD" 16172037 "DTC_CONT_CNEG_WELD_AT_SD" 16172038 "DTC_CONT_ANEG_WELD_AT_SD" 16172039 "DTC_CONT_APOS_WELD_AT_SD" 16172289 "DTC_CONT_MPOS_OPEN" 16172290 "DTC_CONT_MNEG_OPEN" 16172291 "DTC_CONT_MPRE_OPEN" 16172292 "DTC_CONT_CPOS_OPEN" 16172293 "DTC_CONT_CNEG_OPEN" 16172294 "DTC_CONT_APOS_OPEN" 16172295 "DTC_CONT_ANEG_OPEN" 16172545 "DTC_CONT_MPOS_VDIF" 16172546 "DTC_CONT_MNEG_VDIF" 16172548 "DTC_CONT_CPOS_VDIF" 16172549 "DTC_CONT_CNEG_VDIF" 16172550 "DTC_CONT_APOS_VDIF" 16172551 "DTC_CONT_ANEG_VDIF" 16174848 "DTC_HVIL" 16174849 "DTC_LVBAT_LO" 16174850 "DTC_LVBAT_HI" 16174851 "DTC_LVBAT_ERR" 16523520 "DTC_LEMLO_OOR_HI" 16523521 "DTC_LEMLO_OOR_LO" 16523522 "DTC_LEMLO_FAULT" 16523776 "DTC_LEMHI_OOR_HI" 16523777 "DTC_LEMHI_OOR_LO" 16523778 "DTC_LEMHI_FAULT" 16496320 "DTC_MBB_TOO_FEW" 16496321 "DTC_MBB_TOO_MANY" 16496352 "DTC_CELL_VMAX_ERR" 16496353 "DTC_CELL_VMIN_ERR" 16496354 "DTC_CELL_VMAX" 16496362 "DTC_CELL_VMAX_SEVERE" 16496355 "DTC_CELL_VMIN" 16496363 "DTC_CELL_VMIN_SEVERE" 16496356 "DTC_MOD_VOLTAGE_COMPARE" 16496336 "DTC_CELL_T_ERR" 16496337 "DTC_CELL_TMAX1" 16496338 "DTC_CELL_TMAX2" 16496339 "DTC_CELL_TMIN" 16497665 "DTC_MBB_01_MISSING" 16497666 "DTC_MBB_02_MISSING" 16497667 "DTC_MBB_03_MISSING" 16497668 "DTC_MBB_04_MISSING" 16497669 "DTC_MBB_05_MISSING" 16497670 "DTC_MBB_06_MISSING" 16497671 "DTC_MBB_07_MISSING" 16497672 "DTC_MBB_08_MISSING" 16497673 "DTC_MBB_09_MISSING" 16497680 "DTC_MBB_10_MISSING" 16497681 "DTC_MBB_11_MISSING" 16497682 "DTC_MBB_12_MISSING" 16497683 "DTC_MBB_13_MISSING" 16497684 "DTC_MBB_14_MISSING" 16497685 "DTC_MBB_15_MISSING" 16497686 "DTC_MBB_16_MISSING" 16497687 "DTC_MBB_17_MISSING" 16497688 "DTC_MBB_18_MISSING" 16497689 "DTC_MBB_19_MISSING" 16497696 "DTC_MBB_20_MISSING" 16497697 "DTC_MBB_21_MISSING" 16497698 "DTC_MBB_22_MISSING" 16497699 "DTC_MBB_23_MISSING" 16497700 "DTC_MBB_24_MISSING" 16498177 "DTC_MBB_01_VFAULT" 16498178 "DTC_MBB_02_VFAULT" 16498179 "DTC_MBB_03_VFAULT" 16498180 "DTC_MBB_04_VFAULT" 16498181 "DTC_MBB_05_VFAULT" 16498182 "DTC_MBB_06_VFAULT" 16498183 "DTC_MBB_07_VFAULT" 16498184 "DTC_MBB_08_VFAULT" 16498185 "DTC_MBB_09_VFAULT" 16498192 "DTC_MBB_10_VFAULT" 16498193 "DTC_MBB_11_VFAULT" 16498194 "DTC_MBB_12_VFAULT" 16498195 "DTC_MBB_13_VFAULT" 16498196 "DTC_MBB_14_VFAULT" 16498197 "DTC_MBB_15_VFAULT" 16498198 "DTC_MBB_16_VFAULT" 16498199 "DTC_MBB_17_VFAULT" 16498200 "DTC_MBB_18_VFAULT" 16498201 "DTC_MBB_19_VFAULT" 16498208 "DTC_MBB_20_VFAULT" 16498209 "DTC_MBB_21_VFAULT" 16498210 "DTC_MBB_22_VFAULT" 16498211 "DTC_MBB_23_VFAULT" 16498212 "DTC_MBB_24_VFAULT" 16497921 "DTC_MBB_01_TFAULT" 16497922 "DTC_MBB_02_TFAULT" 16497923 "DTC_MBB_03_TFAULT" 16497924 "DTC_MBB_04_TFAULT" 16497925 "DTC_MBB_05_TFAULT" 16497926 "DTC_MBB_06_TFAULT" 16497927 "DTC_MBB_07_TFAULT" 16497928 "DTC_MBB_08_TFAULT" 16497929 "DTC_MBB_09_TFAULT" 16497936 "DTC_MBB_10_TFAULT" 16497937 "DTC_MBB_11_TFAULT" 16497938 "DTC_MBB_12_TFAULT" 16497939 "DTC_MBB_13_TFAULT" 16497940 "DTC_MBB_14_TFAULT" 16497941 "DTC_MBB_15_TFAULT" 16497942 "DTC_MBB_16_TFAULT" 16497943 "DTC_MBB_17_TFAULT" 16497944 "DTC_MBB_18_TFAULT" 16497945 "DTC_MBB_19_TFAULT" 16497952 "DTC_MBB_20_TFAULT" 16497953 "DTC_MBB_21_TFAULT" 16497954 "DTC_MBB_22_TFAULT" 16497955 "DTC_MBB_23_TFAULT" 16497956 "DTC_MBB_24_TFAULT" 15785984 "DTC_PRECHARGE_ENERGY" 15785985 "DTC_PRT_FAILED" 15785986 "DTC_PRT_OVERTEMP" 15785987 "DTC_PRT_PROHIBIT" 16556032 "DTC_COOLANT_TEMP_OOR_HI" 16556033 "DTC_COOLANT_TEMP_OOR_LO" 16252928 "DTC_KEY_OFF_TIME_ERROR" 16506880 "DTC_VBAT_MISMATCH" 16506881 "DTC_VBAT_VMAX" 16506882 "DTC_VBAT_VMIN" 16506883 "DTC_PACK_FUSE" 15798544 "DTC_LLS1_OOR_HI" 15798545 "DTC_LLS1_OOR_LO" 15798546 "DTC_LLS1_FAULT" 15798816 "DTC_LLS2_OOR_HI" 15798817 "DTC_LLS2_OOR_LO" 15798818 "DTC_LLS2_FAULT" 14479360 "DTC_CFL_HEARTBEAT" 14479361 "DTC_CFL_FAULT" 14479362 "DTC_CFL_FAULT_LATCH" 13635584 "DTC_CONT_A_FAILED_HI" 13635585 "DTC_CONT_A_FAILED_LO" 13635586 "DTC_CONT_B_FAILED_HI" 13635587 "DTC_CONT_B_FAILED_LO" 13635588 "DTC_CONT_C_FAILED_HI" 13635589 "DTC_CONT_C_FAILED_LO" 13635590 "DTC_CONT_D_FAILED_HI" 13635591 "DTC_CONT_D_FAILED_LO" 13635592 "DTC_CONT_E_FAILED_HI" 13635593 "DTC_CONT_E_FAILED_LO" 13635594 "DTC_CONT_F_FAILED_HI" 13635595 "DTC_CONT_F_FAILED_LO" 13635596 "DTC_CONT_G_FAILED_HI" 13635597 "DTC_CONT_G_FAILED_LO" 13635598 "DTC_LSD_A_FAILED_HI" 13635599 "DTC_LSD_A_FAILED_LO" 13635600 "DTC_LSD_B_FAILED_HI" 13635601 "DTC_LSD_B_FAILED_LO" 13635602 "DTC_LSD_C_FAILED_HI" 13635603 "DTC_LSD_C_FAILED_LO" 13635606 "DTC_CONT_PWR_FAILED_HI" 13635607 "DTC_CONT_PWR_FAILED_LO" 13635608 "DTC_LSD_PUMP_FAILED_HI" 13635609 "DTC_LSD_PUMP_FAILED_LO" 13635610 "DTC_CHG_A_ENABLE_FAILED_HI" 13635611 "DTC_CHG_A_ENABLE_FAILED_LO" 13635612 "DTC_CHG_B_ENABLE_FAILED_HI" 13635613 "DTC_CHG_B_ENABLE_FAILED_LO" 13635614 "DTC_SW14V_PWR_FAILED_HI" 13635615 "DTC_SW14V_PWR_FAILED_LO" 13635620 "DTC_HSD_A_FAILED_HI" 13635621 "DTC_HSD_A_FAILED_LO" 13635622 "DTC_HSD_B_FAILED_HI" 13635623 "DTC_HSD_B_FAILED_LO" 13692968 "DTC_CONT_HPWR_FAILED_HI" 13692969 "DTC_CONT_HPWR_FAILED_LO" 13692970 "DTC_CONT_HPWR_OOR_HI" 13692971 "DTC_CONT_HPWR_OOR_LO" 13635616 "DTC_5V_PWR_OOR_HI" 13635617 "DTC_5V_PWR_OOR_LO" 14606336 "DTC_NVM_WRITE_TO" 14606337 "DTC_NVM_READ_TO" 14614528 "DTC_SPI_DIG_POT_FAULT" ;
VAL_ 1120 bcm_dtc_010 0 " - " 11276288 "DTC_VEPO" 11276289 "DTC_HSC_MISSING" 11460608 "DTC_NVM_SOC" 11460609 "DTC_NVM_KOT" 11460610 "DTC_NVM_DTC" 11460611 "DTC_NVM_SOC_CORRECTION" 11460612 "DTC_NVM_APP_SCRATCHPAD" 11517962 "DTC_LOOPTIME_TASK_A" 11517963 "DTC_LOOPTIME_TASK_B" 11517964 "DTC_LOOPTIME_TASK_C" 11517965 "DTC_LOOPTIME_TASK_D" 11517966 "DTC_LOOPTIME_TASK_E" 11517967 "DTC_LOOPTIME_TASK_F" 11323904 "DTC_INTERLOCK_A_FAILED_LOW" 11323905 "DTC_INTERLOCK_A_FAILED_HIGH" 11324160 "DTC_INTERLOCK_B_FAILED_LOW" 11324161 "DTC_INTERLOCK_B_FAILED_HIGH" 15728640 "DTC_EPO" 16498688 "DTC_BRUSA_MISSING" 16498689 "DTC_BRUSA_IDC" 16498690 "DTC_BRUSA_REQ_VS_CMD" 16433152 "DTC_AKERWADE_MISSING" 16433153 "DTC_AKERWADE_IDC" 16433154 "DTC_AKERWADE_REQ_VS_CMD" 16564224 "DTC_CHGLEAR_MISSING" 16564225 "DTC_CHGLEAR_IDC" 16564226 "DTC_CHGLEAR_REQ_VS_CMD" 16522240 "DTC_CSM_MISSING" 16522752 "DTC_CSM_VBAT" 16522753 "DTC_CSM_VPOS" 16522754 "DTC_CSM_VNEG" 16522755 "DTC_CSM_CPOS" 16522756 "DTC_CSM_CNEG" 16522757 "DTC_CSM_APOS" 16522758 "DTC_CSM_ANEG" 16522759 "DTC_CSM_FUSE_HI" 16522760 "DTC_CSM_FUSE_LO" 16521728 "DTC_CSM_ASIC" 16521729 "DTC_CSM_AILO" 16521730 "DTC_CSM_AIHI" 16520957 "DTC_LEAKAGE_DETECT_FAULT" 16522444 "DTC_REALTIMECLOCK_FAULT" 16520945 "DTC_CSM_LEAK_FAIL_CALC" 16520946 "DTC_CSM_LEAK_FAIL_HW" 16520947 "DTC_CSM_LEAK_EXT_SHORT" 16520948 "DTC_CSM_LEAK_MID_PACK_SHORT" 16520949 "DTC_CSM_LEAK_ERROR" 16520950 "DTC_CSM_LEAK_UNKNOWN" 16523008 "DTC_CSM_VER_MISMATCH" 16523009 "DTC_CSM_DTC_SET" 16523010 "DTC_CSM_CAL_FAULT" 16560128 "DTC_IBAT_MISMATCH" 16576512 "DTC_DIS_MAX_I2T" 16576513 "DTC_CHG_MAX_I2T" 16576768 "DTC_DIS_WARNING_I2T" 16576769 "DTC_CHG_WARNING_I2T" 11296784 "DTC_SAEJ1772_PROX_DECT_OOR_HI" 11296785 "DTC_SAEJ1772_PROX_DECT_OOR_LO" 11296800 "DTC_SAEJ1772_PILOT_PWM_OOR_HI" 11296801 "DTC_SAEJ1772_PILOT_PWM_OOR_LO" 11296802 "DTC_SAEJ1772_PILOT_PWM_DIG_COMM" 11296803 "DTC_SAEJ1772_PILOT_PWM_IR_ERR" 16175360 "DTC_FGD1_NO_SENSOR" 16175361 "DTC_FGD1_OOR_HI" 16175362 "DTC_FGD1_OOR_LO" 16175363 "DTC_FGD1_FAULT" 16175616 "DTC_FGD2_NO_SENSOR" 16175617 "DTC_FGD2_OOR_HI" 16175618 "DTC_FGD2_OOR_LO" 16175619 "DTC_FGD2_FAULT" 16171008 "DTC_CONT_OPEN" 16171009 "DTC_CONT_CLOSE" 16171010 "DTC_CONT_OPEN_CURRENT" 16171264 "DTC_CONT_CLOSE_ON_RESET" 16171265 "DTC_CONT_CLOSE_SIG_FAILED" 16171520 "DTC_PRECHARGE_TIMEOUT" 16171777 "DTC_CONT_MPOS_WELD_AT_SU" 16171778 "DTC_CONT_MNEG_WELD_AT_SU" 16171780 "DTC_CONT_CPOS_WELD_AT_SU" 16171781 "DTC_CONT_CNEG_WELD_AT_SU" 16171782 "DTC_CONT_ANEG_WELD_AT_SU" 16171783 "DTC_CONT_APOS_WELD_AT_SU" 16172033 "DTC_CONT_MPOS_WELD_AT_SD" 16172034 "DTC_CONT_MNEG_WELD_AT_SD" 16172036 "DTC_CONT_CPOS_WELD_AT_SD" 16172037 "DTC_CONT_CNEG_WELD_AT_SD" 16172038 "DTC_CONT_ANEG_WELD_AT_SD" 16172039 "DTC_CONT_APOS_WELD_AT_SD" 16172289 "DTC_CONT_MPOS_OPEN" 16172290 "DTC_CONT_MNEG_OPEN" 16172291 "DTC_CONT_MPRE_OPEN" 16172292 "DTC_CONT_CPOS_OPEN" 16172293 "DTC_CONT_CNEG_OPEN" 16172294 "DTC_CONT_APOS_OPEN" 16172295 "DTC_CONT_ANEG_OPEN" 16172545 "DTC_CONT_MPOS_VDIF" 16172546 "DTC_CONT_MNEG_VDIF" 16172548 "DTC_CONT_CPOS_VDIF" 16172549 "DTC_CONT_CNEG_VDIF" 16172550 "DTC_CONT_APOS_VDIF" 16172551 "DTC_CONT_ANEG_VDIF" 16174848 "DTC_HVIL" 16174849 "DTC_LVBAT_LO" 16174850 "DTC_LVBAT_HI" 16174851 "DTC_LVBAT_ERR" 16523520 "DTC_LEMLO_OOR_HI" 16523521 "DTC_LEMLO_OOR_LO" 16523522 "DTC_LEMLO_FAULT" 16523776 "DTC_LEMHI_OOR_HI" 16523777 "DTC_LEMHI_OOR_LO" 16523778 "DTC_LEMHI_FAULT" 16496320 "DTC_MBB_TOO_FEW" 16496321 "DTC_MBB_TOO_MANY" 16496352 "DTC_CELL_VMAX_ERR" 16496353 "DTC_CELL_VMIN_ERR" 16496354 "DTC_CELL_VMAX" 16496362 "DTC_CELL_VMAX_SEVERE" 16496355 "DTC_CELL_VMIN" 16496363 "DTC_CELL_VMIN_SEVERE" 16496356 "DTC_MOD_VOLTAGE_COMPARE" 16496336 "DTC_CELL_T_ERR" 16496337 "DTC_CELL_TMAX1" 16496338 "DTC_CELL_TMAX2" 16496339 "DTC_CELL_TMIN" 16497665 "DTC_MBB_01_MISSING" 16497666 "DTC_MBB_02_MISSING" 16497667 "DTC_MBB_03_MISSING" 16497668 "DTC_MBB_04_MISSING" 16497669 "DTC_MBB_05_MISSING" 16497670 "DTC_MBB_06_MISSING" 16497671 "DTC_MBB_07_MISSING" 16497672 "DTC_MBB_08_MISSING" 16497673 "DTC_MBB_09_MISSING" 16497680 "DTC_MBB_10_MISSING" 16497681 "DTC_MBB_11_MISSING" 16497682 "DTC_MBB_12_MISSING" 16497683 "DTC_MBB_13_MISSING" 16497684 "DTC_MBB_14_MISSING" 16497685 "DTC_MBB_15_MISSING" 16497686 "DTC_MBB_16_MISSING" 16497687 "DTC_MBB_17_MISSING" 16497688 "DTC_MBB_18_MISSING" 16497689 "DTC_MBB_19_MISSING" 16497696 "DTC_MBB_20_MISSING" 16497697 "DTC_MBB_21_MISSING" 16497698 "DTC_MBB_22_MISSING" 16497699 "DTC_MBB_23_MISSING" 16497700 "DTC_MBB_24_MISSING" 16498177 "DTC_MBB_01_VFAULT" 16498178 "DTC_MBB_02_VFAULT" 16498179 "DTC_MBB_03_VFAULT" 16498180 "DTC_MBB_04_VFAULT" 16498181 "DTC_MBB_05_VFAULT" 16498182 "DTC_MBB_06_VFAULT" 16498183 "DTC_MBB_07_VFAULT" 16498184 "DTC_MBB_08_VFAULT" 16498185 "DTC_MBB_09_VFAULT" 16498192 "DTC_MBB_10_VFAULT" 16498193 "DTC_MBB_11_VFAULT" 16498194 "DTC_MBB_12_VFAULT" 16498195 "DTC_MBB_13_VFAULT" 16498196 "DTC_MBB_14_VFAULT" 16498197 "DTC_MBB_15_VFAULT" 16498198 "DTC_MBB_16_VFAULT" 16498199 "DTC_MBB_17_VFAULT" 16498200 "DTC_MBB_18_VFAULT" 16498201 "DTC_MBB_19_VFAULT" 16498208 "DTC_MBB_20_VFAULT" 16498209 "DTC_MBB_21_VFAULT" 16498210 "DTC_MBB_22_VFAULT" 16498211 "DTC_MBB_23_VFAULT" 16498212 "DTC_MBB_24_VFAULT" 16497921 "DTC_MBB_01_TFAULT" 16497922 "DTC_MBB_02_TFAULT" 16497923 "DTC_MBB_03_TFAULT" 16497924 "DTC_MBB_04_TFAULT" 16497925 "DTC_MBB_05_TFAULT" 16497926 "DTC_MBB_06_TFAULT" 16497927 "DTC_MBB_07_TFAULT" 16497928 "DTC_MBB_08_TFAULT" 16497929 "DTC_MBB_09_TFAULT" 16497936 "DTC_MBB_10_TFAULT" 16497937 "DTC_MBB_11_TFAULT" 16497938 "DTC_MBB_12_TFAULT" 16497939 "DTC_MBB_13_TFAULT" 16497940 "DTC_MBB_14_TFAULT" 16497941 "DTC_MBB_15_TFAULT" 16497942 "DTC_MBB_16_TFAULT" 16497943 "DTC_MBB_17_TFAULT" 16497944 "DTC_MBB_18_TFAULT" 16497945 "DTC_MBB_19_TFAULT" 16497952 "DTC_MBB_20_TFAULT" 16497953 "DTC_MBB_21_TFAULT" 16497954 "DTC_MBB_22_TFAULT" 16497955 "DTC_MBB_23_TFAULT" 16497956 "DTC_MBB_24_TFAULT" 15785984 "DTC_PRECHARGE_ENERGY" 15785985 "DTC_PRT_FAILED" 15785986 "DTC_PRT_OVERTEMP" 15785987 "DTC_PRT_PROHIBIT" 16556032 "DTC_COOLANT_TEMP_OOR_HI" 16556033 "DTC_COOLANT_TEMP_OOR_LO" 16252928 "DTC_KEY_OFF_TIME_ERROR" 16506880 "DTC_VBAT_MISMATCH" 16506881 "DTC_VBAT_VMAX" 16506882 "DTC_VBAT_VMIN" 16506883 "DTC_PACK_FUSE" 15798544 "DTC_LLS1_OOR_HI" 15798545 "DTC_LLS1_OOR_LO" 15798546 "DTC_LLS1_FAULT" 15798816 "DTC_LLS2_OOR_HI" 15798817 "DTC_LLS2_OOR_LO" 15798818 "DTC_LLS2_FAULT" 14479360 "DTC_CFL_HEARTBEAT" 14479361 "DTC_CFL_FAULT" 14479362 "DTC_CFL_FAULT_LATCH" 13635584 "DTC_CONT_A_FAILED_HI" 13635585 "DTC_CONT_A_FAILED_LO" 13635586 "DTC_CONT_B_FAILED_HI" 13635587 "DTC_CONT_B_FAILED_LO" 13635588 "DTC_CONT_C_FAILED_HI" 13635589 "DTC_CONT_C_FAILED_LO" 13635590 "DTC_CONT_D_FAILED_HI" 13635591 "DTC_CONT_D_FAILED_LO" 13635592 "DTC_CONT_E_FAILED_HI" 13635593 "DTC_CONT_E_FAILED_LO" 13635594 "DTC_CONT_F_FAILED_HI" 13635595 "DTC_CONT_F_FAILED_LO" 13635596 "DTC_CONT_G_FAILED_HI" 13635597 "DTC_CONT_G_FAILED_LO" 13635598 "DTC_LSD_A_FAILED_HI" 13635599 "DTC_LSD_A_FAILED_LO" 13635600 "DTC_LSD_B_FAILED_HI" 13635601 "DTC_LSD_B_FAILED_LO" 13635602 "DTC_LSD_C_FAILED_HI" 13635603 "DTC_LSD_C_FAILED_LO" 13635606 "DTC_CONT_PWR_FAILED_HI" 13635607 "DTC_CONT_PWR_FAILED_LO" 13635608 "DTC_LSD_PUMP_FAILED_HI" 13635609 "DTC_LSD_PUMP_FAILED_LO" 13635610 "DTC_CHG_A_ENABLE_FAILED_HI" 13635611 "DTC_CHG_A_ENABLE_FAILED_LO" 13635612 "DTC_CHG_B_ENABLE_FAILED_HI" 13635613 "DTC_CHG_B_ENABLE_FAILED_LO" 13635614 "DTC_SW14V_PWR_FAILED_HI" 13635615 "DTC_SW14V_PWR_FAILED_LO" 13635620 "DTC_HSD_A_FAILED_HI" 13635621 "DTC_HSD_A_FAILED_LO" 13635622 "DTC_HSD_B_FAILED_HI" 13635623 "DTC_HSD_B_FAILED_LO" 13692968 "DTC_CONT_HPWR_FAILED_HI" 13692969 "DTC_CONT_HPWR_FAILED_LO" 13692970 "DTC_CONT_HPWR_OOR_HI" 13692971 "DTC_CONT_HPWR_OOR_LO" 13635616 "DTC_5V_PWR_OOR_HI" 13635617 "DTC_5V_PWR_OOR_LO" 14606336 "DTC_NVM_WRITE_TO" 14606337 "DTC_NVM_READ_TO" 14614528 "DTC_SPI_DIG_POT_FAULT" ;
VAL_ 1120 bcm_dtc_011 0 " - " 11276288 "DTC_VEPO" 11276289 "DTC_HSC_MISSING" 11460608 "DTC_NVM_SOC" 11460609 "DTC_NVM_KOT" 11460610 "DTC_NVM_DTC" 11460611 "DTC_NVM_SOC_CORRECTION" 11460612 "DTC_NVM_APP_SCRATCHPAD" 11517962 "DTC_LOOPTIME_TASK_A" 11517963 "DTC_LOOPTIME_TASK_B" 11517964 "DTC_LOOPTIME_TASK_C" 11517965 "DTC_LOOPTIME_TASK_D" 11517966 "DTC_LOOPTIME_TASK_E" 11517967 "DTC_LOOPTIME_TASK_F" 11323904 "DTC_INTERLOCK_A_FAILED_LOW" 11323905 "DTC_INTERLOCK_A_FAILED_HIGH" 11324160 "DTC_INTERLOCK_B_FAILED_LOW" 11324161 "DTC_INTERLOCK_B_FAILED_HIGH" 15728640 "DTC_EPO" 16498688 "DTC_BRUSA_MISSING" 16498689 "DTC_BRUSA_IDC" 16498690 "DTC_BRUSA_REQ_VS_CMD" 16433152 "DTC_AKERWADE_MISSING" 16433153 "DTC_AKERWADE_IDC" 16433154 "DTC_AKERWADE_REQ_VS_CMD" 16564224 "DTC_CHGLEAR_MISSING" 16564225 "DTC_CHGLEAR_IDC" 16564226 "DTC_CHGLEAR_REQ_VS_CMD" 16522240 "DTC_CSM_MISSING" 16522752 "DTC_CSM_VBAT" 16522753 "DTC_CSM_VPOS" 16522754 "DTC_CSM_VNEG" 16522755 "DTC_CSM_CPOS" 16522756 "DTC_CSM_CNEG" 16522757 "DTC_CSM_APOS" 16522758 "DTC_CSM_ANEG" 16522759 "DTC_CSM_FUSE_HI" 16522760 "DTC_CSM_FUSE_LO" 16521728 "DTC_CSM_ASIC" 16521729 "DTC_CSM_AILO" 16521730 "DTC_CSM_AIHI" 16520957 "DTC_LEAKAGE_DETECT_FAULT" 16522444 "DTC_REALTIMECLOCK_FAULT" 16520945 "DTC_CSM_LEAK_FAIL_CALC" 16520946 "DTC_CSM_LEAK_FAIL_HW" 16520947 "DTC_CSM_LEAK_EXT_SHORT" 16520948 "DTC_CSM_LEAK_MID_PACK_SHORT" 16520949 "DTC_CSM_LEAK_ERROR" 16520950 "DTC_CSM_LEAK_UNKNOWN" 16523008 "DTC_CSM_VER_MISMATCH" 16523009 "DTC_CSM_DTC_SET" 16523010 "DTC_CSM_CAL_FAULT" 16560128 "DTC_IBAT_MISMATCH" 16576512 "DTC_DIS_MAX_I2T" 16576513 "DTC_CHG_MAX_I2T" 16576768 "DTC_DIS_WARNING_I2T" 16576769 "DTC_CHG_WARNING_I2T" 11296784 "DTC_SAEJ1772_PROX_DECT_OOR_HI" 11296785 "DTC_SAEJ1772_PROX_DECT_OOR_LO" 11296800 "DTC_SAEJ1772_PILOT_PWM_OOR_HI" 11296801 "DTC_SAEJ1772_PILOT_PWM_OOR_LO" 11296802 "DTC_SAEJ1772_PILOT_PWM_DIG_COMM" 11296803 "DTC_SAEJ1772_PILOT_PWM_IR_ERR" 16175360 "DTC_FGD1_NO_SENSOR" 16175361 "DTC_FGD1_OOR_HI" 16175362 "DTC_FGD1_OOR_LO" 16175363 "DTC_FGD1_FAULT" 16175616 "DTC_FGD2_NO_SENSOR" 16175617 "DTC_FGD2_OOR_HI" 16175618 "DTC_FGD2_OOR_LO" 16175619 "DTC_FGD2_FAULT" 16171008 "DTC_CONT_OPEN" 16171009 "DTC_CONT_CLOSE" 16171010 "DTC_CONT_OPEN_CURRENT" 16171264 "DTC_CONT_CLOSE_ON_RESET" 16171265 "DTC_CONT_CLOSE_SIG_FAILED" 16171520 "DTC_PRECHARGE_TIMEOUT" 16171777 "DTC_CONT_MPOS_WELD_AT_SU" 16171778 "DTC_CONT_MNEG_WELD_AT_SU" 16171780 "DTC_CONT_CPOS_WELD_AT_SU" 16171781 "DTC_CONT_CNEG_WELD_AT_SU" 16171782 "DTC_CONT_ANEG_WELD_AT_SU" 16171783 "DTC_CONT_APOS_WELD_AT_SU" 16172033 "DTC_CONT_MPOS_WELD_AT_SD" 16172034 "DTC_CONT_MNEG_WELD_AT_SD" 16172036 "DTC_CONT_CPOS_WELD_AT_SD" 16172037 "DTC_CONT_CNEG_WELD_AT_SD" 16172038 "DTC_CONT_ANEG_WELD_AT_SD" 16172039 "DTC_CONT_APOS_WELD_AT_SD" 16172289 "DTC_CONT_MPOS_OPEN" 16172290 "DTC_CONT_MNEG_OPEN" 16172291 "DTC_CONT_MPRE_OPEN" 16172292 "DTC_CONT_CPOS_OPEN" 16172293 "DTC_CONT_CNEG_OPEN" 16172294 "DTC_CONT_APOS_OPEN" 16172295 "DTC_CONT_ANEG_OPEN" 16172545 "DTC_CONT_MPOS_VDIF" 16172546 "DTC_CONT_MNEG_VDIF" 16172548 "DTC_CONT_CPOS_VDIF" 16172549 "DTC_CONT_CNEG_VDIF" 16172550 "DTC_CONT_APOS_VDIF" 16172551 "DTC_CONT_ANEG_VDIF" 16174848 "DTC_HVIL" 16174849 "DTC_LVBAT_LO" 16174850 "DTC_LVBAT_HI" 16174851 "DTC_LVBAT_ERR" 16523520 "DTC_LEMLO_OOR_HI" 16523521 "DTC_LEMLO_OOR_LO" 16523522 "DTC_LEMLO_FAULT" 16523776 "DTC_LEMHI_OOR_HI" 16523777 "DTC_LEMHI_OOR_LO" 16523778 "DTC_LEMHI_FAULT" 16496320 "DTC_MBB_TOO_FEW" 16496321 "DTC_MBB_TOO_MANY" 16496352 "DTC_CELL_VMAX_ERR" 16496353 "DTC_CELL_VMIN_ERR" 16496354 "DTC_CELL_VMAX" 16496362 "DTC_CELL_VMAX_SEVERE" 16496355 "DTC_CELL_VMIN" 16496363 "DTC_CELL_VMIN_SEVERE" 16496356 "DTC_MOD_VOLTAGE_COMPARE" 16496336 "DTC_CELL_T_ERR" 16496337 "DTC_CELL_TMAX1" 16496338 "DTC_CELL_TMAX2" 16496339 "DTC_CELL_TMIN" 16497665 "DTC_MBB_01_MISSING" 16497666 "DTC_MBB_02_MISSING" 16497667 "DTC_MBB_03_MISSING" 16497668 "DTC_MBB_04_MISSING" 16497669 "DTC_MBB_05_MISSING" 16497670 "DTC_MBB_06_MISSING" 16497671 "DTC_MBB_07_MISSING" 16497672 "DTC_MBB_08_MISSING" 16497673 "DTC_MBB_09_MISSING" 16497680 "DTC_MBB_10_MISSING" 16497681 "DTC_MBB_11_MISSING" 16497682 "DTC_MBB_12_MISSING" 16497683 "DTC_MBB_13_MISSING" 16497684 "DTC_MBB_14_MISSING" 16497685 "DTC_MBB_15_MISSING" 16497686 "DTC_MBB_16_MISSING" 16497687 "DTC_MBB_17_MISSING" 16497688 "DTC_MBB_18_MISSING" 16497689 "DTC_MBB_19_MISSING" 16497696 "DTC_MBB_20_MISSING" 16497697 "DTC_MBB_21_MISSING" 16497698 "DTC_MBB_22_MISSING" 16497699 "DTC_MBB_23_MISSING" 16497700 "DTC_MBB_24_MISSING" 16498177 "DTC_MBB_01_VFAULT" 16498178 "DTC_MBB_02_VFAULT" 16498179 "DTC_MBB_03_VFAULT" 16498180 "DTC_MBB_04_VFAULT" 16498181 "DTC_MBB_05_VFAULT" 16498182 "DTC_MBB_06_VFAULT" 16498183 "DTC_MBB_07_VFAULT" 16498184 "DTC_MBB_08_VFAULT" 16498185 "DTC_MBB_09_VFAULT" 16498192 "DTC_MBB_10_VFAULT" 16498193 "DTC_MBB_11_VFAULT" 16498194 "DTC_MBB_12_VFAULT" 16498195 "DTC_MBB_13_VFAULT" 16498196 "DTC_MBB_14_VFAULT" 16498197 "DTC_MBB_15_VFAULT" 16498198 "DTC_MBB_16_VFAULT" 16498199 "DTC_MBB_17_VFAULT" 16498200 "DTC_MBB_18_VFAULT" 16498201 "DTC_MBB_19_VFAULT" 16498208 "DTC_MBB_20_VFAULT" 16498209 "DTC_MBB_21_VFAULT" 16498210 "DTC_MBB_22_VFAULT" 16498211 "DTC_MBB_23_VFAULT" 16498212 "DTC_MBB_24_VFAULT" 16497921 "DTC_MBB_01_TFAULT" 16497922 "DTC_MBB_02_TFAULT" 16497923 "DTC_MBB_03_TFAULT" 16497924 "DTC_MBB_04_TFAULT" 16497925 "DTC_MBB_05_TFAULT" 16497926 "DTC_MBB_06_TFAULT" 16497927 "DTC_MBB_07_TFAULT" 16497928 "DTC_MBB_08_TFAULT" 16497929 "DTC_MBB_09_TFAULT" 16497936 "DTC_MBB_10_TFAULT" 16497937 "DTC_MBB_11_TFAULT" 16497938 "DTC_MBB_12_TFAULT" 16497939 "DTC_MBB_13_TFAULT" 16497940 "DTC_MBB_14_TFAULT" 16497941 "DTC_MBB_15_TFAULT" 16497942 "DTC_MBB_16_TFAULT" 16497943 "DTC_MBB_17_TFAULT" 16497944 "DTC_MBB_18_TFAULT" 16497945 "DTC_MBB_19_TFAULT" 16497952 "DTC_MBB_20_TFAULT" 16497953 "DTC_MBB_21_TFAULT" 16497954 "DTC_MBB_22_TFAULT" 16497955 "DTC_MBB_23_TFAULT" 16497956 "DTC_MBB_24_TFAULT" 15785984 "DTC_PRECHARGE_ENERGY" 15785985 "DTC_PRT_FAILED" 15785986 "DTC_PRT_OVERTEMP" 15785987 "DTC_PRT_PROHIBIT" 16556032 "DTC_COOLANT_TEMP_OOR_HI" 16556033 "DTC_COOLANT_TEMP_OOR_LO" 16252928 "DTC_KEY_OFF_TIME_ERROR" 16506880 "DTC_VBAT_MISMATCH" 16506881 "DTC_VBAT_VMAX" 16506882 "DTC_VBAT_VMIN" 16506883 "DTC_PACK_FUSE" 15798544 "DTC_LLS1_OOR_HI" 15798545 "DTC_LLS1_OOR_LO" 15798546 "DTC_LLS1_FAULT" 15798816 "DTC_LLS2_OOR_HI" 15798817 "DTC_LLS2_OOR_LO" 15798818 "DTC_LLS2_FAULT" 14479360 "DTC_CFL_HEARTBEAT" 14479361 "DTC_CFL_FAULT" 14479362 "DTC_CFL_FAULT_LATCH" 13635584 "DTC_CONT_A_FAILED_HI" 13635585 "DTC_CONT_A_FAILED_LO" 13635586 "DTC_CONT_B_FAILED_HI" 13635587 "DTC_CONT_B_FAILED_LO" 13635588 "DTC_CONT_C_FAILED_HI" 13635589 "DTC_CONT_C_FAILED_LO" 13635590 "DTC_CONT_D_FAILED_HI" 13635591 "DTC_CONT_D_FAILED_LO" 13635592 "DTC_CONT_E_FAILED_HI" 13635593 "DTC_CONT_E_FAILED_LO" 13635594 "DTC_CONT_F_FAILED_HI" 13635595 "DTC_CONT_F_FAILED_LO" 13635596 "DTC_CONT_G_FAILED_HI" 13635597 "DTC_CONT_G_FAILED_LO" 13635598 "DTC_LSD_A_FAILED_HI" 13635599 "DTC_LSD_A_FAILED_LO" 13635600 "DTC_LSD_B_FAILED_HI" 13635601 "DTC_LSD_B_FAILED_LO" 13635602 "DTC_LSD_C_FAILED_HI" 13635603 "DTC_LSD_C_FAILED_LO" 13635606 "DTC_CONT_PWR_FAILED_HI" 13635607 "DTC_CONT_PWR_FAILED_LO" 13635608 "DTC_LSD_PUMP_FAILED_HI" 13635609 "DTC_LSD_PUMP_FAILED_LO" 13635610 "DTC_CHG_A_ENABLE_FAILED_HI" 13635611 "DTC_CHG_A_ENABLE_FAILED_LO" 13635612 "DTC_CHG_B_ENABLE_FAILED_HI" 13635613 "DTC_CHG_B_ENABLE_FAILED_LO" 13635614 "DTC_SW14V_PWR_FAILED_HI" 13635615 "DTC_SW14V_PWR_FAILED_LO" 13635620 "DTC_HSD_A_FAILED_HI" 13635621 "DTC_HSD_A_FAILED_LO" 13635622 "DTC_HSD_B_FAILED_HI" 13635623 "DTC_HSD_B_FAILED_LO" 13692968 "DTC_CONT_HPWR_FAILED_HI" 13692969 "DTC_CONT_HPWR_FAILED_LO" 13692970 "DTC_CONT_HPWR_OOR_HI" 13692971 "DTC_CONT_HPWR_OOR_LO" 13635616 "DTC_5V_PWR_OOR_HI" 13635617 "DTC_5V_PWR_OOR_LO" 14606336 "DTC_NVM_WRITE_TO" 14606337 "DTC_NVM_READ_TO" 14614528 "DTC_SPI_DIG_POT_FAULT" ;
VAL_ 1120 bcm_dtc_012 0 " - " 11276288 "DTC_VEPO" 11276289 "DTC_HSC_MISSING" 11460608 "DTC_NVM_SOC" 11460609 "DTC_NVM_KOT" 11460610 "DTC_NVM_DTC" 11460611 "DTC_NVM_SOC_CORRECTION" 11460612 "DTC_NVM_APP_SCRATCHPAD" 11517962 "DTC_LOOPTIME_TASK_A" 11517963 "DTC_LOOPTIME_TASK_B" 11517964 "DTC_LOOPTIME_TASK_C" 11517965 "DTC_LOOPTIME_TASK_D" 11517966 "DTC_LOOPTIME_TASK_E" 11517967 "DTC_LOOPTIME_TASK_F" 11323904 "DTC_INTERLOCK_A_FAILED_LOW" 11323905 "DTC_INTERLOCK_A_FAILED_HIGH" 11324160 "DTC_INTERLOCK_B_FAILED_LOW" 11324161 "DTC_INTERLOCK_B_FAILED_HIGH" 15728640 "DTC_EPO" 16498688 "DTC_BRUSA_MISSING" 16498689 "DTC_BRUSA_IDC" 16498690 "DTC_BRUSA_REQ_VS_CMD" 16433152 "DTC_AKERWADE_MISSING" 16433153 "DTC_AKERWADE_IDC" 16433154 "DTC_AKERWADE_REQ_VS_CMD" 16564224 "DTC_CHGLEAR_MISSING" 16564225 "DTC_CHGLEAR_IDC" 16564226 "DTC_CHGLEAR_REQ_VS_CMD" 16522240 "DTC_CSM_MISSING" 16522752 "DTC_CSM_VBAT" 16522753 "DTC_CSM_VPOS" 16522754 "DTC_CSM_VNEG" 16522755 "DTC_CSM_CPOS" 16522756 "DTC_CSM_CNEG" 16522757 "DTC_CSM_APOS" 16522758 "DTC_CSM_ANEG" 16522759 "DTC_CSM_FUSE_HI" 16522760 "DTC_CSM_FUSE_LO" 16521728 "DTC_CSM_ASIC" 16521729 "DTC_CSM_AILO" 16521730 "DTC_CSM_AIHI" 16520957 "DTC_LEAKAGE_DETECT_FAULT" 16522444 "DTC_REALTIMECLOCK_FAULT" 16520945 "DTC_CSM_LEAK_FAIL_CALC" 16520946 "DTC_CSM_LEAK_FAIL_HW" 16520947 "DTC_CSM_LEAK_EXT_SHORT" 16520948 "DTC_CSM_LEAK_MID_PACK_SHORT" 16520949 "DTC_CSM_LEAK_ERROR" 16520950 "DTC_CSM_LEAK_UNKNOWN" 16523008 "DTC_CSM_VER_MISMATCH" 16523009 "DTC_CSM_DTC_SET" 16523010 "DTC_CSM_CAL_FAULT" 16560128 "DTC_IBAT_MISMATCH" 16576512 "DTC_DIS_MAX_I2T" 16576513 "DTC_CHG_MAX_I2T" 16576768 "DTC_DIS_WARNING_I2T" 16576769 "DTC_CHG_WARNING_I2T" 11296784 "DTC_SAEJ1772_PROX_DECT_OOR_HI" 11296785 "DTC_SAEJ1772_PROX_DECT_OOR_LO" 11296800 "DTC_SAEJ1772_PILOT_PWM_OOR_HI" 11296801 "DTC_SAEJ1772_PILOT_PWM_OOR_LO" 11296802 "DTC_SAEJ1772_PILOT_PWM_DIG_COMM" 11296803 "DTC_SAEJ1772_PILOT_PWM_IR_ERR" 16175360 "DTC_FGD1_NO_SENSOR" 16175361 "DTC_FGD1_OOR_HI" 16175362 "DTC_FGD1_OOR_LO" 16175363 "DTC_FGD1_FAULT" 16175616 "DTC_FGD2_NO_SENSOR" 16175617 "DTC_FGD2_OOR_HI" 16175618 "DTC_FGD2_OOR_LO" 16175619 "DTC_FGD2_FAULT" 16171008 "DTC_CONT_OPEN" 16171009 "DTC_CONT_CLOSE" 16171010 "DTC_CONT_OPEN_CURRENT" 16171264 "DTC_CONT_CLOSE_ON_RESET" 16171265 "DTC_CONT_CLOSE_SIG_FAILED" 16171520 "DTC_PRECHARGE_TIMEOUT" 16171777 "DTC_CONT_MPOS_WELD_AT_SU" 16171778 "DTC_CONT_MNEG_WELD_AT_SU" 16171780 "DTC_CONT_CPOS_WELD_AT_SU" 16171781 "DTC_CONT_CNEG_WELD_AT_SU" 16171782 "DTC_CONT_ANEG_WELD_AT_SU" 16171783 "DTC_CONT_APOS_WELD_AT_SU" 16172033 "DTC_CONT_MPOS_WELD_AT_SD" 16172034 "DTC_CONT_MNEG_WELD_AT_SD" 16172036 "DTC_CONT_CPOS_WELD_AT_SD" 16172037 "DTC_CONT_CNEG_WELD_AT_SD" 16172038 "DTC_CONT_ANEG_WELD_AT_SD" 16172039 "DTC_CONT_APOS_WELD_AT_SD" 16172289 "DTC_CONT_MPOS_OPEN" 16172290 "DTC_CONT_MNEG_OPEN" 16172291 "DTC_CONT_MPRE_OPEN" 16172292 "DTC_CONT_CPOS_OPEN" 16172293 "DTC_CONT_CNEG_OPEN" 16172294 "DTC_CONT_APOS_OPEN" 16172295 "DTC_CONT_ANEG_OPEN" 16172545 "DTC_CONT_MPOS_VDIF" 16172546 "DTC_CONT_MNEG_VDIF" 16172548 "DTC_CONT_CPOS_VDIF" 16172549 "DTC_CONT_CNEG_VDIF" 16172550 "DTC_CONT_APOS_VDIF" 16172551 "DTC_CONT_ANEG_VDIF" 16174848 "DTC_HVIL" 16174849 "DTC_LVBAT_LO" 16174850 "DTC_LVBAT_HI" 16174851 "DTC_LVBAT_ERR" 16523520 "DTC_LEMLO_OOR_HI" 16523521 "DTC_LEMLO_OOR_LO" 16523522 "DTC_LEMLO_FAULT" 16523776 "DTC_LEMHI_OOR_HI" 16523777 "DTC_LEMHI_OOR_LO" 16523778 "DTC_LEMHI_FAULT" 16496320 "DTC_MBB_TOO_FEW" 16496321 "DTC_MBB_TOO_MANY" 16496352 "DTC_CELL_VMAX_ERR" 16496353 "DTC_CELL_VMIN_ERR" 16496354 "DTC_CELL_VMAX" 16496362 "DTC_CELL_VMAX_SEVERE" 16496355 "DTC_CELL_VMIN" 16496363 "DTC_CELL_VMIN_SEVERE" 16496356 "DTC_MOD_VOLTAGE_COMPARE" 16496336 "DTC_CELL_T_ERR" 16496337 "DTC_CELL_TMAX1" 16496338 "DTC_CELL_TMAX2" 16496339 "DTC_CELL_TMIN" 16497665 "DTC_MBB_01_MISSING" 16497666 "DTC_MBB_02_MISSING" 16497667 "DTC_MBB_03_MISSING" 16497668 "DTC_MBB_04_MISSING" 16497669 "DTC_MBB_05_MISSING" 16497670 "DTC_MBB_06_MISSING" 16497671 "DTC_MBB_07_MISSING" 16497672 "DTC_MBB_08_MISSING" 16497673 "DTC_MBB_09_MISSING" 16497680 "DTC_MBB_10_MISSING" 16497681 "DTC_MBB_11_MISSING" 16497682 "DTC_MBB_12_MISSING" 16497683 "DTC_MBB_13_MISSING" 16497684 "DTC_MBB_14_MISSING" 16497685 "DTC_MBB_15_MISSING" 16497686 "DTC_MBB_16_MISSING" 16497687 "DTC_MBB_17_MISSING" 16497688 "DTC_MBB_18_MISSING" 16497689 "DTC_MBB_19_MISSING" 16497696 "DTC_MBB_20_MISSING" 16497697 "DTC_MBB_21_MISSING" 16497698 "DTC_MBB_22_MISSING" 16497699 "DTC_MBB_23_MISSING" 16497700 "DTC_MBB_24_MISSING" 16498177 "DTC_MBB_01_VFAULT" 16498178 "DTC_MBB_02_VFAULT" 16498179 "DTC_MBB_03_VFAULT" 16498180 "DTC_MBB_04_VFAULT" 16498181 "DTC_MBB_05_VFAULT" 16498182 "DTC_MBB_06_VFAULT" 16498183 "DTC_MBB_07_VFAULT" 16498184 "DTC_MBB_08_VFAULT" 16498185 "DTC_MBB_09_VFAULT" 16498192 "DTC_MBB_10_VFAULT" 16498193 "DTC_MBB_11_VFAULT" 16498194 "DTC_MBB_12_VFAULT" 16498195 "DTC_MBB_13_VFAULT" 16498196 "DTC_MBB_14_VFAULT" 16498197 "DTC_MBB_15_VFAULT" 16498198 "DTC_MBB_16_VFAULT" 16498199 "DTC_MBB_17_VFAULT" 16498200 "DTC_MBB_18_VFAULT" 16498201 "DTC_MBB_19_VFAULT" 16498208 "DTC_MBB_20_VFAULT" 16498209 "DTC_MBB_21_VFAULT" 16498210 "DTC_MBB_22_VFAULT" 16498211 "DTC_MBB_23_VFAULT" 16498212 "DTC_MBB_24_VFAULT" 16497921 "DTC_MBB_01_TFAULT" 16497922 "DTC_MBB_02_TFAULT" 16497923 "DTC_MBB_03_TFAULT" 16497924 "DTC_MBB_04_TFAULT" 16497925 "DTC_MBB_05_TFAULT" 16497926 "DTC_MBB_06_TFAULT" 16497927 "DTC_MBB_07_TFAULT" 16497928 "DTC_MBB_08_TFAULT" 16497929 "DTC_MBB_09_TFAULT" 16497936 "DTC_MBB_10_TFAULT" 16497937 "DTC_MBB_11_TFAULT" 16497938 "DTC_MBB_12_TFAULT" 16497939 "DTC_MBB_13_TFAULT" 16497940 "DTC_MBB_14_TFAULT" 16497941 "DTC_MBB_15_TFAULT" 16497942 "DTC_MBB_16_TFAULT" 16497943 "DTC_MBB_17_TFAULT" 16497944 "DTC_MBB_18_TFAULT" 16497945 "DTC_MBB_19_TFAULT" 16497952 "DTC_MBB_20_TFAULT" 16497953 "DTC_MBB_21_TFAULT" 16497954 "DTC_MBB_22_TFAULT" 16497955 "DTC_MBB_23_TFAULT" 16497956 "DTC_MBB_24_TFAULT" 15785984 "DTC_PRECHARGE_ENERGY" 15785985 "DTC_PRT_FAILED" 15785986 "DTC_PRT_OVERTEMP" 15785987 "DTC_PRT_PROHIBIT" 16556032 "DTC_COOLANT_TEMP_OOR_HI" 16556033 "DTC_COOLANT_TEMP_OOR_LO" 16252928 "DTC_KEY_OFF_TIME_ERROR" 16506880 "DTC_VBAT_MISMATCH" 16506881 "DTC_VBAT_VMAX" 16506882 "DTC_VBAT_VMIN" 16506883 "DTC_PACK_FUSE" 15798544 "DTC_LLS1_OOR_HI" 15798545 "DTC_LLS1_OOR_LO" 15798546 "DTC_LLS1_FAULT" 15798816 "DTC_LLS2_OOR_HI" 15798817 "DTC_LLS2_OOR_LO" 15798818 "DTC_LLS2_FAULT" 14479360 "DTC_CFL_HEARTBEAT" 14479361 "DTC_CFL_FAULT" 14479362 "DTC_CFL_FAULT_LATCH" 13635584 "DTC_CONT_A_FAILED_HI" 13635585 "DTC_CONT_A_FAILED_LO" 13635586 "DTC_CONT_B_FAILED_HI" 13635587 "DTC_CONT_B_FAILED_LO" 13635588 "DTC_CONT_C_FAILED_HI" 13635589 "DTC_CONT_C_FAILED_LO" 13635590 "DTC_CONT_D_FAILED_HI" 13635591 "DTC_CONT_D_FAILED_LO" 13635592 "DTC_CONT_E_FAILED_HI" 13635593 "DTC_CONT_E_FAILED_LO" 13635594 "DTC_CONT_F_FAILED_HI" 13635595 "DTC_CONT_F_FAILED_LO" 13635596 "DTC_CONT_G_FAILED_HI" 13635597 "DTC_CONT_G_FAILED_LO" 13635598 "DTC_LSD_A_FAILED_HI" 13635599 "DTC_LSD_A_FAILED_LO" 13635600 "DTC_LSD_B_FAILED_HI" 13635601 "DTC_LSD_B_FAILED_LO" 13635602 "DTC_LSD_C_FAILED_HI" 13635603 "DTC_LSD_C_FAILED_LO" 13635606 "DTC_CONT_PWR_FAILED_HI" 13635607 "DTC_CONT_PWR_FAILED_LO" 13635608 "DTC_LSD_PUMP_FAILED_HI" 13635609 "DTC_LSD_PUMP_FAILED_LO" 13635610 "DTC_CHG_A_ENABLE_FAILED_HI" 13635611 "DTC_CHG_A_ENABLE_FAILED_LO" 13635612 "DTC_CHG_B_ENABLE_FAILED_HI" 13635613 "DTC_CHG_B_ENABLE_FAILED_LO" 13635614 "DTC_SW14V_PWR_FAILED_HI" 13635615 "DTC_SW14V_PWR_FAILED_LO" 13635620 "DTC_HSD_A_FAILED_HI" 13635621 "DTC_HSD_A_FAILED_LO" 13635622 "DTC_HSD_B_FAILED_HI" 13635623 "DTC_HSD_B_FAILED_LO" 13692968 "DTC_CONT_HPWR_FAILED_HI" 13692969 "DTC_CONT_HPWR_FAILED_LO" 13692970 "DTC_CONT_HPWR_OOR_HI" 13692971 "DTC_CONT_HPWR_OOR_LO" 13635616 "DTC_5V_PWR_OOR_HI" 13635617 "DTC_5V_PWR_OOR_LO" 14606336 "DTC_NVM_WRITE_TO" 14606337 "DTC_NVM_READ_TO" 14614528 "DTC_SPI_DIG_POT_FAULT" ;
VAL_ 1120 bcm_dtc_013 0 " - " 11276288 "DTC_VEPO" 11276289 "DTC_HSC_MISSING" 11460608 "DTC_NVM_SOC" 11460609 "DTC_NVM_KOT" 11460610 "DTC_NVM_DTC" 11460611 "DTC_NVM_SOC_CORRECTION" 11460612 "DTC_NVM_APP_SCRATCHPAD" 11517962 "DTC_LOOPTIME_TASK_A" 11517963 "DTC_LOOPTIME_TASK_B" 11517964 "DTC_LOOPTIME_TASK_C" 11517965 "DTC_LOOPTIME_TASK_D" 11517966 "DTC_LOOPTIME_TASK_E" 11517967 "DTC_LOOPTIME_TASK_F" 11323904 "DTC_INTERLOCK_A_FAILED_LOW" 11323905 "DTC_INTERLOCK_A_FAILED_HIGH" 11324160 "DTC_INTERLOCK_B_FAILED_LOW" 11324161 "DTC_INTERLOCK_B_FAILED_HIGH" 15728640 "DTC_EPO" 16498688 "DTC_BRUSA_MISSING" 16498689 "DTC_BRUSA_IDC" 16498690 "DTC_BRUSA_REQ_VS_CMD" 16433152 "DTC_AKERWADE_MISSING" 16433153 "DTC_AKERWADE_IDC" 16433154 "DTC_AKERWADE_REQ_VS_CMD" 16564224 "DTC_CHGLEAR_MISSING" 16564225 "DTC_CHGLEAR_IDC" 16564226 "DTC_CHGLEAR_REQ_VS_CMD" 16522240 "DTC_CSM_MISSING" 16522752 "DTC_CSM_VBAT" 16522753 "DTC_CSM_VPOS" 16522754 "DTC_CSM_VNEG" 16522755 "DTC_CSM_CPOS" 16522756 "DTC_CSM_CNEG" 16522757 "DTC_CSM_APOS" 16522758 "DTC_CSM_ANEG" 16522759 "DTC_CSM_FUSE_HI" 16522760 "DTC_CSM_FUSE_LO" 16521728 "DTC_CSM_ASIC" 16521729 "DTC_CSM_AILO" 16521730 "DTC_CSM_AIHI" 16520957 "DTC_LEAKAGE_DETECT_FAULT" 16522444 "DTC_REALTIMECLOCK_FAULT" 16520945 "DTC_CSM_LEAK_FAIL_CALC" 16520946 "DTC_CSM_LEAK_FAIL_HW" 16520947 "DTC_CSM_LEAK_EXT_SHORT" 16520948 "DTC_CSM_LEAK_MID_PACK_SHORT" 16520949 "DTC_CSM_LEAK_ERROR" 16520950 "DTC_CSM_LEAK_UNKNOWN" 16523008 "DTC_CSM_VER_MISMATCH" 16523009 "DTC_CSM_DTC_SET" 16523010 "DTC_CSM_CAL_FAULT" 16560128 "DTC_IBAT_MISMATCH" 16576512 "DTC_DIS_MAX_I2T" 16576513 "DTC_CHG_MAX_I2T" 16576768 "DTC_DIS_WARNING_I2T" 16576769 "DTC_CHG_WARNING_I2T" 11296784 "DTC_SAEJ1772_PROX_DECT_OOR_HI" 11296785 "DTC_SAEJ1772_PROX_DECT_OOR_LO" 11296800 "DTC_SAEJ1772_PILOT_PWM_OOR_HI" 11296801 "DTC_SAEJ1772_PILOT_PWM_OOR_LO" 11296802 "DTC_SAEJ1772_PILOT_PWM_DIG_COMM" 11296803 "DTC_SAEJ1772_PILOT_PWM_IR_ERR" 16175360 "DTC_FGD1_NO_SENSOR" 16175361 "DTC_FGD1_OOR_HI" 16175362 "DTC_FGD1_OOR_LO" 16175363 "DTC_FGD1_FAULT" 16175616 "DTC_FGD2_NO_SENSOR" 16175617 "DTC_FGD2_OOR_HI" 16175618 "DTC_FGD2_OOR_LO" 16175619 "DTC_FGD2_FAULT" 16171008 "DTC_CONT_OPEN" 16171009 "DTC_CONT_CLOSE" 16171010 "DTC_CONT_OPEN_CURRENT" 16171264 "DTC_CONT_CLOSE_ON_RESET" 16171265 "DTC_CONT_CLOSE_SIG_FAILED" 16171520 "DTC_PRECHARGE_TIMEOUT" 16171777 "DTC_CONT_MPOS_WELD_AT_SU" 16171778 "DTC_CONT_MNEG_WELD_AT_SU" 16171780 "DTC_CONT_CPOS_WELD_AT_SU" 16171781 "DTC_CONT_CNEG_WELD_AT_SU" 16171782 "DTC_CONT_ANEG_WELD_AT_SU" 16171783 "DTC_CONT_APOS_WELD_AT_SU" 16172033 "DTC_CONT_MPOS_WELD_AT_SD" 16172034 "DTC_CONT_MNEG_WELD_AT_SD" 16172036 "DTC_CONT_CPOS_WELD_AT_SD" 16172037 "DTC_CONT_CNEG_WELD_AT_SD" 16172038 "DTC_CONT_ANEG_WELD_AT_SD" 16172039 "DTC_CONT_APOS_WELD_AT_SD" 16172289 "DTC_CONT_MPOS_OPEN" 16172290 "DTC_CONT_MNEG_OPEN" 16172291 "DTC_CONT_MPRE_OPEN" 16172292 "DTC_CONT_CPOS_OPEN" 16172293 "DTC_CONT_CNEG_OPEN" 16172294 "DTC_CONT_APOS_OPEN" 16172295 "DTC_CONT_ANEG_OPEN" 16172545 "DTC_CONT_MPOS_VDIF" 16172546 "DTC_CONT_MNEG_VDIF" 16172548 "DTC_CONT_CPOS_VDIF" 16172549 "DTC_CONT_CNEG_VDIF" 16172550 "DTC_CONT_APOS_VDIF" 16172551 "DTC_CONT_ANEG_VDIF" 16174848 "DTC_HVIL" 16174849 "DTC_LVBAT_LO" 16174850 "DTC_LVBAT_HI" 16174851 "DTC_LVBAT_ERR" 16523520 "DTC_LEMLO_OOR_HI" 16523521 "DTC_LEMLO_OOR_LO" 16523522 "DTC_LEMLO_FAULT" 16523776 "DTC_LEMHI_OOR_HI" 16523777 "DTC_LEMHI_OOR_LO" 16523778 "DTC_LEMHI_FAULT" 16496320 "DTC_MBB_TOO_FEW" 16496321 "DTC_MBB_TOO_MANY" 16496352 "DTC_CELL_VMAX_ERR" 16496353 "DTC_CELL_VMIN_ERR" 16496354 "DTC_CELL_VMAX" 16496362 "DTC_CELL_VMAX_SEVERE" 16496355 "DTC_CELL_VMIN" 16496363 "DTC_CELL_VMIN_SEVERE" 16496356 "DTC_MOD_VOLTAGE_COMPARE" 16496336 "DTC_CELL_T_ERR" 16496337 "DTC_CELL_TMAX1" 16496338 "DTC_CELL_TMAX2" 16496339 "DTC_CELL_TMIN" 16497665 "DTC_MBB_01_MISSING" 16497666 "DTC_MBB_02_MISSING" 16497667 "DTC_MBB_03_MISSING" 16497668 "DTC_MBB_04_MISSING" 16497669 "DTC_MBB_05_MISSING" 16497670 "DTC_MBB_06_MISSING" 16497671 "DTC_MBB_07_MISSING" 16497672 "DTC_MBB_08_MISSING" 16497673 "DTC_MBB_09_MISSING" 16497680 "DTC_MBB_10_MISSING" 16497681 "DTC_MBB_11_MISSING" 16497682 "DTC_MBB_12_MISSING" 16497683 "DTC_MBB_13_MISSING" 16497684 "DTC_MBB_14_MISSING" 16497685 "DTC_MBB_15_MISSING" 16497686 "DTC_MBB_16_MISSING" 16497687 "DTC_MBB_17_MISSING" 16497688 "DTC_MBB_18_MISSING" 16497689 "DTC_MBB_19_MISSING" 16497696 "DTC_MBB_20_MISSING" 16497697 "DTC_MBB_21_MISSING" 16497698 "DTC_MBB_22_MISSING" 16497699 "DTC_MBB_23_MISSING" 16497700 "DTC_MBB_24_MISSING" 16498177 "DTC_MBB_01_VFAULT" 16498178 "DTC_MBB_02_VFAULT" 16498179 "DTC_MBB_03_VFAULT" 16498180 "DTC_MBB_04_VFAULT" 16498181 "DTC_MBB_05_VFAULT" 16498182 "DTC_MBB_06_VFAULT" 16498183 "DTC_MBB_07_VFAULT" 16498184 "DTC_MBB_08_VFAULT" 16498185 "DTC_MBB_09_VFAULT" 16498192 "DTC_MBB_10_VFAULT" 16498193 "DTC_MBB_11_VFAULT" 16498194 "DTC_MBB_12_VFAULT" 16498195 "DTC_MBB_13_VFAULT" 16498196 "DTC_MBB_14_VFAULT" 16498197 "DTC_MBB_15_VFAULT" 16498198 "DTC_MBB_16_VFAULT" 16498199 "DTC_MBB_17_VFAULT" 16498200 "DTC_MBB_18_VFAULT" 16498201 "DTC_MBB_19_VFAULT" 16498208 "DTC_MBB_20_VFAULT" 16498209 "DTC_MBB_21_VFAULT" 16498210 "DTC_MBB_22_VFAULT" 16498211 "DTC_MBB_23_VFAULT" 16498212 "DTC_MBB_24_VFAULT" 16497921 "DTC_MBB_01_TFAULT" 16497922 "DTC_MBB_02_TFAULT" 16497923 "DTC_MBB_03_TFAULT" 16497924 "DTC_MBB_04_TFAULT" 16497925 "DTC_MBB_05_TFAULT" 16497926 "DTC_MBB_06_TFAULT" 16497927 "DTC_MBB_07_TFAULT" 16497928 "DTC_MBB_08_TFAULT" 16497929 "DTC_MBB_09_TFAULT" 16497936 "DTC_MBB_10_TFAULT" 16497937 "DTC_MBB_11_TFAULT" 16497938 "DTC_MBB_12_TFAULT" 16497939 "DTC_MBB_13_TFAULT" 16497940 "DTC_MBB_14_TFAULT" 16497941 "DTC_MBB_15_TFAULT" 16497942 "DTC_MBB_16_TFAULT" 16497943 "DTC_MBB_17_TFAULT" 16497944 "DTC_MBB_18_TFAULT" 16497945 "DTC_MBB_19_TFAULT" 16497952 "DTC_MBB_20_TFAULT" 16497953 "DTC_MBB_21_TFAULT" 16497954 "DTC_MBB_22_TFAULT" 16497955 "DTC_MBB_23_TFAULT" 16497956 "DTC_MBB_24_TFAULT" 15785984 "DTC_PRECHARGE_ENERGY" 15785985 "DTC_PRT_FAILED" 15785986 "DTC_PRT_OVERTEMP" 15785987 "DTC_PRT_PROHIBIT" 16556032 "DTC_COOLANT_TEMP_OOR_HI" 16556033 "DTC_COOLANT_TEMP_OOR_LO" 16252928 "DTC_KEY_OFF_TIME_ERROR" 16506880 "DTC_VBAT_MISMATCH" 16506881 "DTC_VBAT_VMAX" 16506882 "DTC_VBAT_VMIN" 16506883 "DTC_PACK_FUSE" 15798544 "DTC_LLS1_OOR_HI" 15798545 "DTC_LLS1_OOR_LO" 15798546 "DTC_LLS1_FAULT" 15798816 "DTC_LLS2_OOR_HI" 15798817 "DTC_LLS2_OOR_LO" 15798818 "DTC_LLS2_FAULT" 14479360 "DTC_CFL_HEARTBEAT" 14479361 "DTC_CFL_FAULT" 14479362 "DTC_CFL_FAULT_LATCH" 13635584 "DTC_CONT_A_FAILED_HI" 13635585 "DTC_CONT_A_FAILED_LO" 13635586 "DTC_CONT_B_FAILED_HI" 13635587 "DTC_CONT_B_FAILED_LO" 13635588 "DTC_CONT_C_FAILED_HI" 13635589 "DTC_CONT_C_FAILED_LO" 13635590 "DTC_CONT_D_FAILED_HI" 13635591 "DTC_CONT_D_FAILED_LO" 13635592 "DTC_CONT_E_FAILED_HI" 13635593 "DTC_CONT_E_FAILED_LO" 13635594 "DTC_CONT_F_FAILED_HI" 13635595 "DTC_CONT_F_FAILED_LO" 13635596 "DTC_CONT_G_FAILED_HI" 13635597 "DTC_CONT_G_FAILED_LO" 13635598 "DTC_LSD_A_FAILED_HI" 13635599 "DTC_LSD_A_FAILED_LO" 13635600 "DTC_LSD_B_FAILED_HI" 13635601 "DTC_LSD_B_FAILED_LO" 13635602 "DTC_LSD_C_FAILED_HI" 13635603 "DTC_LSD_C_FAILED_LO" 13635606 "DTC_CONT_PWR_FAILED_HI" 13635607 "DTC_CONT_PWR_FAILED_LO" 13635608 "DTC_LSD_PUMP_FAILED_HI" 13635609 "DTC_LSD_PUMP_FAILED_LO" 13635610 "DTC_CHG_A_ENABLE_FAILED_HI" 13635611 "DTC_CHG_A_ENABLE_FAILED_LO" 13635612 "DTC_CHG_B_ENABLE_FAILED_HI" 13635613 "DTC_CHG_B_ENABLE_FAILED_LO" 13635614 "DTC_SW14V_PWR_FAILED_HI" 13635615 "DTC_SW14V_PWR_FAILED_LO" 13635620 "DTC_HSD_A_FAILED_HI" 13635621 "DTC_HSD_A_FAILED_LO" 13635622 "DTC_HSD_B_FAILED_HI" 13635623 "DTC_HSD_B_FAILED_LO" 13692968 "DTC_CONT_HPWR_FAILED_HI" 13692969 "DTC_CONT_HPWR_FAILED_LO" 13692970 "DTC_CONT_HPWR_OOR_HI" 13692971 "DTC_CONT_HPWR_OOR_LO" 13635616 "DTC_5V_PWR_OOR_HI" 13635617 "DTC_5V_PWR_OOR_LO" 14606336 "DTC_NVM_WRITE_TO" 14606337 "DTC_NVM_READ_TO" 14614528 "DTC_SPI_DIG_POT_FAULT" ;
VAL_ 1120 bcm_dtc_014 0 " - " 11276288 "DTC_VEPO" 11276289 "DTC_HSC_MISSING" 11460608 "DTC_NVM_SOC" 11460609 "DTC_NVM_KOT" 11460610 "DTC_NVM_DTC" 11460611 "DTC_NVM_SOC_CORRECTION" 11460612 "DTC_NVM_APP_SCRATCHPAD" 11517962 "DTC_LOOPTIME_TASK_A" 11517963 "DTC_LOOPTIME_TASK_B" 11517964 "DTC_LOOPTIME_TASK_C" 11517965 "DTC_LOOPTIME_TASK_D" 11517966 "DTC_LOOPTIME_TASK_E" 11517967 "DTC_LOOPTIME_TASK_F" 11323904 "DTC_INTERLOCK_A_FAILED_LOW" 11323905 "DTC_INTERLOCK_A_FAILED_HIGH" 11324160 "DTC_INTERLOCK_B_FAILED_LOW" 11324161 "DTC_INTERLOCK_B_FAILED_HIGH" 15728640 "DTC_EPO" 16498688 "DTC_BRUSA_MISSING" 16498689 "DTC_BRUSA_IDC" 16498690 "DTC_BRUSA_REQ_VS_CMD" 16433152 "DTC_AKERWADE_MISSING" 16433153 "DTC_AKERWADE_IDC" 16433154 "DTC_AKERWADE_REQ_VS_CMD" 16564224 "DTC_CHGLEAR_MISSING" 16564225 "DTC_CHGLEAR_IDC" 16564226 "DTC_CHGLEAR_REQ_VS_CMD" 16522240 "DTC_CSM_MISSING" 16522752 "DTC_CSM_VBAT" 16522753 "DTC_CSM_VPOS" 16522754 "DTC_CSM_VNEG" 16522755 "DTC_CSM_CPOS" 16522756 "DTC_CSM_CNEG" 16522757 "DTC_CSM_APOS" 16522758 "DTC_CSM_ANEG" 16522759 "DTC_CSM_FUSE_HI" 16522760 "DTC_CSM_FUSE_LO" 16521728 "DTC_CSM_ASIC" 16521729 "DTC_CSM_AILO" 16521730 "DTC_CSM_AIHI" 16520957 "DTC_LEAKAGE_DETECT_FAULT" 16522444 "DTC_REALTIMECLOCK_FAULT" 16520945 "DTC_CSM_LEAK_FAIL_CALC" 16520946 "DTC_CSM_LEAK_FAIL_HW" 16520947 "DTC_CSM_LEAK_EXT_SHORT" 16520948 "DTC_CSM_LEAK_MID_PACK_SHORT" 16520949 "DTC_CSM_LEAK_ERROR" 16520950 "DTC_CSM_LEAK_UNKNOWN" 16523008 "DTC_CSM_VER_MISMATCH" 16523009 "DTC_CSM_DTC_SET" 16523010 "DTC_CSM_CAL_FAULT" 16560128 "DTC_IBAT_MISMATCH" 16576512 "DTC_DIS_MAX_I2T" 16576513 "DTC_CHG_MAX_I2T" 16576768 "DTC_DIS_WARNING_I2T" 16576769 "DTC_CHG_WARNING_I2T" 11296784 "DTC_SAEJ1772_PROX_DECT_OOR_HI" 11296785 "DTC_SAEJ1772_PROX_DECT_OOR_LO" 11296800 "DTC_SAEJ1772_PILOT_PWM_OOR_HI" 11296801 "DTC_SAEJ1772_PILOT_PWM_OOR_LO" 11296802 "DTC_SAEJ1772_PILOT_PWM_DIG_COMM" 11296803 "DTC_SAEJ1772_PILOT_PWM_IR_ERR" 16175360 "DTC_FGD1_NO_SENSOR" 16175361 "DTC_FGD1_OOR_HI" 16175362 "DTC_FGD1_OOR_LO" 16175363 "DTC_FGD1_FAULT" 16175616 "DTC_FGD2_NO_SENSOR" 16175617 "DTC_FGD2_OOR_HI" 16175618 "DTC_FGD2_OOR_LO" 16175619 "DTC_FGD2_FAULT" 16171008 "DTC_CONT_OPEN" 16171009 "DTC_CONT_CLOSE" 16171010 "DTC_CONT_OPEN_CURRENT" 16171264 "DTC_CONT_CLOSE_ON_RESET" 16171265 "DTC_CONT_CLOSE_SIG_FAILED" 16171520 "DTC_PRECHARGE_TIMEOUT" 16171777 "DTC_CONT_MPOS_WELD_AT_SU" 16171778 "DTC_CONT_MNEG_WELD_AT_SU" 16171780 "DTC_CONT_CPOS_WELD_AT_SU" 16171781 "DTC_CONT_CNEG_WELD_AT_SU" 16171782 "DTC_CONT_ANEG_WELD_AT_SU" 16171783 "DTC_CONT_APOS_WELD_AT_SU" 16172033 "DTC_CONT_MPOS_WELD_AT_SD" 16172034 "DTC_CONT_MNEG_WELD_AT_SD" 16172036 "DTC_CONT_CPOS_WELD_AT_SD" 16172037 "DTC_CONT_CNEG_WELD_AT_SD" 16172038 "DTC_CONT_ANEG_WELD_AT_SD" 16172039 "DTC_CONT_APOS_WELD_AT_SD" 16172289 "DTC_CONT_MPOS_OPEN" 16172290 "DTC_CONT_MNEG_OPEN" 16172291 "DTC_CONT_MPRE_OPEN" 16172292 "DTC_CONT_CPOS_OPEN" 16172293 "DTC_CONT_CNEG_OPEN" 16172294 "DTC_CONT_APOS_OPEN" 16172295 "DTC_CONT_ANEG_OPEN" 16172545 "DTC_CONT_MPOS_VDIF" 16172546 "DTC_CONT_MNEG_VDIF" 16172548 "DTC_CONT_CPOS_VDIF" 16172549 "DTC_CONT_CNEG_VDIF" 16172550 "DTC_CONT_APOS_VDIF" 16172551 "DTC_CONT_ANEG_VDIF" 16174848 "DTC_HVIL" 16174849 "DTC_LVBAT_LO" 16174850 "DTC_LVBAT_HI" 16174851 "DTC_LVBAT_ERR" 16523520 "DTC_LEMLO_OOR_HI" 16523521 "DTC_LEMLO_OOR_LO" 16523522 "DTC_LEMLO_FAULT" 16523776 "DTC_LEMHI_OOR_HI" 16523777 "DTC_LEMHI_OOR_LO" 16523778 "DTC_LEMHI_FAULT" 16496320 "DTC_MBB_TOO_FEW" 16496321 "DTC_MBB_TOO_MANY" 16496352 "DTC_CELL_VMAX_ERR" 16496353 "DTC_CELL_VMIN_ERR" 16496354 "DTC_CELL_VMAX" 16496362 "DTC_CELL_VMAX_SEVERE" 16496355 "DTC_CELL_VMIN" 16496363 "DTC_CELL_VMIN_SEVERE" 16496356 "DTC_MOD_VOLTAGE_COMPARE" 16496336 "DTC_CELL_T_ERR" 16496337 "DTC_CELL_TMAX1" 16496338 "DTC_CELL_TMAX2" 16496339 "DTC_CELL_TMIN" 16497665 "DTC_MBB_01_MISSING" 16497666 "DTC_MBB_02_MISSING" 16497667 "DTC_MBB_03_MISSING" 16497668 "DTC_MBB_04_MISSING" 16497669 "DTC_MBB_05_MISSING" 16497670 "DTC_MBB_06_MISSING" 16497671 "DTC_MBB_07_MISSING" 16497672 "DTC_MBB_08_MISSING" 16497673 "DTC_MBB_09_MISSING" 16497680 "DTC_MBB_10_MISSING" 16497681 "DTC_MBB_11_MISSING" 16497682 "DTC_MBB_12_MISSING" 16497683 "DTC_MBB_13_MISSING" 16497684 "DTC_MBB_14_MISSING" 16497685 "DTC_MBB_15_MISSING" 16497686 "DTC_MBB_16_MISSING" 16497687 "DTC_MBB_17_MISSING" 16497688 "DTC_MBB_18_MISSING" 16497689 "DTC_MBB_19_MISSING" 16497696 "DTC_MBB_20_MISSING" 16497697 "DTC_MBB_21_MISSING" 16497698 "DTC_MBB_22_MISSING" 16497699 "DTC_MBB_23_MISSING" 16497700 "DTC_MBB_24_MISSING" 16498177 "DTC_MBB_01_VFAULT" 16498178 "DTC_MBB_02_VFAULT" 16498179 "DTC_MBB_03_VFAULT" 16498180 "DTC_MBB_04_VFAULT" 16498181 "DTC_MBB_05_VFAULT" 16498182 "DTC_MBB_06_VFAULT" 16498183 "DTC_MBB_07_VFAULT" 16498184 "DTC_MBB_08_VFAULT" 16498185 "DTC_MBB_09_VFAULT" 16498192 "DTC_MBB_10_VFAULT" 16498193 "DTC_MBB_11_VFAULT" 16498194 "DTC_MBB_12_VFAULT" 16498195 "DTC_MBB_13_VFAULT" 16498196 "DTC_MBB_14_VFAULT" 16498197 "DTC_MBB_15_VFAULT" 16498198 "DTC_MBB_16_VFAULT" 16498199 "DTC_MBB_17_VFAULT" 16498200 "DTC_MBB_18_VFAULT" 16498201 "DTC_MBB_19_VFAULT" 16498208 "DTC_MBB_20_VFAULT" 16498209 "DTC_MBB_21_VFAULT" 16498210 "DTC_MBB_22_VFAULT" 16498211 "DTC_MBB_23_VFAULT" 16498212 "DTC_MBB_24_VFAULT" 16497921 "DTC_MBB_01_TFAULT" 16497922 "DTC_MBB_02_TFAULT" 16497923 "DTC_MBB_03_TFAULT" 16497924 "DTC_MBB_04_TFAULT" 16497925 "DTC_MBB_05_TFAULT" 16497926 "DTC_MBB_06_TFAULT" 16497927 "DTC_MBB_07_TFAULT" 16497928 "DTC_MBB_08_TFAULT" 16497929 "DTC_MBB_09_TFAULT" 16497936 "DTC_MBB_10_TFAULT" 16497937 "DTC_MBB_11_TFAULT" 16497938 "DTC_MBB_12_TFAULT" 16497939 "DTC_MBB_13_TFAULT" 16497940 "DTC_MBB_14_TFAULT" 16497941 "DTC_MBB_15_TFAULT" 16497942 "DTC_MBB_16_TFAULT" 16497943 "DTC_MBB_17_TFAULT" 16497944 "DTC_MBB_18_TFAULT" 16497945 "DTC_MBB_19_TFAULT" 16497952 "DTC_MBB_20_TFAULT" 16497953 "DTC_MBB_21_TFAULT" 16497954 "DTC_MBB_22_TFAULT" 16497955 "DTC_MBB_23_TFAULT" 16497956 "DTC_MBB_24_TFAULT" 15785984 "DTC_PRECHARGE_ENERGY" 15785985 "DTC_PRT_FAILED" 15785986 "DTC_PRT_OVERTEMP" 15785987 "DTC_PRT_PROHIBIT" 16556032 "DTC_COOLANT_TEMP_OOR_HI" 16556033 "DTC_COOLANT_TEMP_OOR_LO" 16252928 "DTC_KEY_OFF_TIME_ERROR" 16506880 "DTC_VBAT_MISMATCH" 16506881 "DTC_VBAT_VMAX" 16506882 "DTC_VBAT_VMIN" 16506883 "DTC_PACK_FUSE" 15798544 "DTC_LLS1_OOR_HI" 15798545 "DTC_LLS1_OOR_LO" 15798546 "DTC_LLS1_FAULT" 15798816 "DTC_LLS2_OOR_HI" 15798817 "DTC_LLS2_OOR_LO" 15798818 "DTC_LLS2_FAULT" 14479360 "DTC_CFL_HEARTBEAT" 14479361 "DTC_CFL_FAULT" 14479362 "DTC_CFL_FAULT_LATCH" 13635584 "DTC_CONT_A_FAILED_HI" 13635585 "DTC_CONT_A_FAILED_LO" 13635586 "DTC_CONT_B_FAILED_HI" 13635587 "DTC_CONT_B_FAILED_LO" 13635588 "DTC_CONT_C_FAILED_HI" 13635589 "DTC_CONT_C_FAILED_LO" 13635590 "DTC_CONT_D_FAILED_HI" 13635591 "DTC_CONT_D_FAILED_LO" 13635592 "DTC_CONT_E_FAILED_HI" 13635593 "DTC_CONT_E_FAILED_LO" 13635594 "DTC_CONT_F_FAILED_HI" 13635595 "DTC_CONT_F_FAILED_LO" 13635596 "DTC_CONT_G_FAILED_HI" 13635597 "DTC_CONT_G_FAILED_LO" 13635598 "DTC_LSD_A_FAILED_HI" 13635599 "DTC_LSD_A_FAILED_LO" 13635600 "DTC_LSD_B_FAILED_HI" 13635601 "DTC_LSD_B_FAILED_LO" 13635602 "DTC_LSD_C_FAILED_HI" 13635603 "DTC_LSD_C_FAILED_LO" 13635606 "DTC_CONT_PWR_FAILED_HI" 13635607 "DTC_CONT_PWR_FAILED_LO" 13635608 "DTC_LSD_PUMP_FAILED_HI" 13635609 "DTC_LSD_PUMP_FAILED_LO" 13635610 "DTC_CHG_A_ENABLE_FAILED_HI" 13635611 "DTC_CHG_A_ENABLE_FAILED_LO" 13635612 "DTC_CHG_B_ENABLE_FAILED_HI" 13635613 "DTC_CHG_B_ENABLE_FAILED_LO" 13635614 "DTC_SW14V_PWR_FAILED_HI" 13635615 "DTC_SW14V_PWR_FAILED_LO" 13635620 "DTC_HSD_A_FAILED_HI" 13635621 "DTC_HSD_A_FAILED_LO" 13635622 "DTC_HSD_B_FAILED_HI" 13635623 "DTC_HSD_B_FAILED_LO" 13692968 "DTC_CONT_HPWR_FAILED_HI" 13692969 "DTC_CONT_HPWR_FAILED_LO" 13692970 "DTC_CONT_HPWR_OOR_HI" 13692971 "DTC_CONT_HPWR_OOR_LO" 13635616 "DTC_5V_PWR_OOR_HI" 13635617 "DTC_5V_PWR_OOR_LO" 14606336 "DTC_NVM_WRITE_TO" 14606337 "DTC_NVM_READ_TO" 14614528 "DTC_SPI_DIG_POT_FAULT" ;
VAL_ 1120 bcm_dtc_015 0 " - " 11276288 "DTC_VEPO" 11276289 "DTC_HSC_MISSING" 11460608 "DTC_NVM_SOC" 11460609 "DTC_NVM_KOT" 11460610 "DTC_NVM_DTC" 11460611 "DTC_NVM_SOC_CORRECTION" 11460612 "DTC_NVM_APP_SCRATCHPAD" 11517962 "DTC_LOOPTIME_TASK_A" 11517963 "DTC_LOOPTIME_TASK_B" 11517964 "DTC_LOOPTIME_TASK_C" 11517965 "DTC_LOOPTIME_TASK_D" 11517966 "DTC_LOOPTIME_TASK_E" 11517967 "DTC_LOOPTIME_TASK_F" 11323904 "DTC_INTERLOCK_A_FAILED_LOW" 11323905 "DTC_INTERLOCK_A_FAILED_HIGH" 11324160 "DTC_INTERLOCK_B_FAILED_LOW" 11324161 "DTC_INTERLOCK_B_FAILED_HIGH" 15728640 "DTC_EPO" 16498688 "DTC_BRUSA_MISSING" 16498689 "DTC_BRUSA_IDC" 16498690 "DTC_BRUSA_REQ_VS_CMD" 16433152 "DTC_AKERWADE_MISSING" 16433153 "DTC_AKERWADE_IDC" 16433154 "DTC_AKERWADE_REQ_VS_CMD" 16564224 "DTC_CHGLEAR_MISSING" 16564225 "DTC_CHGLEAR_IDC" 16564226 "DTC_CHGLEAR_REQ_VS_CMD" 16522240 "DTC_CSM_MISSING" 16522752 "DTC_CSM_VBAT" 16522753 "DTC_CSM_VPOS" 16522754 "DTC_CSM_VNEG" 16522755 "DTC_CSM_CPOS" 16522756 "DTC_CSM_CNEG" 16522757 "DTC_CSM_APOS" 16522758 "DTC_CSM_ANEG" 16522759 "DTC_CSM_FUSE_HI" 16522760 "DTC_CSM_FUSE_LO" 16521728 "DTC_CSM_ASIC" 16521729 "DTC_CSM_AILO" 16521730 "DTC_CSM_AIHI" 16520957 "DTC_LEAKAGE_DETECT_FAULT" 16522444 "DTC_REALTIMECLOCK_FAULT" 16520945 "DTC_CSM_LEAK_FAIL_CALC" 16520946 "DTC_CSM_LEAK_FAIL_HW" 16520947 "DTC_CSM_LEAK_EXT_SHORT" 16520948 "DTC_CSM_LEAK_MID_PACK_SHORT" 16520949 "DTC_CSM_LEAK_ERROR" 16520950 "DTC_CSM_LEAK_UNKNOWN" 16523008 "DTC_CSM_VER_MISMATCH" 16523009 "DTC_CSM_DTC_SET" 16523010 "DTC_CSM_CAL_FAULT" 16560128 "DTC_IBAT_MISMATCH" 16576512 "DTC_DIS_MAX_I2T" 16576513 "DTC_CHG_MAX_I2T" 16576768 "DTC_DIS_WARNING_I2T" 16576769 "DTC_CHG_WARNING_I2T" 11296784 "DTC_SAEJ1772_PROX_DECT_OOR_HI" 11296785 "DTC_SAEJ1772_PROX_DECT_OOR_LO" 11296800 "DTC_SAEJ1772_PILOT_PWM_OOR_HI" 11296801 "DTC_SAEJ1772_PILOT_PWM_OOR_LO" 11296802 "DTC_SAEJ1772_PILOT_PWM_DIG_COMM" 11296803 "DTC_SAEJ1772_PILOT_PWM_IR_ERR" 16175360 "DTC_FGD1_NO_SENSOR" 16175361 "DTC_FGD1_OOR_HI" 16175362 "DTC_FGD1_OOR_LO" 16175363 "DTC_FGD1_FAULT" 16175616 "DTC_FGD2_NO_SENSOR" 16175617 "DTC_FGD2_OOR_HI" 16175618 "DTC_FGD2_OOR_LO" 16175619 "DTC_FGD2_FAULT" 16171008 "DTC_CONT_OPEN" 16171009 "DTC_CONT_CLOSE" 16171010 "DTC_CONT_OPEN_CURRENT" 16171264 "DTC_CONT_CLOSE_ON_RESET" 16171265 "DTC_CONT_CLOSE_SIG_FAILED" 16171520 "DTC_PRECHARGE_TIMEOUT" 16171777 "DTC_CONT_MPOS_WELD_AT_SU" 16171778 "DTC_CONT_MNEG_WELD_AT_SU" 16171780 "DTC_CONT_CPOS_WELD_AT_SU" 16171781 "DTC_CONT_CNEG_WELD_AT_SU" 16171782 "DTC_CONT_ANEG_WELD_AT_SU" 16171783 "DTC_CONT_APOS_WELD_AT_SU" 16172033 "DTC_CONT_MPOS_WELD_AT_SD" 16172034 "DTC_CONT_MNEG_WELD_AT_SD" 16172036 "DTC_CONT_CPOS_WELD_AT_SD" 16172037 "DTC_CONT_CNEG_WELD_AT_SD" 16172038 "DTC_CONT_ANEG_WELD_AT_SD" 16172039 "DTC_CONT_APOS_WELD_AT_SD" 16172289 "DTC_CONT_MPOS_OPEN" 16172290 "DTC_CONT_MNEG_OPEN" 16172291 "DTC_CONT_MPRE_OPEN" 16172292 "DTC_CONT_CPOS_OPEN" 16172293 "DTC_CONT_CNEG_OPEN" 16172294 "DTC_CONT_APOS_OPEN" 16172295 "DTC_CONT_ANEG_OPEN" 16172545 "DTC_CONT_MPOS_VDIF" 16172546 "DTC_CONT_MNEG_VDIF" 16172548 "DTC_CONT_CPOS_VDIF" 16172549 "DTC_CONT_CNEG_VDIF" 16172550 "DTC_CONT_APOS_VDIF" 16172551 "DTC_CONT_ANEG_VDIF" 16174848 "DTC_HVIL" 16174849 "DTC_LVBAT_LO" 16174850 "DTC_LVBAT_HI" 16174851 "DTC_LVBAT_ERR" 16523520 "DTC_LEMLO_OOR_HI" 16523521 "DTC_LEMLO_OOR_LO" 16523522 "DTC_LEMLO_FAULT" 16523776 "DTC_LEMHI_OOR_HI" 16523777 "DTC_LEMHI_OOR_LO" 16523778 "DTC_LEMHI_FAULT" 16496320 "DTC_MBB_TOO_FEW" 16496321 "DTC_MBB_TOO_MANY" 16496352 "DTC_CELL_VMAX_ERR" 16496353 "DTC_CELL_VMIN_ERR" 16496354 "DTC_CELL_VMAX" 16496362 "DTC_CELL_VMAX_SEVERE" 16496355 "DTC_CELL_VMIN" 16496363 "DTC_CELL_VMIN_SEVERE" 16496356 "DTC_MOD_VOLTAGE_COMPARE" 16496336 "DTC_CELL_T_ERR" 16496337 "DTC_CELL_TMAX1" 16496338 "DTC_CELL_TMAX2" 16496339 "DTC_CELL_TMIN" 16497665 "DTC_MBB_01_MISSING" 16497666 "DTC_MBB_02_MISSING" 16497667 "DTC_MBB_03_MISSING" 16497668 "DTC_MBB_04_MISSING" 16497669 "DTC_MBB_05_MISSING" 16497670 "DTC_MBB_06_MISSING" 16497671 "DTC_MBB_07_MISSING" 16497672 "DTC_MBB_08_MISSING" 16497673 "DTC_MBB_09_MISSING" 16497680 "DTC_MBB_10_MISSING" 16497681 "DTC_MBB_11_MISSING" 16497682 "DTC_MBB_12_MISSING" 16497683 "DTC_MBB_13_MISSING" 16497684 "DTC_MBB_14_MISSING" 16497685 "DTC_MBB_15_MISSING" 16497686 "DTC_MBB_16_MISSING" 16497687 "DTC_MBB_17_MISSING" 16497688 "DTC_MBB_18_MISSING" 16497689 "DTC_MBB_19_MISSING" 16497696 "DTC_MBB_20_MISSING" 16497697 "DTC_MBB_21_MISSING" 16497698 "DTC_MBB_22_MISSING" 16497699 "DTC_MBB_23_MISSING" 16497700 "DTC_MBB_24_MISSING" 16498177 "DTC_MBB_01_VFAULT" 16498178 "DTC_MBB_02_VFAULT" 16498179 "DTC_MBB_03_VFAULT" 16498180 "DTC_MBB_04_VFAULT" 16498181 "DTC_MBB_05_VFAULT" 16498182 "DTC_MBB_06_VFAULT" 16498183 "DTC_MBB_07_VFAULT" 16498184 "DTC_MBB_08_VFAULT" 16498185 "DTC_MBB_09_VFAULT" 16498192 "DTC_MBB_10_VFAULT" 16498193 "DTC_MBB_11_VFAULT" 16498194 "DTC_MBB_12_VFAULT" 16498195 "DTC_MBB_13_VFAULT" 16498196 "DTC_MBB_14_VFAULT" 16498197 "DTC_MBB_15_VFAULT" 16498198 "DTC_MBB_16_VFAULT" 16498199 "DTC_MBB_17_VFAULT" 16498200 "DTC_MBB_18_VFAULT" 16498201 "DTC_MBB_19_VFAULT" 16498208 "DTC_MBB_20_VFAULT" 16498209 "DTC_MBB_21_VFAULT" 16498210 "DTC_MBB_22_VFAULT" 16498211 "DTC_MBB_23_VFAULT" 16498212 "DTC_MBB_24_VFAULT" 16497921 "DTC_MBB_01_TFAULT" 16497922 "DTC_MBB_02_TFAULT" 16497923 "DTC_MBB_03_TFAULT" 16497924 "DTC_MBB_04_TFAULT" 16497925 "DTC_MBB_05_TFAULT" 16497926 "DTC_MBB_06_TFAULT" 16497927 "DTC_MBB_07_TFAULT" 16497928 "DTC_MBB_08_TFAULT" 16497929 "DTC_MBB_09_TFAULT" 16497936 "DTC_MBB_10_TFAULT" 16497937 "DTC_MBB_11_TFAULT" 16497938 "DTC_MBB_12_TFAULT" 16497939 "DTC_MBB_13_TFAULT" 16497940 "DTC_MBB_14_TFAULT" 16497941 "DTC_MBB_15_TFAULT" 16497942 "DTC_MBB_16_TFAULT" 16497943 "DTC_MBB_17_TFAULT" 16497944 "DTC_MBB_18_TFAULT" 16497945 "DTC_MBB_19_TFAULT" 16497952 "DTC_MBB_20_TFAULT" 16497953 "DTC_MBB_21_TFAULT" 16497954 "DTC_MBB_22_TFAULT" 16497955 "DTC_MBB_23_TFAULT" 16497956 "DTC_MBB_24_TFAULT" 15785984 "DTC_PRECHARGE_ENERGY" 15785985 "DTC_PRT_FAILED" 15785986 "DTC_PRT_OVERTEMP" 15785987 "DTC_PRT_PROHIBIT" 16556032 "DTC_COOLANT_TEMP_OOR_HI" 16556033 "DTC_COOLANT_TEMP_OOR_LO" 16252928 "DTC_KEY_OFF_TIME_ERROR" 16506880 "DTC_VBAT_MISMATCH" 16506881 "DTC_VBAT_VMAX" 16506882 "DTC_VBAT_VMIN" 16506883 "DTC_PACK_FUSE" 15798544 "DTC_LLS1_OOR_HI" 15798545 "DTC_LLS1_OOR_LO" 15798546 "DTC_LLS1_FAULT" 15798816 "DTC_LLS2_OOR_HI" 15798817 "DTC_LLS2_OOR_LO" 15798818 "DTC_LLS2_FAULT" 14479360 "DTC_CFL_HEARTBEAT" 14479361 "DTC_CFL_FAULT" 14479362 "DTC_CFL_FAULT_LATCH" 13635584 "DTC_CONT_A_FAILED_HI" 13635585 "DTC_CONT_A_FAILED_LO" 13635586 "DTC_CONT_B_FAILED_HI" 13635587 "DTC_CONT_B_FAILED_LO" 13635588 "DTC_CONT_C_FAILED_HI" 13635589 "DTC_CONT_C_FAILED_LO" 13635590 "DTC_CONT_D_FAILED_HI" 13635591 "DTC_CONT_D_FAILED_LO" 13635592 "DTC_CONT_E_FAILED_HI" 13635593 "DTC_CONT_E_FAILED_LO" 13635594 "DTC_CONT_F_FAILED_HI" 13635595 "DTC_CONT_F_FAILED_LO" 13635596 "DTC_CONT_G_FAILED_HI" 13635597 "DTC_CONT_G_FAILED_LO" 13635598 "DTC_LSD_A_FAILED_HI" 13635599 "DTC_LSD_A_FAILED_LO" 13635600 "DTC_LSD_B_FAILED_HI" 13635601 "DTC_LSD_B_FAILED_LO" 13635602 "DTC_LSD_C_FAILED_HI" 13635603 "DTC_LSD_C_FAILED_LO" 13635606 "DTC_CONT_PWR_FAILED_HI" 13635607 "DTC_CONT_PWR_FAILED_LO" 13635608 "DTC_LSD_PUMP_FAILED_HI" 13635609 "DTC_LSD_PUMP_FAILED_LO" 13635610 "DTC_CHG_A_ENABLE_FAILED_HI" 13635611 "DTC_CHG_A_ENABLE_FAILED_LO" 13635612 "DTC_CHG_B_ENABLE_FAILED_HI" 13635613 "DTC_CHG_B_ENABLE_FAILED_LO" 13635614 "DTC_SW14V_PWR_FAILED_HI" 13635615 "DTC_SW14V_PWR_FAILED_LO" 13635620 "DTC_HSD_A_FAILED_HI" 13635621 "DTC_HSD_A_FAILED_LO" 13635622 "DTC_HSD_B_FAILED_HI" 13635623 "DTC_HSD_B_FAILED_LO" 13692968 "DTC_CONT_HPWR_FAILED_HI" 13692969 "DTC_CONT_HPWR_FAILED_LO" 13692970 "DTC_CONT_HPWR_OOR_HI" 13692971 "DTC_CONT_HPWR_OOR_LO" 13635616 "DTC_5V_PWR_OOR_HI" 13635617 "DTC_5V_PWR_OOR_LO" 14606336 "DTC_NVM_WRITE_TO" 14606337 "DTC_NVM_READ_TO" 14614528 "DTC_SPI_DIG_POT_FAULT" ;
VAL_ 1120 bcm_dtc_016 0 " - " 11276288 "DTC_VEPO" 11276289 "DTC_HSC_MISSING" 11460608 "DTC_NVM_SOC" 11460609 "DTC_NVM_KOT" 11460610 "DTC_NVM_DTC" 11460611 "DTC_NVM_SOC_CORRECTION" 11460612 "DTC_NVM_APP_SCRATCHPAD" 11517962 "DTC_LOOPTIME_TASK_A" 11517963 "DTC_LOOPTIME_TASK_B" 11517964 "DTC_LOOPTIME_TASK_C" 11517965 "DTC_LOOPTIME_TASK_D" 11517966 "DTC_LOOPTIME_TASK_E" 11517967 "DTC_LOOPTIME_TASK_F" 11323904 "DTC_INTERLOCK_A_FAILED_LOW" 11323905 "DTC_INTERLOCK_A_FAILED_HIGH" 11324160 "DTC_INTERLOCK_B_FAILED_LOW" 11324161 "DTC_INTERLOCK_B_FAILED_HIGH" 15728640 "DTC_EPO" 16498688 "DTC_BRUSA_MISSING" 16498689 "DTC_BRUSA_IDC" 16498690 "DTC_BRUSA_REQ_VS_CMD" 16433152 "DTC_AKERWADE_MISSING" 16433153 "DTC_AKERWADE_IDC" 16433154 "DTC_AKERWADE_REQ_VS_CMD" 16564224 "DTC_CHGLEAR_MISSING" 16564225 "DTC_CHGLEAR_IDC" 16564226 "DTC_CHGLEAR_REQ_VS_CMD" 16522240 "DTC_CSM_MISSING" 16522752 "DTC_CSM_VBAT" 16522753 "DTC_CSM_VPOS" 16522754 "DTC_CSM_VNEG" 16522755 "DTC_CSM_CPOS" 16522756 "DTC_CSM_CNEG" 16522757 "DTC_CSM_APOS" 16522758 "DTC_CSM_ANEG" 16522759 "DTC_CSM_FUSE_HI" 16522760 "DTC_CSM_FUSE_LO" 16521728 "DTC_CSM_ASIC" 16521729 "DTC_CSM_AILO" 16521730 "DTC_CSM_AIHI" 16520957 "DTC_LEAKAGE_DETECT_FAULT" 16522444 "DTC_REALTIMECLOCK_FAULT" 16520945 "DTC_CSM_LEAK_FAIL_CALC" 16520946 "DTC_CSM_LEAK_FAIL_HW" 16520947 "DTC_CSM_LEAK_EXT_SHORT" 16520948 "DTC_CSM_LEAK_MID_PACK_SHORT" 16520949 "DTC_CSM_LEAK_ERROR" 16520950 "DTC_CSM_LEAK_UNKNOWN" 16523008 "DTC_CSM_VER_MISMATCH" 16523009 "DTC_CSM_DTC_SET" 16523010 "DTC_CSM_CAL_FAULT" 16560128 "DTC_IBAT_MISMATCH" 16576512 "DTC_DIS_MAX_I2T" 16576513 "DTC_CHG_MAX_I2T" 16576768 "DTC_DIS_WARNING_I2T" 16576769 "DTC_CHG_WARNING_I2T" 11296784 "DTC_SAEJ1772_PROX_DECT_OOR_HI" 11296785 "DTC_SAEJ1772_PROX_DECT_OOR_LO" 11296800 "DTC_SAEJ1772_PILOT_PWM_OOR_HI" 11296801 "DTC_SAEJ1772_PILOT_PWM_OOR_LO" 11296802 "DTC_SAEJ1772_PILOT_PWM_DIG_COMM" 11296803 "DTC_SAEJ1772_PILOT_PWM_IR_ERR" 16175360 "DTC_FGD1_NO_SENSOR" 16175361 "DTC_FGD1_OOR_HI" 16175362 "DTC_FGD1_OOR_LO" 16175363 "DTC_FGD1_FAULT" 16175616 "DTC_FGD2_NO_SENSOR" 16175617 "DTC_FGD2_OOR_HI" 16175618 "DTC_FGD2_OOR_LO" 16175619 "DTC_FGD2_FAULT" 16171008 "DTC_CONT_OPEN" 16171009 "DTC_CONT_CLOSE" 16171010 "DTC_CONT_OPEN_CURRENT" 16171264 "DTC_CONT_CLOSE_ON_RESET" 16171265 "DTC_CONT_CLOSE_SIG_FAILED" 16171520 "DTC_PRECHARGE_TIMEOUT" 16171777 "DTC_CONT_MPOS_WELD_AT_SU" 16171778 "DTC_CONT_MNEG_WELD_AT_SU" 16171780 "DTC_CONT_CPOS_WELD_AT_SU" 16171781 "DTC_CONT_CNEG_WELD_AT_SU" 16171782 "DTC_CONT_ANEG_WELD_AT_SU" 16171783 "DTC_CONT_APOS_WELD_AT_SU" 16172033 "DTC_CONT_MPOS_WELD_AT_SD" 16172034 "DTC_CONT_MNEG_WELD_AT_SD" 16172036 "DTC_CONT_CPOS_WELD_AT_SD" 16172037 "DTC_CONT_CNEG_WELD_AT_SD" 16172038 "DTC_CONT_ANEG_WELD_AT_SD" 16172039 "DTC_CONT_APOS_WELD_AT_SD" 16172289 "DTC_CONT_MPOS_OPEN" 16172290 "DTC_CONT_MNEG_OPEN" 16172291 "DTC_CONT_MPRE_OPEN" 16172292 "DTC_CONT_CPOS_OPEN" 16172293 "DTC_CONT_CNEG_OPEN" 16172294 "DTC_CONT_APOS_OPEN" 16172295 "DTC_CONT_ANEG_OPEN" 16172545 "DTC_CONT_MPOS_VDIF" 16172546 "DTC_CONT_MNEG_VDIF" 16172548 "DTC_CONT_CPOS_VDIF" 16172549 "DTC_CONT_CNEG_VDIF" 16172550 "DTC_CONT_APOS_VDIF" 16172551 "DTC_CONT_ANEG_VDIF" 16174848 "DTC_HVIL" 16174849 "DTC_LVBAT_LO" 16174850 "DTC_LVBAT_HI" 16174851 "DTC_LVBAT_ERR" 16523520 "DTC_LEMLO_OOR_HI" 16523521 "DTC_LEMLO_OOR_LO" 16523522 "DTC_LEMLO_FAULT" 16523776 "DTC_LEMHI_OOR_HI" 16523777 "DTC_LEMHI_OOR_LO" 16523778 "DTC_LEMHI_FAULT" 16496320 "DTC_MBB_TOO_FEW" 16496321 "DTC_MBB_TOO_MANY" 16496352 "DTC_CELL_VMAX_ERR" 16496353 "DTC_CELL_VMIN_ERR" 16496354 "DTC_CELL_VMAX" 16496362 "DTC_CELL_VMAX_SEVERE" 16496355 "DTC_CELL_VMIN" 16496363 "DTC_CELL_VMIN_SEVERE" 16496356 "DTC_MOD_VOLTAGE_COMPARE" 16496336 "DTC_CELL_T_ERR" 16496337 "DTC_CELL_TMAX1" 16496338 "DTC_CELL_TMAX2" 16496339 "DTC_CELL_TMIN" 16497665 "DTC_MBB_01_MISSING" 16497666 "DTC_MBB_02_MISSING" 16497667 "DTC_MBB_03_MISSING" 16497668 "DTC_MBB_04_MISSING" 16497669 "DTC_MBB_05_MISSING" 16497670 "DTC_MBB_06_MISSING" 16497671 "DTC_MBB_07_MISSING" 16497672 "DTC_MBB_08_MISSING" 16497673 "DTC_MBB_09_MISSING" 16497680 "DTC_MBB_10_MISSING" 16497681 "DTC_MBB_11_MISSING" 16497682 "DTC_MBB_12_MISSING" 16497683 "DTC_MBB_13_MISSING" 16497684 "DTC_MBB_14_MISSING" 16497685 "DTC_MBB_15_MISSING" 16497686 "DTC_MBB_16_MISSING" 16497687 "DTC_MBB_17_MISSING" 16497688 "DTC_MBB_18_MISSING" 16497689 "DTC_MBB_19_MISSING" 16497696 "DTC_MBB_20_MISSING" 16497697 "DTC_MBB_21_MISSING" 16497698 "DTC_MBB_22_MISSING" 16497699 "DTC_MBB_23_MISSING" 16497700 "DTC_MBB_24_MISSING" 16498177 "DTC_MBB_01_VFAULT" 16498178 "DTC_MBB_02_VFAULT" 16498179 "DTC_MBB_03_VFAULT" 16498180 "DTC_MBB_04_VFAULT" 16498181 "DTC_MBB_05_VFAULT" 16498182 "DTC_MBB_06_VFAULT" 16498183 "DTC_MBB_07_VFAULT" 16498184 "DTC_MBB_08_VFAULT" 16498185 "DTC_MBB_09_VFAULT" 16498192 "DTC_MBB_10_VFAULT" 16498193 "DTC_MBB_11_VFAULT" 16498194 "DTC_MBB_12_VFAULT" 16498195 "DTC_MBB_13_VFAULT" 16498196 "DTC_MBB_14_VFAULT" 16498197 "DTC_MBB_15_VFAULT" 16498198 "DTC_MBB_16_VFAULT" 16498199 "DTC_MBB_17_VFAULT" 16498200 "DTC_MBB_18_VFAULT" 16498201 "DTC_MBB_19_VFAULT" 16498208 "DTC_MBB_20_VFAULT" 16498209 "DTC_MBB_21_VFAULT" 16498210 "DTC_MBB_22_VFAULT" 16498211 "DTC_MBB_23_VFAULT" 16498212 "DTC_MBB_24_VFAULT" 16497921 "DTC_MBB_01_TFAULT" 16497922 "DTC_MBB_02_TFAULT" 16497923 "DTC_MBB_03_TFAULT" 16497924 "DTC_MBB_04_TFAULT" 16497925 "DTC_MBB_05_TFAULT" 16497926 "DTC_MBB_06_TFAULT" 16497927 "DTC_MBB_07_TFAULT" 16497928 "DTC_MBB_08_TFAULT" 16497929 "DTC_MBB_09_TFAULT" 16497936 "DTC_MBB_10_TFAULT" 16497937 "DTC_MBB_11_TFAULT" 16497938 "DTC_MBB_12_TFAULT" 16497939 "DTC_MBB_13_TFAULT" 16497940 "DTC_MBB_14_TFAULT" 16497941 "DTC_MBB_15_TFAULT" 16497942 "DTC_MBB_16_TFAULT" 16497943 "DTC_MBB_17_TFAULT" 16497944 "DTC_MBB_18_TFAULT" 16497945 "DTC_MBB_19_TFAULT" 16497952 "DTC_MBB_20_TFAULT" 16497953 "DTC_MBB_21_TFAULT" 16497954 "DTC_MBB_22_TFAULT" 16497955 "DTC_MBB_23_TFAULT" 16497956 "DTC_MBB_24_TFAULT" 15785984 "DTC_PRECHARGE_ENERGY" 15785985 "DTC_PRT_FAILED" 15785986 "DTC_PRT_OVERTEMP" 15785987 "DTC_PRT_PROHIBIT" 16556032 "DTC_COOLANT_TEMP_OOR_HI" 16556033 "DTC_COOLANT_TEMP_OOR_LO" 16252928 "DTC_KEY_OFF_TIME_ERROR" 16506880 "DTC_VBAT_MISMATCH" 16506881 "DTC_VBAT_VMAX" 16506882 "DTC_VBAT_VMIN" 16506883 "DTC_PACK_FUSE" 15798544 "DTC_LLS1_OOR_HI" 15798545 "DTC_LLS1_OOR_LO" 15798546 "DTC_LLS1_FAULT" 15798816 "DTC_LLS2_OOR_HI" 15798817 "DTC_LLS2_OOR_LO" 15798818 "DTC_LLS2_FAULT" 14479360 "DTC_CFL_HEARTBEAT" 14479361 "DTC_CFL_FAULT" 14479362 "DTC_CFL_FAULT_LATCH" 13635584 "DTC_CONT_A_FAILED_HI" 13635585 "DTC_CONT_A_FAILED_LO" 13635586 "DTC_CONT_B_FAILED_HI" 13635587 "DTC_CONT_B_FAILED_LO" 13635588 "DTC_CONT_C_FAILED_HI" 13635589 "DTC_CONT_C_FAILED_LO" 13635590 "DTC_CONT_D_FAILED_HI" 13635591 "DTC_CONT_D_FAILED_LO" 13635592 "DTC_CONT_E_FAILED_HI" 13635593 "DTC_CONT_E_FAILED_LO" 13635594 "DTC_CONT_F_FAILED_HI" 13635595 "DTC_CONT_F_FAILED_LO" 13635596 "DTC_CONT_G_FAILED_HI" 13635597 "DTC_CONT_G_FAILED_LO" 13635598 "DTC_LSD_A_FAILED_HI" 13635599 "DTC_LSD_A_FAILED_LO" 13635600 "DTC_LSD_B_FAILED_HI" 13635601 "DTC_LSD_B_FAILED_LO" 13635602 "DTC_LSD_C_FAILED_HI" 13635603 "DTC_LSD_C_FAILED_LO" 13635606 "DTC_CONT_PWR_FAILED_HI" 13635607 "DTC_CONT_PWR_FAILED_LO" 13635608 "DTC_LSD_PUMP_FAILED_HI" 13635609 "DTC_LSD_PUMP_FAILED_LO" 13635610 "DTC_CHG_A_ENABLE_FAILED_HI" 13635611 "DTC_CHG_A_ENABLE_FAILED_LO" 13635612 "DTC_CHG_B_ENABLE_FAILED_HI" 13635613 "DTC_CHG_B_ENABLE_FAILED_LO" 13635614 "DTC_SW14V_PWR_FAILED_HI" 13635615 "DTC_SW14V_PWR_FAILED_LO" 13635620 "DTC_HSD_A_FAILED_HI" 13635621 "DTC_HSD_A_FAILED_LO" 13635622 "DTC_HSD_B_FAILED_HI" 13635623 "DTC_HSD_B_FAILED_LO" 13692968 "DTC_CONT_HPWR_FAILED_HI" 13692969 "DTC_CONT_HPWR_FAILED_LO" 13692970 "DTC_CONT_HPWR_OOR_HI" 13692971 "DTC_CONT_HPWR_OOR_LO" 13635616 "DTC_5V_PWR_OOR_HI" 13635617 "DTC_5V_PWR_OOR_LO" 14606336 "DTC_NVM_WRITE_TO" 14606337 "DTC_NVM_READ_TO" 14614528 "DTC_SPI_DIG_POT_FAULT" ;
VAL_ 1120 bcm_dtc_017 0 " - " 11276288 "DTC_VEPO" 11276289 "DTC_HSC_MISSING" 11460608 "DTC_NVM_SOC" 11460609 "DTC_NVM_KOT" 11460610 "DTC_NVM_DTC" 11460611 "DTC_NVM_SOC_CORRECTION" 11460612 "DTC_NVM_APP_SCRATCHPAD" 11517962 "DTC_LOOPTIME_TASK_A" 11517963 "DTC_LOOPTIME_TASK_B" 11517964 "DTC_LOOPTIME_TASK_C" 11517965 "DTC_LOOPTIME_TASK_D" 11517966 "DTC_LOOPTIME_TASK_E" 11517967 "DTC_LOOPTIME_TASK_F" 11323904 "DTC_INTERLOCK_A_FAILED_LOW" 11323905 "DTC_INTERLOCK_A_FAILED_HIGH" 11324160 "DTC_INTERLOCK_B_FAILED_LOW" 11324161 "DTC_INTERLOCK_B_FAILED_HIGH" 15728640 "DTC_EPO" 16498688 "DTC_BRUSA_MISSING" 16498689 "DTC_BRUSA_IDC" 16498690 "DTC_BRUSA_REQ_VS_CMD" 16433152 "DTC_AKERWADE_MISSING" 16433153 "DTC_AKERWADE_IDC" 16433154 "DTC_AKERWADE_REQ_VS_CMD" 16564224 "DTC_CHGLEAR_MISSING" 16564225 "DTC_CHGLEAR_IDC" 16564226 "DTC_CHGLEAR_REQ_VS_CMD" 16522240 "DTC_CSM_MISSING" 16522752 "DTC_CSM_VBAT" 16522753 "DTC_CSM_VPOS" 16522754 "DTC_CSM_VNEG" 16522755 "DTC_CSM_CPOS" 16522756 "DTC_CSM_CNEG" 16522757 "DTC_CSM_APOS" 16522758 "DTC_CSM_ANEG" 16522759 "DTC_CSM_FUSE_HI" 16522760 "DTC_CSM_FUSE_LO" 16521728 "DTC_CSM_ASIC" 16521729 "DTC_CSM_AILO" 16521730 "DTC_CSM_AIHI" 16520957 "DTC_LEAKAGE_DETECT_FAULT" 16522444 "DTC_REALTIMECLOCK_FAULT" 16520945 "DTC_CSM_LEAK_FAIL_CALC" 16520946 "DTC_CSM_LEAK_FAIL_HW" 16520947 "DTC_CSM_LEAK_EXT_SHORT" 16520948 "DTC_CSM_LEAK_MID_PACK_SHORT" 16520949 "DTC_CSM_LEAK_ERROR" 16520950 "DTC_CSM_LEAK_UNKNOWN" 16523008 "DTC_CSM_VER_MISMATCH" 16523009 "DTC_CSM_DTC_SET" 16523010 "DTC_CSM_CAL_FAULT" 16560128 "DTC_IBAT_MISMATCH" 16576512 "DTC_DIS_MAX_I2T" 16576513 "DTC_CHG_MAX_I2T" 16576768 "DTC_DIS_WARNING_I2T" 16576769 "DTC_CHG_WARNING_I2T" 11296784 "DTC_SAEJ1772_PROX_DECT_OOR_HI" 11296785 "DTC_SAEJ1772_PROX_DECT_OOR_LO" 11296800 "DTC_SAEJ1772_PILOT_PWM_OOR_HI" 11296801 "DTC_SAEJ1772_PILOT_PWM_OOR_LO" 11296802 "DTC_SAEJ1772_PILOT_PWM_DIG_COMM" 11296803 "DTC_SAEJ1772_PILOT_PWM_IR_ERR" 16175360 "DTC_FGD1_NO_SENSOR" 16175361 "DTC_FGD1_OOR_HI" 16175362 "DTC_FGD1_OOR_LO" 16175363 "DTC_FGD1_FAULT" 16175616 "DTC_FGD2_NO_SENSOR" 16175617 "DTC_FGD2_OOR_HI" 16175618 "DTC_FGD2_OOR_LO" 16175619 "DTC_FGD2_FAULT" 16171008 "DTC_CONT_OPEN" 16171009 "DTC_CONT_CLOSE" 16171010 "DTC_CONT_OPEN_CURRENT" 16171264 "DTC_CONT_CLOSE_ON_RESET" 16171265 "DTC_CONT_CLOSE_SIG_FAILED" 16171520 "DTC_PRECHARGE_TIMEOUT" 16171777 "DTC_CONT_MPOS_WELD_AT_SU" 16171778 "DTC_CONT_MNEG_WELD_AT_SU" 16171780 "DTC_CONT_CPOS_WELD_AT_SU" 16171781 "DTC_CONT_CNEG_WELD_AT_SU" 16171782 "DTC_CONT_ANEG_WELD_AT_SU" 16171783 "DTC_CONT_APOS_WELD_AT_SU" 16172033 "DTC_CONT_MPOS_WELD_AT_SD" 16172034 "DTC_CONT_MNEG_WELD_AT_SD" 16172036 "DTC_CONT_CPOS_WELD_AT_SD" 16172037 "DTC_CONT_CNEG_WELD_AT_SD" 16172038 "DTC_CONT_ANEG_WELD_AT_SD" 16172039 "DTC_CONT_APOS_WELD_AT_SD" 16172289 "DTC_CONT_MPOS_OPEN" 16172290 "DTC_CONT_MNEG_OPEN" 16172291 "DTC_CONT_MPRE_OPEN" 16172292 "DTC_CONT_CPOS_OPEN" 16172293 "DTC_CONT_CNEG_OPEN" 16172294 "DTC_CONT_APOS_OPEN" 16172295 "DTC_CONT_ANEG_OPEN" 16172545 "DTC_CONT_MPOS_VDIF" 16172546 "DTC_CONT_MNEG_VDIF" 16172548 "DTC_CONT_CPOS_VDIF" 16172549 "DTC_CONT_CNEG_VDIF" 16172550 "DTC_CONT_APOS_VDIF" 16172551 "DTC_CONT_ANEG_VDIF" 16174848 "DTC_HVIL" 16174849 "DTC_LVBAT_LO" 16174850 "DTC_LVBAT_HI" 16174851 "DTC_LVBAT_ERR" 16523520 "DTC_LEMLO_OOR_HI" 16523521 "DTC_LEMLO_OOR_LO" 16523522 "DTC_LEMLO_FAULT" 16523776 "DTC_LEMHI_OOR_HI" 16523777 "DTC_LEMHI_OOR_LO" 16523778 "DTC_LEMHI_FAULT" 16496320 "DTC_MBB_TOO_FEW" 16496321 "DTC_MBB_TOO_MANY" 16496352 "DTC_CELL_VMAX_ERR" 16496353 "DTC_CELL_VMIN_ERR" 16496354 "DTC_CELL_VMAX" 16496362 "DTC_CELL_VMAX_SEVERE" 16496355 "DTC_CELL_VMIN" 16496363 "DTC_CELL_VMIN_SEVERE" 16496356 "DTC_MOD_VOLTAGE_COMPARE" 16496336 "DTC_CELL_T_ERR" 16496337 "DTC_CELL_TMAX1" 16496338 "DTC_CELL_TMAX2" 16496339 "DTC_CELL_TMIN" 16497665 "DTC_MBB_01_MISSING" 16497666 "DTC_MBB_02_MISSING" 16497667 "DTC_MBB_03_MISSING" 16497668 "DTC_MBB_04_MISSING" 16497669 "DTC_MBB_05_MISSING" 16497670 "DTC_MBB_06_MISSING" 16497671 "DTC_MBB_07_MISSING" 16497672 "DTC_MBB_08_MISSING" 16497673 "DTC_MBB_09_MISSING" 16497680 "DTC_MBB_10_MISSING" 16497681 "DTC_MBB_11_MISSING" 16497682 "DTC_MBB_12_MISSING" 16497683 "DTC_MBB_13_MISSING" 16497684 "DTC_MBB_14_MISSING" 16497685 "DTC_MBB_15_MISSING" 16497686 "DTC_MBB_16_MISSING" 16497687 "DTC_MBB_17_MISSING" 16497688 "DTC_MBB_18_MISSING" 16497689 "DTC_MBB_19_MISSING" 16497696 "DTC_MBB_20_MISSING" 16497697 "DTC_MBB_21_MISSING" 16497698 "DTC_MBB_22_MISSING" 16497699 "DTC_MBB_23_MISSING" 16497700 "DTC_MBB_24_MISSING" 16498177 "DTC_MBB_01_VFAULT" 16498178 "DTC_MBB_02_VFAULT" 16498179 "DTC_MBB_03_VFAULT" 16498180 "DTC_MBB_04_VFAULT" 16498181 "DTC_MBB_05_VFAULT" 16498182 "DTC_MBB_06_VFAULT" 16498183 "DTC_MBB_07_VFAULT" 16498184 "DTC_MBB_08_VFAULT" 16498185 "DTC_MBB_09_VFAULT" 16498192 "DTC_MBB_10_VFAULT" 16498193 "DTC_MBB_11_VFAULT" 16498194 "DTC_MBB_12_VFAULT" 16498195 "DTC_MBB_13_VFAULT" 16498196 "DTC_MBB_14_VFAULT" 16498197 "DTC_MBB_15_VFAULT" 16498198 "DTC_MBB_16_VFAULT" 16498199 "DTC_MBB_17_VFAULT" 16498200 "DTC_MBB_18_VFAULT" 16498201 "DTC_MBB_19_VFAULT" 16498208 "DTC_MBB_20_VFAULT" 16498209 "DTC_MBB_21_VFAULT" 16498210 "DTC_MBB_22_VFAULT" 16498211 "DTC_MBB_23_VFAULT" 16498212 "DTC_MBB_24_VFAULT" 16497921 "DTC_MBB_01_TFAULT" 16497922 "DTC_MBB_02_TFAULT" 16497923 "DTC_MBB_03_TFAULT" 16497924 "DTC_MBB_04_TFAULT" 16497925 "DTC_MBB_05_TFAULT" 16497926 "DTC_MBB_06_TFAULT" 16497927 "DTC_MBB_07_TFAULT" 16497928 "DTC_MBB_08_TFAULT" 16497929 "DTC_MBB_09_TFAULT" 16497936 "DTC_MBB_10_TFAULT" 16497937 "DTC_MBB_11_TFAULT" 16497938 "DTC_MBB_12_TFAULT" 16497939 "DTC_MBB_13_TFAULT" 16497940 "DTC_MBB_14_TFAULT" 16497941 "DTC_MBB_15_TFAULT" 16497942 "DTC_MBB_16_TFAULT" 16497943 "DTC_MBB_17_TFAULT" 16497944 "DTC_MBB_18_TFAULT" 16497945 "DTC_MBB_19_TFAULT" 16497952 "DTC_MBB_20_TFAULT" 16497953 "DTC_MBB_21_TFAULT" 16497954 "DTC_MBB_22_TFAULT" 16497955 "DTC_MBB_23_TFAULT" 16497956 "DTC_MBB_24_TFAULT" 15785984 "DTC_PRECHARGE_ENERGY" 15785985 "DTC_PRT_FAILED" 15785986 "DTC_PRT_OVERTEMP" 15785987 "DTC_PRT_PROHIBIT" 16556032 "DTC_COOLANT_TEMP_OOR_HI" 16556033 "DTC_COOLANT_TEMP_OOR_LO" 16252928 "DTC_KEY_OFF_TIME_ERROR" 16506880 "DTC_VBAT_MISMATCH" 16506881 "DTC_VBAT_VMAX" 16506882 "DTC_VBAT_VMIN" 16506883 "DTC_PACK_FUSE" 15798544 "DTC_LLS1_OOR_HI" 15798545 "DTC_LLS1_OOR_LO" 15798546 "DTC_LLS1_FAULT" 15798816 "DTC_LLS2_OOR_HI" 15798817 "DTC_LLS2_OOR_LO" 15798818 "DTC_LLS2_FAULT" 14479360 "DTC_CFL_HEARTBEAT" 14479361 "DTC_CFL_FAULT" 14479362 "DTC_CFL_FAULT_LATCH" 13635584 "DTC_CONT_A_FAILED_HI" 13635585 "DTC_CONT_A_FAILED_LO" 13635586 "DTC_CONT_B_FAILED_HI" 13635587 "DTC_CONT_B_FAILED_LO" 13635588 "DTC_CONT_C_FAILED_HI" 13635589 "DTC_CONT_C_FAILED_LO" 13635590 "DTC_CONT_D_FAILED_HI" 13635591 "DTC_CONT_D_FAILED_LO" 13635592 "DTC_CONT_E_FAILED_HI" 13635593 "DTC_CONT_E_FAILED_LO" 13635594 "DTC_CONT_F_FAILED_HI" 13635595 "DTC_CONT_F_FAILED_LO" 13635596 "DTC_CONT_G_FAILED_HI" 13635597 "DTC_CONT_G_FAILED_LO" 13635598 "DTC_LSD_A_FAILED_HI" 13635599 "DTC_LSD_A_FAILED_LO" 13635600 "DTC_LSD_B_FAILED_HI" 13635601 "DTC_LSD_B_FAILED_LO" 13635602 "DTC_LSD_C_FAILED_HI" 13635603 "DTC_LSD_C_FAILED_LO" 13635606 "DTC_CONT_PWR_FAILED_HI" 13635607 "DTC_CONT_PWR_FAILED_LO" 13635608 "DTC_LSD_PUMP_FAILED_HI" 13635609 "DTC_LSD_PUMP_FAILED_LO" 13635610 "DTC_CHG_A_ENABLE_FAILED_HI" 13635611 "DTC_CHG_A_ENABLE_FAILED_LO" 13635612 "DTC_CHG_B_ENABLE_FAILED_HI" 13635613 "DTC_CHG_B_ENABLE_FAILED_LO" 13635614 "DTC_SW14V_PWR_FAILED_HI" 13635615 "DTC_SW14V_PWR_FAILED_LO" 13635620 "DTC_HSD_A_FAILED_HI" 13635621 "DTC_HSD_A_FAILED_LO" 13635622 "DTC_HSD_B_FAILED_HI" 13635623 "DTC_HSD_B_FAILED_LO" 13692968 "DTC_CONT_HPWR_FAILED_HI" 13692969 "DTC_CONT_HPWR_FAILED_LO" 13692970 "DTC_CONT_HPWR_OOR_HI" 13692971 "DTC_CONT_HPWR_OOR_LO" 13635616 "DTC_5V_PWR_OOR_HI" 13635617 "DTC_5V_PWR_OOR_LO" 14606336 "DTC_NVM_WRITE_TO" 14606337 "DTC_NVM_READ_TO" 14614528 "DTC_SPI_DIG_POT_FAULT" ;
VAL_ 1120 bcm_dtc_018 0 " - " 11276288 "DTC_VEPO" 11276289 "DTC_HSC_MISSING" 11460608 "DTC_NVM_SOC" 11460609 "DTC_NVM_KOT" 11460610 "DTC_NVM_DTC" 11460611 "DTC_NVM_SOC_CORRECTION" 11460612 "DTC_NVM_APP_SCRATCHPAD" 11517962 "DTC_LOOPTIME_TASK_A" 11517963 "DTC_LOOPTIME_TASK_B" 11517964 "DTC_LOOPTIME_TASK_C" 11517965 "DTC_LOOPTIME_TASK_D" 11517966 "DTC_LOOPTIME_TASK_E" 11517967 "DTC_LOOPTIME_TASK_F" 11323904 "DTC_INTERLOCK_A_FAILED_LOW" 11323905 "DTC_INTERLOCK_A_FAILED_HIGH" 11324160 "DTC_INTERLOCK_B_FAILED_LOW" 11324161 "DTC_INTERLOCK_B_FAILED_HIGH" 15728640 "DTC_EPO" 16498688 "DTC_BRUSA_MISSING" 16498689 "DTC_BRUSA_IDC" 16498690 "DTC_BRUSA_REQ_VS_CMD" 16433152 "DTC_AKERWADE_MISSING" 16433153 "DTC_AKERWADE_IDC" 16433154 "DTC_AKERWADE_REQ_VS_CMD" 16564224 "DTC_CHGLEAR_MISSING" 16564225 "DTC_CHGLEAR_IDC" 16564226 "DTC_CHGLEAR_REQ_VS_CMD" 16522240 "DTC_CSM_MISSING" 16522752 "DTC_CSM_VBAT" 16522753 "DTC_CSM_VPOS" 16522754 "DTC_CSM_VNEG" 16522755 "DTC_CSM_CPOS" 16522756 "DTC_CSM_CNEG" 16522757 "DTC_CSM_APOS" 16522758 "DTC_CSM_ANEG" 16522759 "DTC_CSM_FUSE_HI" 16522760 "DTC_CSM_FUSE_LO" 16521728 "DTC_CSM_ASIC" 16521729 "DTC_CSM_AILO" 16521730 "DTC_CSM_AIHI" 16520957 "DTC_LEAKAGE_DETECT_FAULT" 16522444 "DTC_REALTIMECLOCK_FAULT" 16520945 "DTC_CSM_LEAK_FAIL_CALC" 16520946 "DTC_CSM_LEAK_FAIL_HW" 16520947 "DTC_CSM_LEAK_EXT_SHORT" 16520948 "DTC_CSM_LEAK_MID_PACK_SHORT" 16520949 "DTC_CSM_LEAK_ERROR" 16520950 "DTC_CSM_LEAK_UNKNOWN" 16523008 "DTC_CSM_VER_MISMATCH" 16523009 "DTC_CSM_DTC_SET" 16523010 "DTC_CSM_CAL_FAULT" 16560128 "DTC_IBAT_MISMATCH" 16576512 "DTC_DIS_MAX_I2T" 16576513 "DTC_CHG_MAX_I2T" 16576768 "DTC_DIS_WARNING_I2T" 16576769 "DTC_CHG_WARNING_I2T" 11296784 "DTC_SAEJ1772_PROX_DECT_OOR_HI" 11296785 "DTC_SAEJ1772_PROX_DECT_OOR_LO" 11296800 "DTC_SAEJ1772_PILOT_PWM_OOR_HI" 11296801 "DTC_SAEJ1772_PILOT_PWM_OOR_LO" 11296802 "DTC_SAEJ1772_PILOT_PWM_DIG_COMM" 11296803 "DTC_SAEJ1772_PILOT_PWM_IR_ERR" 16175360 "DTC_FGD1_NO_SENSOR" 16175361 "DTC_FGD1_OOR_HI" 16175362 "DTC_FGD1_OOR_LO" 16175363 "DTC_FGD1_FAULT" 16175616 "DTC_FGD2_NO_SENSOR" 16175617 "DTC_FGD2_OOR_HI" 16175618 "DTC_FGD2_OOR_LO" 16175619 "DTC_FGD2_FAULT" 16171008 "DTC_CONT_OPEN" 16171009 "DTC_CONT_CLOSE" 16171010 "DTC_CONT_OPEN_CURRENT" 16171264 "DTC_CONT_CLOSE_ON_RESET" 16171265 "DTC_CONT_CLOSE_SIG_FAILED" 16171520 "DTC_PRECHARGE_TIMEOUT" 16171777 "DTC_CONT_MPOS_WELD_AT_SU" 16171778 "DTC_CONT_MNEG_WELD_AT_SU" 16171780 "DTC_CONT_CPOS_WELD_AT_SU" 16171781 "DTC_CONT_CNEG_WELD_AT_SU" 16171782 "DTC_CONT_ANEG_WELD_AT_SU" 16171783 "DTC_CONT_APOS_WELD_AT_SU" 16172033 "DTC_CONT_MPOS_WELD_AT_SD" 16172034 "DTC_CONT_MNEG_WELD_AT_SD" 16172036 "DTC_CONT_CPOS_WELD_AT_SD" 16172037 "DTC_CONT_CNEG_WELD_AT_SD" 16172038 "DTC_CONT_ANEG_WELD_AT_SD" 16172039 "DTC_CONT_APOS_WELD_AT_SD" 16172289 "DTC_CONT_MPOS_OPEN" 16172290 "DTC_CONT_MNEG_OPEN" 16172291 "DTC_CONT_MPRE_OPEN" 16172292 "DTC_CONT_CPOS_OPEN" 16172293 "DTC_CONT_CNEG_OPEN" 16172294 "DTC_CONT_APOS_OPEN" 16172295 "DTC_CONT_ANEG_OPEN" 16172545 "DTC_CONT_MPOS_VDIF" 16172546 "DTC_CONT_MNEG_VDIF" 16172548 "DTC_CONT_CPOS_VDIF" 16172549 "DTC_CONT_CNEG_VDIF" 16172550 "DTC_CONT_APOS_VDIF" 16172551 "DTC_CONT_ANEG_VDIF" 16174848 "DTC_HVIL" 16174849 "DTC_LVBAT_LO" 16174850 "DTC_LVBAT_HI" 16174851 "DTC_LVBAT_ERR" 16523520 "DTC_LEMLO_OOR_HI" 16523521 "DTC_LEMLO_OOR_LO" 16523522 "DTC_LEMLO_FAULT" 16523776 "DTC_LEMHI_OOR_HI" 16523777 "DTC_LEMHI_OOR_LO" 16523778 "DTC_LEMHI_FAULT" 16496320 "DTC_MBB_TOO_FEW" 16496321 "DTC_MBB_TOO_MANY" 16496352 "DTC_CELL_VMAX_ERR" 16496353 "DTC_CELL_VMIN_ERR" 16496354 "DTC_CELL_VMAX" 16496362 "DTC_CELL_VMAX_SEVERE" 16496355 "DTC_CELL_VMIN" 16496363 "DTC_CELL_VMIN_SEVERE" 16496356 "DTC_MOD_VOLTAGE_COMPARE" 16496336 "DTC_CELL_T_ERR" 16496337 "DTC_CELL_TMAX1" 16496338 "DTC_CELL_TMAX2" 16496339 "DTC_CELL_TMIN" 16497665 "DTC_MBB_01_MISSING" 16497666 "DTC_MBB_02_MISSING" 16497667 "DTC_MBB_03_MISSING" 16497668 "DTC_MBB_04_MISSING" 16497669 "DTC_MBB_05_MISSING" 16497670 "DTC_MBB_06_MISSING" 16497671 "DTC_MBB_07_MISSING" 16497672 "DTC_MBB_08_MISSING" 16497673 "DTC_MBB_09_MISSING" 16497680 "DTC_MBB_10_MISSING" 16497681 "DTC_MBB_11_MISSING" 16497682 "DTC_MBB_12_MISSING" 16497683 "DTC_MBB_13_MISSING" 16497684 "DTC_MBB_14_MISSING" 16497685 "DTC_MBB_15_MISSING" 16497686 "DTC_MBB_16_MISSING" 16497687 "DTC_MBB_17_MISSING" 16497688 "DTC_MBB_18_MISSING" 16497689 "DTC_MBB_19_MISSING" 16497696 "DTC_MBB_20_MISSING" 16497697 "DTC_MBB_21_MISSING" 16497698 "DTC_MBB_22_MISSING" 16497699 "DTC_MBB_23_MISSING" 16497700 "DTC_MBB_24_MISSING" 16498177 "DTC_MBB_01_VFAULT" 16498178 "DTC_MBB_02_VFAULT" 16498179 "DTC_MBB_03_VFAULT" 16498180 "DTC_MBB_04_VFAULT" 16498181 "DTC_MBB_05_VFAULT" 16498182 "DTC_MBB_06_VFAULT" 16498183 "DTC_MBB_07_VFAULT" 16498184 "DTC_MBB_08_VFAULT" 16498185 "DTC_MBB_09_VFAULT" 16498192 "DTC_MBB_10_VFAULT" 16498193 "DTC_MBB_11_VFAULT" 16498194 "DTC_MBB_12_VFAULT" 16498195 "DTC_MBB_13_VFAULT" 16498196 "DTC_MBB_14_VFAULT" 16498197 "DTC_MBB_15_VFAULT" 16498198 "DTC_MBB_16_VFAULT" 16498199 "DTC_MBB_17_VFAULT" 16498200 "DTC_MBB_18_VFAULT" 16498201 "DTC_MBB_19_VFAULT" 16498208 "DTC_MBB_20_VFAULT" 16498209 "DTC_MBB_21_VFAULT" 16498210 "DTC_MBB_22_VFAULT" 16498211 "DTC_MBB_23_VFAULT" 16498212 "DTC_MBB_24_VFAULT" 16497921 "DTC_MBB_01_TFAULT" 16497922 "DTC_MBB_02_TFAULT" 16497923 "DTC_MBB_03_TFAULT" 16497924 "DTC_MBB_04_TFAULT" 16497925 "DTC_MBB_05_TFAULT" 16497926 "DTC_MBB_06_TFAULT" 16497927 "DTC_MBB_07_TFAULT" 16497928 "DTC_MBB_08_TFAULT" 16497929 "DTC_MBB_09_TFAULT" 16497936 "DTC_MBB_10_TFAULT" 16497937 "DTC_MBB_11_TFAULT" 16497938 "DTC_MBB_12_TFAULT" 16497939 "DTC_MBB_13_TFAULT" 16497940 "DTC_MBB_14_TFAULT" 16497941 "DTC_MBB_15_TFAULT" 16497942 "DTC_MBB_16_TFAULT" 16497943 "DTC_MBB_17_TFAULT" 16497944 "DTC_MBB_18_TFAULT" 16497945 "DTC_MBB_19_TFAULT" 16497952 "DTC_MBB_20_TFAULT" 16497953 "DTC_MBB_21_TFAULT" 16497954 "DTC_MBB_22_TFAULT" 16497955 "DTC_MBB_23_TFAULT" 16497956 "DTC_MBB_24_TFAULT" 15785984 "DTC_PRECHARGE_ENERGY" 15785985 "DTC_PRT_FAILED" 15785986 "DTC_PRT_OVERTEMP" 15785987 "DTC_PRT_PROHIBIT" 16556032 "DTC_COOLANT_TEMP_OOR_HI" 16556033 "DTC_COOLANT_TEMP_OOR_LO" 16252928 "DTC_KEY_OFF_TIME_ERROR" 16506880 "DTC_VBAT_MISMATCH" 16506881 "DTC_VBAT_VMAX" 16506882 "DTC_VBAT_VMIN" 16506883 "DTC_PACK_FUSE" 15798544 "DTC_LLS1_OOR_HI" 15798545 "DTC_LLS1_OOR_LO" 15798546 "DTC_LLS1_FAULT" 15798816 "DTC_LLS2_OOR_HI" 15798817 "DTC_LLS2_OOR_LO" 15798818 "DTC_LLS2_FAULT" 14479360 "DTC_CFL_HEARTBEAT" 14479361 "DTC_CFL_FAULT" 14479362 "DTC_CFL_FAULT_LATCH" 13635584 "DTC_CONT_A_FAILED_HI" 13635585 "DTC_CONT_A_FAILED_LO" 13635586 "DTC_CONT_B_FAILED_HI" 13635587 "DTC_CONT_B_FAILED_LO" 13635588 "DTC_CONT_C_FAILED_HI" 13635589 "DTC_CONT_C_FAILED_LO" 13635590 "DTC_CONT_D_FAILED_HI" 13635591 "DTC_CONT_D_FAILED_LO" 13635592 "DTC_CONT_E_FAILED_HI" 13635593 "DTC_CONT_E_FAILED_LO" 13635594 "DTC_CONT_F_FAILED_HI" 13635595 "DTC_CONT_F_FAILED_LO" 13635596 "DTC_CONT_G_FAILED_HI" 13635597 "DTC_CONT_G_FAILED_LO" 13635598 "DTC_LSD_A_FAILED_HI" 13635599 "DTC_LSD_A_FAILED_LO" 13635600 "DTC_LSD_B_FAILED_HI" 13635601 "DTC_LSD_B_FAILED_LO" 13635602 "DTC_LSD_C_FAILED_HI" 13635603 "DTC_LSD_C_FAILED_LO" 13635606 "DTC_CONT_PWR_FAILED_HI" 13635607 "DTC_CONT_PWR_FAILED_LO" 13635608 "DTC_LSD_PUMP_FAILED_HI" 13635609 "DTC_LSD_PUMP_FAILED_LO" 13635610 "DTC_CHG_A_ENABLE_FAILED_HI" 13635611 "DTC_CHG_A_ENABLE_FAILED_LO" 13635612 "DTC_CHG_B_ENABLE_FAILED_HI" 13635613 "DTC_CHG_B_ENABLE_FAILED_LO" 13635614 "DTC_SW14V_PWR_FAILED_HI" 13635615 "DTC_SW14V_PWR_FAILED_LO" 13635620 "DTC_HSD_A_FAILED_HI" 13635621 "DTC_HSD_A_FAILED_LO" 13635622 "DTC_HSD_B_FAILED_HI" 13635623 "DTC_HSD_B_FAILED_LO" 13692968 "DTC_CONT_HPWR_FAILED_HI" 13692969 "DTC_CONT_HPWR_FAILED_LO" 13692970 "DTC_CONT_HPWR_OOR_HI" 13692971 "DTC_CONT_HPWR_OOR_LO" 13635616 "DTC_5V_PWR_OOR_HI" 13635617 "DTC_5V_PWR_OOR_LO" 14606336 "DTC_NVM_WRITE_TO" 14606337 "DTC_NVM_READ_TO" 14614528 "DTC_SPI_DIG_POT_FAULT" ;
